[part 2 of 3: package /ECUCompositionTypes]
AUTOSAR XML (schema 00046)
package /ECUCompositionTypes
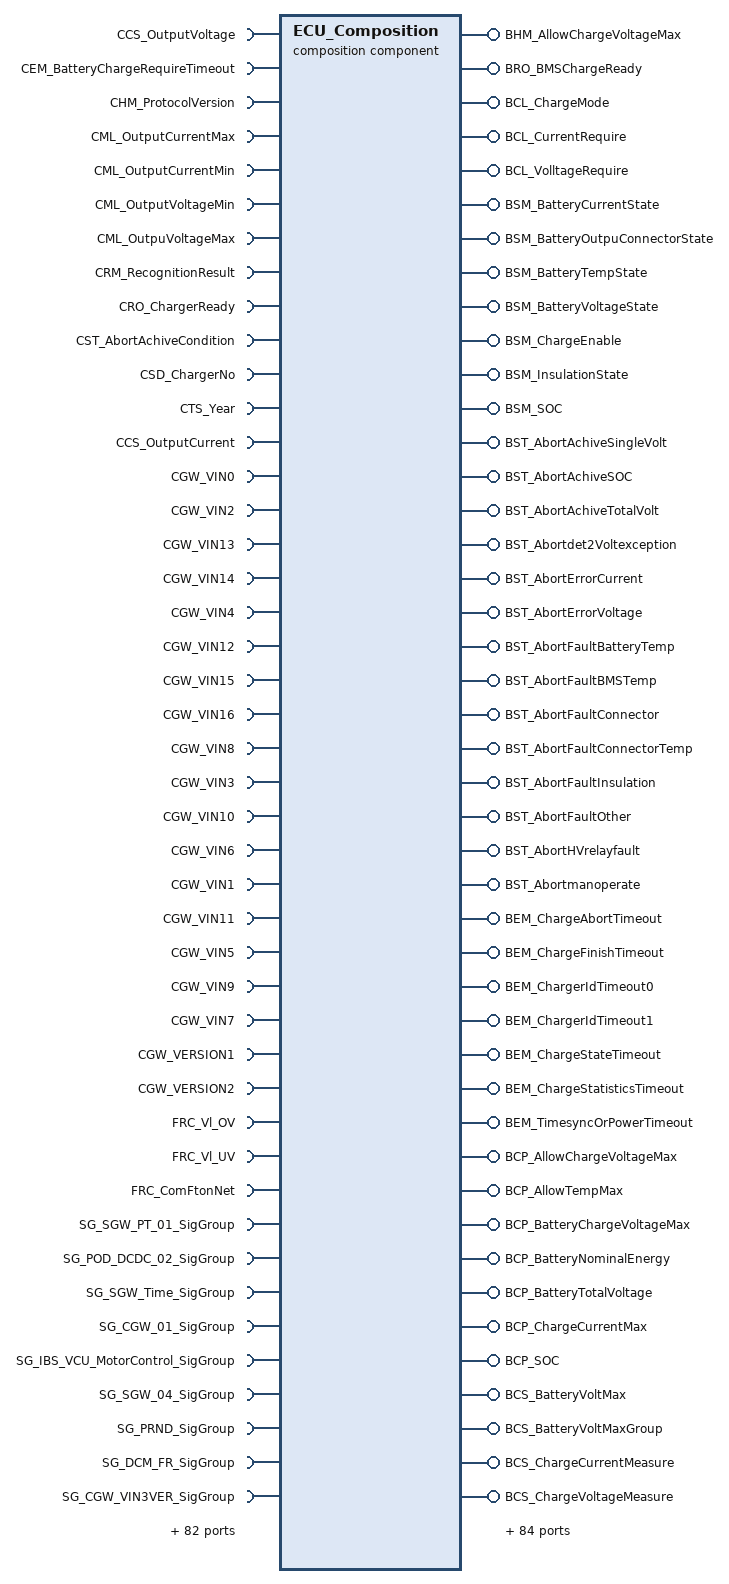
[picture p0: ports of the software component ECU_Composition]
  composition sw component type ECU_Composition
    4 x require port:
      CCS_OutputVoltage: nonqueued-receiver-com-spec{data-element=CCS_OutputVoltage, init-value=0}, required-interface=CCS_OutputVoltage
      CEM_BatteryChargeRequireTimeout: nonqueued-receiver-com-spec{data-element=CEM_BatteryChargeRequireTimeout, init-value=0}, required-interface=CEM_BatteryChargeRequireTimeout
      CHM_ProtocolVersion: nonqueued-receiver-com-spec{data-element=CHM_ProtocolVersion, init-value=0}, required-interface=CHM_ProtocolVersion
      CML_OutputCurrentMax: nonqueued-receiver-com-spec{data-element=CML_OutputCurrentMax, init-value=0}, required-interface=CML_OutputCurrentMax
    33 x provide port:
      BHM_AllowChargeVoltageMax: nonqueued-sender-com-spec{data-element=BHM_AllowChargeVoltageMax, init-value=0}, provided-interface=BHM_AllowChargeVoltageMax
      BRO_BMSChargeReady: nonqueued-sender-com-spec{data-element=BRO_BMSChargeReady, init-value=0}, provided-interface=BRO_BMSChargeReady
      BCL_ChargeMode: nonqueued-sender-com-spec{data-element=BCL_ChargeMode, init-value=0}, provided-interface=BCL_ChargeMode
      BCL_CurrentRequire: nonqueued-sender-com-spec{data-element=BCL_CurrentRequire, init-value=-400}, provided-interface=BCL_CurrentRequire
      BCL_VolltageRequire: nonqueued-sender-com-spec{data-element=BCL_VolltageRequire, init-value=0}, provided-interface=BCL_VolltageRequire
      BSM_BatteryCurrentState: nonqueued-sender-com-spec{data-element=BSM_BatteryCurrentState, init-value=0}, provided-interface=BSM_BatteryCurrentState
      BSM_BatteryOutpuConnectorState: nonqueued-sender-com-spec{data-element=BSM_BatteryOutpuConnectorState, init-value=0}, provided-interface=BSM_BatteryOutpuConnectorState
      BSM_BatteryTempState: nonqueued-sender-com-spec{data-element=BSM_BatteryTempState, init-value=0}, provided-interface=BSM_BatteryTempState
      BSM_BatteryVoltageState: nonqueued-sender-com-spec{data-element=BSM_BatteryVoltageState, init-value=0}, provided-interface=BSM_BatteryVoltageState
      BSM_ChargeEnable: nonqueued-sender-com-spec{data-element=BSM_ChargeEnable, init-value=0}, provided-interface=BSM_ChargeEnable
      BSM_InsulationState: nonqueued-sender-com-spec{data-element=BSM_InsulationState, init-value=0}, provided-interface=BSM_InsulationState
      BSM_SOC: nonqueued-sender-com-spec{data-element=BSM_SOC, init-value=0}, provided-interface=BSM_SOC
      BST_AbortAchiveSingleVolt: nonqueued-sender-com-spec{data-element=BST_AbortAchiveSingleVolt, init-value=0}, provided-interface=BST_AbortAchiveSingleVolt
      BST_AbortAchiveSOC: nonqueued-sender-com-spec{data-element=BST_AbortAchiveSOC, init-value=0}, provided-interface=BST_AbortAchiveSOC
      BST_AbortAchiveTotalVolt: nonqueued-sender-com-spec{data-element=BST_AbortAchiveTotalVolt, init-value=0}, provided-interface=BST_AbortAchiveTotalVolt
      BST_Abortdet2Voltexception: nonqueued-sender-com-spec{data-element=BST_Abortdet2Voltexception, init-value=0}, provided-interface=BST_Abortdet2Voltexception
      BST_AbortErrorCurrent: nonqueued-sender-com-spec{data-element=BST_AbortErrorCurrent, init-value=0}, provided-interface=BST_AbortErrorCurrent
      BST_AbortErrorVoltage: nonqueued-sender-com-spec{data-element=BST_AbortErrorVoltage, init-value=0}, provided-interface=BST_AbortErrorVoltage
      BST_AbortFaultBatteryTemp: nonqueued-sender-com-spec{data-element=BST_AbortFaultBatteryTemp, init-value=0}, provided-interface=BST_AbortFaultBatteryTemp
      BST_AbortFaultBMSTemp: nonqueued-sender-com-spec{data-element=BST_AbortFaultBMSTemp, init-value=0}, provided-interface=BST_AbortFaultBMSTemp
      BST_AbortFaultConnector: nonqueued-sender-com-spec{data-element=BST_AbortFaultConnector, init-value=0}, provided-interface=BST_AbortFaultConnector
      BST_AbortFaultConnectorTemp: nonqueued-sender-com-spec{data-element=BST_AbortFaultConnectorTemp, init-value=0}, provided-interface=BST_AbortFaultConnectorTemp
      BST_AbortFaultInsulation: nonqueued-sender-com-spec{data-element=BST_AbortFaultInsulation, init-value=0}, provided-interface=BST_AbortFaultInsulation
      BST_AbortFaultOther: nonqueued-sender-com-spec{data-element=BST_AbortFaultOther, init-value=0}, provided-interface=BST_AbortFaultOther
      BST_AbortHVrelayfault: nonqueued-sender-com-spec{data-element=BST_AbortHVrelayfault, init-value=0}, provided-interface=BST_AbortHVrelayfault
      BST_Abortmanoperate: nonqueued-sender-com-spec{data-element=BST_Abortmanoperate, init-value=0}, provided-interface=BST_Abortmanoperate
      BEM_ChargeAbortTimeout: nonqueued-sender-com-spec{data-element=BEM_ChargeAbortTimeout, init-value=0}, provided-interface=BEM_ChargeAbortTimeout
      BEM_ChargeFinishTimeout: nonqueued-sender-com-spec{data-element=BEM_ChargeFinishTimeout, init-value=0}, provided-interface=BEM_ChargeFinishTimeout
      BEM_ChargerIdTimeout0: nonqueued-sender-com-spec{data-element=BEM_ChargerIdTimeout0, init-value=0}, provided-interface=BEM_ChargerIdTimeout0
      BEM_ChargerIdTimeout1: nonqueued-sender-com-spec{data-element=BEM_ChargerIdTimeout1, init-value=0}, provided-interface=BEM_ChargerIdTimeout1
      BEM_ChargeStateTimeout: nonqueued-sender-com-spec{data-element=BEM_ChargeStateTimeout, init-value=0}, provided-interface=BEM_ChargeStateTimeout
      BEM_ChargeStatisticsTimeout: nonqueued-sender-com-spec{data-element=BEM_ChargeStatisticsTimeout, init-value=0}, provided-interface=BEM_ChargeStatisticsTimeout
      BEM_TimesyncOrPowerTimeout: nonqueued-sender-com-spec{data-element=BEM_TimesyncOrPowerTimeout, init-value=0}, provided-interface=BEM_TimesyncOrPowerTimeout
    7 x require port:
      CML_OutputCurrentMin: nonqueued-receiver-com-spec{data-element=CML_OutputCurrentMin, init-value=0}, required-interface=CML_OutputCurrentMin
      CML_OutputVoltageMin: nonqueued-receiver-com-spec{data-element=CML_OutputVoltageMin, init-value=0}, required-interface=CML_OutputVoltageMin
      CML_OutpuVoltageMax: nonqueued-receiver-com-spec{data-element=CML_OutpuVoltageMax, init-value=0}, required-interface=CML_OutpuVoltageMax
      CRM_RecognitionResult: nonqueued-receiver-com-spec{data-element=CRM_RecognitionResult, init-value=1}, required-interface=CRM_RecognitionResult
      CRO_ChargerReady: nonqueued-receiver-com-spec{data-element=CRO_ChargerReady, init-value=0}, required-interface=CRO_ChargerReady
      CST_AbortAchiveCondition: nonqueued-receiver-com-spec{data-element=CST_AbortAchiveCondition, init-value=0}, required-interface=CST_AbortAchiveCondition
      CSD_ChargerNo: nonqueued-receiver-com-spec{data-element=CSD_ChargerNo, init-value=1}, required-interface=CSD_ChargerNo
    37 x provide port:
      BCP_AllowChargeVoltageMax: queued-sender-com-spec=BCP_AllowChargeVoltageMax, provided-interface=BCP_AllowChargeVoltageMax
      BCP_AllowTempMax: queued-sender-com-spec=BCP_AllowTempMax, provided-interface=BCP_AllowTempMax
      BCP_BatteryChargeVoltageMax: queued-sender-com-spec=BCP_BatteryChargeVoltageMax, provided-interface=BCP_BatteryChargeVoltageMax
      BCP_BatteryNominalEnergy: queued-sender-com-spec=BCP_BatteryNominalEnergy, provided-interface=BCP_BatteryNominalEnergy
      BCP_BatteryTotalVoltage: queued-sender-com-spec=BCP_BatteryTotalVoltage, provided-interface=BCP_BatteryTotalVoltage
      BCP_ChargeCurrentMax: queued-sender-com-spec=BCP_ChargeCurrentMax, provided-interface=BCP_ChargeCurrentMax
      BCP_SOC: queued-sender-com-spec=BCP_SOC, provided-interface=BCP_SOC
      BCS_BatteryVoltMax: queued-sender-com-spec=BCS_BatteryVoltMax, provided-interface=BCS_BatteryVoltMax
      BCS_BatteryVoltMaxGroup: queued-sender-com-spec=BCS_BatteryVoltMaxGroup, provided-interface=BCS_BatteryVoltMaxGroup
      BCS_ChargeCurrentMeasure: queued-sender-com-spec=BCS_ChargeCurrentMeasure, provided-interface=BCS_ChargeCurrentMeasure
      BCS_ChargeVoltageMeasure: queued-sender-com-spec=BCS_ChargeVoltageMeasure, provided-interface=BCS_ChargeVoltageMeasure
      BCS_EstimatedTimeRemaining: queued-sender-com-spec=BCS_EstimatedTimeRemaining, provided-interface=BCS_EstimatedTimeRemaining
      BCS_SOC: queued-sender-com-spec=BCS_SOC, provided-interface=BCS_SOC
      BRM_BatteryChargeTimes: queued-sender-com-spec=BRM_BatteryChargeTimes, provided-interface=BRM_BatteryChargeTimes
      BRM_BatteryProductDay: queued-sender-com-spec=BRM_BatteryProductDay, provided-interface=BRM_BatteryProductDay
      BRM_BatteryProductMonth: queued-sender-com-spec=BRM_BatteryProductMonth, provided-interface=BRM_BatteryProductMonth
      BRM_BatteryProductYear: queued-sender-com-spec=BRM_BatteryProductYear, provided-interface=BRM_BatteryProductYear
      BRM_BatteryProperty: queued-sender-com-spec=BRM_BatteryProperty, provided-interface=BRM_BatteryProperty
      BRM_BatterySN: queued-sender-com-spec=BRM_BatterySN, provided-interface=BRM_BatterySN
      BRM_BatterySystemRatedCapacity: queued-sender-com-spec=BRM_BatterySystemRatedCapacity, provided-interface=BRM_BatterySystemRatedCapacity
      BRM_BatterySystemRatedVoltage: queued-sender-com-spec=BRM_BatterySystemRatedVoltage, provided-interface=BRM_BatterySystemRatedVoltage
      BRM_BatteryType: queued-sender-com-spec=BRM_BatteryType, provided-interface=BRM_BatteryType
      BRM_Manufacturer: queued-sender-com-spec=BRM_Manufacturer, provided-interface=BRM_Manufacturer
      BRM_ProtocolVersion: queued-sender-com-spec=BRM_ProtocolVersion, provided-interface=BRM_ProtocolVersion
      BRM_VehicleIdByte1_8: queued-sender-com-spec=BRM_VehicleIdByte1_8, provided-interface=BRM_VehicleIdByte1_8
      BRM_VehicleIdByte17: queued-sender-com-spec=BRM_VehicleIdByte17, provided-interface=BRM_VehicleIdByte17
      BRM_VehicleIdByte9_16: queued-sender-com-spec=BRM_VehicleIdByte9_16, provided-interface=BRM_VehicleIdByte9_16
      BSD_AbortSOC: nonqueued-sender-com-spec{data-element=BSD_AbortSOC, init-value=0}, provided-interface=BSD_AbortSOC
      BSD_BatteryTempMax: nonqueued-sender-com-spec{data-element=BSD_BatteryTempMax, init-value=0}, provided-interface=BSD_BatteryTempMax
      BSD_BatteryTempMin: nonqueued-sender-com-spec{data-element=BSD_BatteryTempMin, init-value=0}, provided-interface=BSD_BatteryTempMin
      BSD_BatteryVoltageMax: nonqueued-sender-com-spec{data-element=BSD_BatteryVoltageMax, init-value=0}, provided-interface=BSD_BatteryVoltageMax
      BSD_BatteryVoltageMin: nonqueued-sender-com-spec{data-element=BSD_BatteryVoltageMin, init-value=0}, provided-interface=BSD_BatteryVoltageMin
      BSM_BatteryTempMax: nonqueued-sender-com-spec{data-element=BSM_BatteryTempMax, init-value=0}, provided-interface=BSM_BatteryTempMax
      BSM_BatteryTempMaxNo: nonqueued-sender-com-spec{data-element=BSM_BatteryTempMaxNo, init-value=0}, provided-interface=BSM_BatteryTempMaxNo
      BSM_BatteryTempMin: nonqueued-sender-com-spec{data-element=BSM_BatteryTempMin, init-value=0}, provided-interface=BSM_BatteryTempMin
      BSM_BatteryTempMinNo: nonqueued-sender-com-spec{data-element=BSM_BatteryTempMinNo, init-value=0}, provided-interface=BSM_BatteryTempMinNo
      BSM_BatteryVoltageMaxNo: nonqueued-sender-com-spec{data-element=BSM_BatteryVoltageMaxNo, init-value=0}, provided-interface=BSM_BatteryVoltageMaxNo
    79 x require port:
      CTS_Year: nonqueued-receiver-com-spec{data-element=CTS_Year, init-value=0}, required-interface=CTS_Year
      CCS_OutputCurrent: nonqueued-receiver-com-spec{data-element=CCS_OutputCurrent, init-value=0}, required-interface=CCS_OutputCurrent
      CGW_VIN0: nonqueued-receiver-com-spec{data-element=CGW_VIN0, init-value=0}, required-interface=CGW_VIN0
      CGW_VIN2: nonqueued-receiver-com-spec{data-element=CGW_VIN2, init-value=0}, required-interface=CGW_VIN2
      CGW_VIN13: nonqueued-receiver-com-spec{data-element=CGW_VIN13, init-value=0}, required-interface=CGW_VIN13
      CGW_VIN14: nonqueued-receiver-com-spec{data-element=CGW_VIN14, init-value=0}, required-interface=CGW_VIN14
      CGW_VIN4: nonqueued-receiver-com-spec{data-element=CGW_VIN4, init-value=0}, required-interface=CGW_VIN4
      CGW_VIN12: nonqueued-receiver-com-spec{data-element=CGW_VIN12, init-value=0}, required-interface=CGW_VIN12
      CGW_VIN15: nonqueued-receiver-com-spec{data-element=CGW_VIN15, init-value=0}, required-interface=CGW_VIN15
      CGW_VIN16: nonqueued-receiver-com-spec{data-element=CGW_VIN16, init-value=0}, required-interface=CGW_VIN16
      CGW_VIN8: nonqueued-receiver-com-spec{data-element=CGW_VIN8, init-value=0}, required-interface=CGW_VIN8
      CGW_VIN3: nonqueued-receiver-com-spec{data-element=CGW_VIN3, init-value=0}, required-interface=CGW_VIN3
      CGW_VIN10: nonqueued-receiver-com-spec{data-element=CGW_VIN10, init-value=0}, required-interface=CGW_VIN10
      CGW_VIN6: nonqueued-receiver-com-spec{data-element=CGW_VIN6, init-value=0}, required-interface=CGW_VIN6
      CGW_VIN1: nonqueued-receiver-com-spec{data-element=CGW_VIN1, init-value=0}, required-interface=CGW_VIN1
      CGW_VIN11: nonqueued-receiver-com-spec{data-element=CGW_VIN11, init-value=0}, required-interface=CGW_VIN11
      CGW_VIN5: nonqueued-receiver-com-spec{data-element=CGW_VIN5, init-value=0}, required-interface=CGW_VIN5
      CGW_VIN9: nonqueued-receiver-com-spec{data-element=CGW_VIN9, init-value=0}, required-interface=CGW_VIN9
      CGW_VIN7: nonqueued-receiver-com-spec{data-element=CGW_VIN7, init-value=0}, required-interface=CGW_VIN7
      CGW_VERSION1: nonqueued-receiver-com-spec{data-element=CGW_VERSION1, init-value=0}, required-interface=CGW_VERSION1
      CGW_VERSION2: nonqueued-receiver-com-spec{data-element=CGW_VERSION2, init-value=0}, required-interface=CGW_VERSION2
      FRC_Vl_OV: nonqueued-receiver-com-spec{data-element=FRC_Vl_OV, init-value=1}, required-interface=FRC_Vl_OV
      FRC_Vl_UV: nonqueued-receiver-com-spec{data-element=FRC_Vl_UV, init-value=1}, required-interface=FRC_Vl_UV
      FRC_ComFtonNet: nonqueued-receiver-com-spec{data-element=FRC_ComFtonNet, init-value=1}, required-interface=FRC_ComFtonNet
      SG_SGW_PT_01_SigGroup: nonqueued-receiver-com-spec{data-element=SG_SGW_PT_01_SigGroup, init-value=fields=[IVI_AppointChargeCmd:0, IVI_ForwardVmaxlimitSw:0, IVI_LockACPlug:0, IVI_LV_LimitPop:0]}, required-interface=SG_SGW_PT_01_SigGroup
      SG_POD_DCDC_02_SigGroup: nonqueued-receiver-com-spec{data-element=SG_POD_DCDC_02_SigGroup, init-value=fields=[POD_DCDC_FaultLevel:0, POD_DCDC_Side2Overtempfault:0]}, required-interface=SG_POD_DCDC_02_SigGroup
      SG_SGW_Time_SigGroup: nonqueued-receiver-com-spec{data-element=SG_SGW_Time_SigGroup, init-value=fields=[SGW_TimeInfoDay:1, SGW_TimeInfoHour:0, SGW_TimeInfoMinute:0, SGW_TimeInfoMonth:1, SGW_TimeInfoSecond:0, SGW_TimeInfoYear:0, SGW_TimeValid:1]}, required-interface=SG_SGW_Time_SigGroup
      SG_CGW_01_SigGroup: nonqueued-receiver-com-spec{data-element=SG_CGW_01_SigGroup, uses-end-to-end-protection=true, enable-update=true, init-value=fields=[CGW_VehicleState:0, Checksum_278:0, MessageCounter_278:0]}, required-interface=SG_CGW_01_SigGroup
      SG_IBS_VCU_MotorControl_SigGroup: nonqueued-receiver-com-spec{data-element=SG_IBS_VCU_MotorControl_SigGroup, uses-end-to-end-protection=true, enable-update=true, init-value=fields=[IBS_WLTorqueIncrReq:0, IBS_WLTorqueIncrReqSts:0, IBS_WLTorqueRedReq:0, IBS_WLTorqueRedReqSts:0, Checksum_090:0, MessageCounter_090:0]}, required-interface=SG_IBS_VCU_MotorControl_SigGroup
      SG_SGW_04_SigGroup: nonqueued-receiver-com-spec{data-element=SG_SGW_04_SigGroup, init-value=fields=SGW_RemoteHVCtrlReq:0}, required-interface=SG_SGW_04_SigGroup
      SG_PRND_SigGroup: nonqueued-receiver-com-spec{data-element=SG_PRND_SigGroup, uses-end-to-end-protection=true, enable-update=true, init-value=fields=[Checksum_248:0, MessageCounter_248:0, PRND_Pbutton:0, PRND_Pbutton_FaultSts:0, PRND_RNDbutton:0, PRND_RNDbutton_FaultSts:0]}, required-interface=SG_PRND_SigGroup
      SG_DCM_FR_SigGroup: nonqueued-receiver-com-spec{data-element=SG_DCM_FR_SigGroup, init-value=fields=DCM_FR_DoorFRSts:0}, required-interface=SG_DCM_FR_SigGroup
      SG_CGW_VIN3VER_SigGroup: nonqueued-receiver-com-spec{data-element=SG_CGW_VIN3VER_SigGroup, init-value=fields=[CGW_VERSION1:0, CGW_VERSION2:0, CGW_VIN16:0]}, required-interface=SG_CGW_VIN3VER_SigGroup
      SG_BMS_ErrorInfo_SigGroup: nonqueued-receiver-com-spec{data-element=SG_BMS_ErrorInfo_SigGroup, init-value=fields=[BMS_ErrorCellHighTemp:0, BMS_ErrorCellLowTemp:0, BMS_ErrorCellOverVolt:0, BMS_ErrorCellUnderVolt:0, BMS_ErrorChaCurrentOver:0, BMS_ErrorHighSoc:0, BMS_ErrorLowSoc:0, BMS_ErrorPreChaFailed:0, BMS_ErrorRelay:0, BMS_ThermalRunawayFault:0]}, required-interface=SG_BMS_ErrorInfo_SigGroup
      SG_CGW_VIN2_SigGroup: nonqueued-receiver-com-spec{data-element=SG_CGW_VIN2_SigGroup, init-value=fields=[CGW_VIN8:0, CGW_VIN9:0, CGW_VIN10:0, CGW_VIN11:0, CGW_VIN12:0, CGW_VIN13:0, CGW_VIN14:0, CGW_VIN15:0]}, required-interface=SG_CGW_VIN2_SigGroup
      SG_BMS_status_02_SigGroup: nonqueued-receiver-com-spec{data-element=SG_BMS_status_02_SigGroup, init-value=fields=[BMS_BattCurr:0, BMS_BattVolt:0, BMS_Heatcurrent:0]}, required-interface=SG_BMS_status_02_SigGroup
      SG_SGW_17_SigGroup: nonqueued-receiver-com-spec{data-element=SG_SGW_17_SigGroup, init-value=fields=SGW_BLESystemReadyReq:0}, required-interface=SG_SGW_17_SigGroup
      SG_BMS_PRO_SigGroup: nonqueued-receiver-com-spec{data-element=SG_BMS_PRO_SigGroup, init-value=fields=[BMS_BatProDatDay:0, BMS_BatProDatMonth:0, BMS_BatProDatYear:0]}, required-interface=SG_BMS_PRO_SigGroup
      SG_ACU_01_SigGroup: nonqueued-receiver-com-spec{data-element=SG_ACU_01_SigGroup, uses-end-to-end-protection=true, enable-update=true, init-value=fields=[ACU_YawRate:30000, ACU_YawRateStatus:0, Checksum_0F5:0, MessageCounter_0F5:0]}, required-interface=SG_ACU_01_SigGroup
      SG_ADCU_DA_SigGroup: nonqueued-receiver-com-spec{data-element=SG_ADCU_DA_SigGroup, uses-end-to-end-protection=true, enable-update=true, init-value=fields=[ADCU_DA_Mode:0, Checksum_0E6:0, MessageCounter_0E6:0]}, required-interface=SG_ADCU_DA_SigGroup
      SG_POD_Status_02_SigGroup: nonqueued-receiver-com-spec{data-element=SG_POD_Status_02_SigGroup, init-value=fields=[POD_DCPortInletTempAValid:0, POD_DCPortInletTempBValid:0, POD_DCPosRelayState:1]}, required-interface=SG_POD_Status_02_SigGroup
      SG_CGW_VIN1_SigGroup: nonqueued-receiver-com-spec{data-element=SG_CGW_VIN1_SigGroup, init-value=fields=[CGW_VIN0:0, CGW_VIN1:0, CGW_VIN2:0, CGW_VIN3:0, CGW_VIN4:0, CGW_VIN5:0, CGW_VIN6:0, CGW_VIN7:0]}, required-interface=SG_CGW_VIN1_SigGroup
      SG_IVI_01_SigGroup: nonqueued-receiver-com-spec{data-element=SG_IVI_01_SigGroup, uses-end-to-end-protection=true, enable-update=true, init-value=fields=IVI_GearRequest:0}, required-interface=SG_IVI_01_SigGroup
      SG_MCU_02_SigGroup: nonqueued-receiver-com-spec{data-element=SG_MCU_02_SigGroup, init-value=fields=[MCU_BDmpCActv:0, MCU_VCUWorkMode:0]}, required-interface=SG_MCU_02_SigGroup
      SG_MCU_Temperature_02_SigGroup: nonqueued-receiver-com-spec{data-element=SG_MCU_Temperature_02_SigGroup, init-value=fields=MCU_TempStatus:0}, required-interface=SG_MCU_Temperature_02_SigGroup
      SG_BMS_Charge_01_SigGroup: nonqueued-receiver-com-spec{data-element=SG_BMS_Charge_01_SigGroup, init-value=fields=[BMS_AllowChagCurrent:0, BMS_MaxChagVoltage:0, BMS_RemChagTime:0]}, required-interface=SG_BMS_Charge_01_SigGroup
      SG_CGW_02_SigGroup: nonqueued-receiver-com-spec{data-element=SG_CGW_02_SigGroup, init-value=fields=[CGW_ADCUSts:0, CGW_BCMSts:0, CGW_BMSSts:0, CGW_CBMSts:0, CGW_CGWSts:0, CGW_DCM_FLSts:0, CGW_DCM_FRSts:0, CGW_DCM_RLSts:0, CGW_DCM_RRSts:0, CGW_HLLSts:0, CGW_HLRSts:0, CGW_HOD_HeatingSts:0, CGW_IVISts:0, CGW_MFP_FCSts:0, CGW_MFP_RCSts:0, CGW_PRNDSts:0, CGW_SCU_LSts:0, CGW_SCU_RSts:0, CGW_SGWSts:0, CGW_SwichesSts:0, CGW_SWPSts:0, CGW_VCUSts:0]}, required-interface=SG_CGW_02_SigGroup
      SG_POD_OBC_STATUS_02_SigGroup: nonqueued-receiver-com-spec{data-element=SG_POD_OBC_STATUS_02_SigGroup, init-value=fields=[POD_OBC_ChrgOutpPwrAvl:0, POD_OBC_OutputDCChargeCurrent:0, POD_OBC_OutputDCChargeVoltage:0]}, required-interface=SG_POD_OBC_STATUS_02_SigGroup
      SG_BMS_TCU_SigGroup: nonqueued-receiver-com-spec{data-element=SG_BMS_TCU_SigGroup, init-value=fields=[BMS_AllowCellTemperature:255, BMS_KeepWarmRequest:0, BMS_KeepWarmStatus:0, BMS_RTC_Request:0]}, required-interface=SG_BMS_TCU_SigGroup
      SG_ADCU_APS_02_SigGroup: nonqueued-receiver-com-spec{data-element=SG_ADCU_APS_02_SigGroup, init-value=fields=ADCU_RemoteParkingMode:0}, required-interface=SG_ADCU_APS_02_SigGroup
      SG_MCU_FailureCode_SigGroup: nonqueued-receiver-com-spec{data-element=SG_MCU_FailureCode_SigGroup, uses-end-to-end-protection=true, enable-update=true, init-value=fields=[Checksum_253:0, MCU_FaultLevel:0, MessageCounter_253:0]}, required-interface=SG_MCU_FailureCode_SigGroup
      SG_IVI_OdometerInfor_SigGroup: nonqueued-receiver-com-spec{data-element=SG_IVI_OdometerInfor_SigGroup, init-value=fields=IVI_OdometerInfor:0}, required-interface=SG_IVI_OdometerInfor_SigGroup
      SG_DCM_RL_SigGroup: nonqueued-receiver-com-spec{data-element=SG_DCM_RL_SigGroup, uses-end-to-end-protection=true, enable-update=true, init-value=fields=DCM_RL_DoorRLSts:0}, required-interface=SG_DCM_RL_SigGroup
      SG_MCU_Temperature_01_SigGroup: nonqueued-receiver-com-spec{data-element=SG_MCU_Temperature_01_SigGroup, init-value=fields=MCU_IGBTTempMax:0}, required-interface=SG_MCU_Temperature_01_SigGroup
      SG_POD_DCDC_01_SigGroup: nonqueued-receiver-com-spec{data-element=SG_POD_DCDC_01_SigGroup, init-value=fields=[POD_DCDC_HVInputCurrent:0, POD_DCDC_HVInputVoltage:0, POD_DCDC_WorkMode:0]}, required-interface=SG_POD_DCDC_01_SigGroup
      SG_BMS_BatInfor_02_SigGroup: nonqueued-receiver-com-spec{data-element=SG_BMS_BatInfor_02_SigGroup, init-value=fields=BMS_BatSupName:8 x 0}, required-interface=SG_BMS_BatInfor_02_SigGroup
      SG_BMS_status_03_SigGroup: nonqueued-receiver-com-spec{data-element=SG_BMS_status_03_SigGroup, init-value=fields=[BMS_DisplaySOC:0, BMS_LinkVoltage:0, BMS_PackVoltage:0]}, required-interface=SG_BMS_status_03_SigGroup
      SG_DCM_FR_02_SigGroup: nonqueued-receiver-com-spec{data-element=SG_DCM_FR_02_SigGroup, init-value=fields=[DCM_FR_AmbientTemperature:70, DCM_FR_AmbientTemperatureValid:0]}, required-interface=SG_DCM_FR_02_SigGroup
      SG_IBS_Torque_SigGroup: nonqueued-receiver-com-spec{data-element=SG_IBS_Torque_SigGroup, uses-end-to-end-protection=true, enable-update=true, init-value=fields=[Checksum_0B9:0, IBS_RBSStatus:0, IBS_TargetGearReq:0, IBS_WLTorqueAPSReq:0, IBS_WLTorqueAPSReqValid:0, IBS_WLTorqueRBSReq:0, IBS_WLTorqueRBSReqValid:0, MessageCounter_0B9:0, IBS_VCU_DecelerationReqActive:0]}, required-interface=SG_IBS_Torque_SigGroup
      SG_POD_OBC_CHRGSTATION_SigGroup: nonqueued-receiver-com-spec{data-element=SG_POD_OBC_CHRGSTATION_SigGroup, init-value=fields=[POD_OBC_CCCurrentLimit:0, POD_OBC_CCStatus:0, POD_OBC_ChargCapacibility:0, POD_OBC_CPCurrentLimit:0, POD_OBC_CPDuty:0, POD_OBC_CPStatus:0, POD_OBC_EMLockState:0, POD_OBC_OBCMaxPermOutpCrrt:0, POD_OBC_S2State:1, POD_OBC_WorkMode:0]}, required-interface=SG_POD_OBC_CHRGSTATION_SigGroup
      SG_POD_OBC_STATUS_03_SigGroup: nonqueued-receiver-com-spec{data-element=SG_POD_OBC_STATUS_03_SigGroup, init-value=fields=[POD_OBC_FaultLevel:0, POD_OBC_Side1Overtempfault:0, POD_OBC_Side2Overtempfault:0, POD_OBC_PrimarySideTemp:0, POD_OBC_SecondarySideTemp:0]}, required-interface=SG_POD_OBC_STATUS_03_SigGroup
      SG_POD_OBC_STATUS_04_SigGroup: nonqueued-receiver-com-spec{data-element=SG_POD_OBC_STATUS_04_SigGroup, init-value=fields=[POD_OBC_InputACCurrent_R:0, POD_OBC_InputACCurrent_S:0, POD_OBC_InputACCurrent_T:0, POD_OBC_InputACVoltage_R:0, POD_OBC_InputACVoltage_S:0, POD_OBC_InputACVoltage_T:0]}, required-interface=SG_POD_OBC_STATUS_04_SigGroup
      SG_ACU_02_SigGroup: nonqueued-receiver-com-spec{data-element=SG_ACU_02_SigGroup, uses-end-to-end-protection=true, enable-update=true, init-value=fields=[ACU_LatA:4905, ACU_LatAStatus:0, ACU_LgtA:4905, ACU_LgtAStatus:0, Checksum_0F6:0, MessageCounter_0F6:0]}, required-interface=SG_ACU_02_SigGroup
      SG_POD_Status_01_SigGroup: nonqueued-receiver-com-spec{data-element=SG_POD_Status_01_SigGroup, init-value=fields=[POD_DCFCVoltage:0, POD_DCInletTempA:0, POD_DCInletTempB:0]}, required-interface=SG_POD_Status_01_SigGroup
      SG_BMS_VersionInfor_SigGroup: nonqueued-receiver-com-spec{data-element=SG_BMS_VersionInfor_SigGroup, init-value=fields=[BMS_BatProRights:0, BMS_ComVersion:0]}, required-interface=SG_BMS_VersionInfor_SigGroup
      SG_BMS_BatInfor_01_SigGroup: nonqueued-receiver-com-spec{data-element=SG_BMS_BatInfor_01_SigGroup, init-value=fields=[BMS_BatType:0, BMS_CellNumbers:0, BMS_RatBatVoltage:0, BMS_RatCapacity:0, BMS_RatEnergy:0]}, required-interface=SG_BMS_BatInfor_01_SigGroup
      SG_MCU_DeratingStatus_SigGroup: nonqueued-receiver-com-spec{data-element=SG_MCU_DeratingStatus_SigGroup, init-value=fields=[MCU_TrqAbsMax:1023, MCU_TrqAbsMin:1023]}, required-interface=SG_MCU_DeratingStatus_SigGroup
      SG_SGW_VCU_01_SigGroup: nonqueued-receiver-com-spec{data-element=SG_SGW_VCU_01_SigGroup, init-value=fields=[IVI_DriveModeSet:0, IVI_DschrgOnOffSet:0, IVI_ForwardVmaxAllowed:0, IVI_MaxChrgSocSet:254, IVI_V2LidisSet:254]}, required-interface=SG_SGW_VCU_01_SigGroup
      SG_SGW_IBS_01_SigGroup: nonqueued-receiver-com-spec{data-element=SG_SGW_IBS_01_SigGroup, uses-end-to-end-protection=true, enable-update=true, init-value=fields=[IVI_BrakeCompensateCmd:0, IVI_CRLevelSet:0]}, required-interface=SG_SGW_IBS_01_SigGroup
      SG_DCM_RR_SigGroup: nonqueued-receiver-com-spec{data-element=SG_DCM_RR_SigGroup, uses-end-to-end-protection=true, enable-update=true, init-value=fields=DCM_RR_DoorRRSts:0}, required-interface=SG_DCM_RR_SigGroup
      SG_BMS_DIRelayState_SigGroup: nonqueued-receiver-com-spec{data-element=SG_BMS_DIRelayState_SigGroup, init-value=fields=[BMS_NegRelayStatus:0, BMS_PosRelayStatus:0, BMS_PreRelayStatus:0, BMS_PTC_VoltageValue:0, BMS_PTCRelayStatus:0]}, required-interface=SG_BMS_DIRelayState_SigGroup
      SG_TCU_02_SigGroup: nonqueued-receiver-com-spec{data-element=SG_TCU_02_SigGroup, init-value=fields=[TCU_HVCHHighVoltage:0, TCU_HVCHHVDCCurrent:0]}, required-interface=SG_TCU_02_SigGroup
      SG_SGW_16_SigGroup: nonqueued-receiver-com-spec{data-element=SG_SGW_16_SigGroup, init-value=fields=IVI_VrState:0}, required-interface=SG_SGW_16_SigGroup
      SG_APTC_TCU_SigGroup: nonqueued-receiver-com-spec{data-element=SG_APTC_TCU_SigGroup, init-value=fields=APTC_PowerConsumption:0}, required-interface=SG_APTC_TCU_SigGroup
      SG_TCU_01_SigGroup: nonqueued-receiver-com-spec{data-element=SG_TCU_01_SigGroup, init-value=fields=[TCU_HVPwrState:0, TCU_TMSFaultLevel:0, TCU_TMSTotalPwrCnsmp:0, TCU_TMSTotoalPwrReq:0]}, required-interface=SG_TCU_01_SigGroup
      SG_BMS_BatInfor_03_SigGroup: nonqueued-receiver-com-spec{data-element=SG_BMS_BatInfor_03_SigGroup, init-value=fields=BMS_RemainCapacity:0}, required-interface=SG_BMS_BatInfor_03_SigGroup
      SG_BMS_Charge_03_SigGroup: nonqueued-receiver-com-spec{data-element=SG_BMS_Charge_03_SigGroup, init-value=fields=[BMS_BatChagSum:0, BMS_SingChgkwh:0, BMS_SumChgkwh:0]}, required-interface=SG_BMS_Charge_03_SigGroup
      SG_BMS_Charge_02_SigGroup: nonqueued-receiver-com-spec{data-element=SG_BMS_Charge_02_SigGroup, init-value=fields=[BMS_AbortAchivesetValue:0, BMS_AbortAchiveSingleVolt:0, BMS_AbortAchiveTotalVolt:0, BMS_AbortErrorCurrent:0, BMS_AbortErrorVoltage:0, BMS_AbortFaultBatteryTemp:0, BMS_AbortFaultBMSTemp:0, BMS_ChagComplete:0, BMS_ChargeRequest:0, BMS_DCChgMode:0]}, required-interface=SG_BMS_Charge_02_SigGroup
      SG_EVCOM_State_01_SigGroup: nonqueued-receiver-com-spec{data-element=SG_EVCOM_State_01_SigGroup, init-value=fields=[EVCOM_CompActlCnsmpCur:0, EVCOM_CompActlPwrCnsmp:0]}, required-interface=SG_EVCOM_State_01_SigGroup
    19 x provide port:
      SG_VCU_HMIsignals_02_SigGroup: nonqueued-sender-com-spec{data-element=SG_VCU_HMIsignals_02_SigGroup, uses-end-to-end-protection=true, init-value=fields=[Checksum_318:0, MessageCounter_318:0, VCU_DischargeEndSoc:50, VCU_Display_Cur:0, VCU_Display_Power:0, VCU_ForwardVmaxAllowed:0, VCU_maxChargeSOC:255, VCU_MCU_FaultLampReq:0, VCU_SystemReady:0]}, provided-interface=SG_VCU_HMIsignals_02_SigGroup
      SG_VCU_TCU_SigGroup: nonqueued-sender-com-spec{data-element=SG_VCU_TCU_SigGroup, init-value=fields=[VCU_RequestedModeTCU:0, VCU_TCUPowerAllowed:0]}, provided-interface=SG_VCU_TCU_SigGroup
      SG_VCU_IBS_01_SigGroup: nonqueued-sender-com-spec{data-element=SG_VCU_IBS_01_SigGroup, uses-end-to-end-protection=true, init-value=fields=[Checksum_094:0, MessageCounter_094:0, VCU_MotorActualTorque:0, VCU_MotorActualTorqueValid:0, VCU_OPStandstillReq:0, VCU_WheelTrqACT:0, VCU_WheelTrqACTValid:0]}, provided-interface=SG_VCU_IBS_01_SigGroup
      SG_VCU_03_SigGroup: nonqueued-sender-com-spec{data-element=SG_VCU_03_SigGroup, init-value=fields=[VCU_BrakeCompensateStatus:0, VCU_ChargeProcessComment:0, VCU_DCFCCurrent:0, VCU_EnergyV2L:0, VCU_MemoryChargeFault:0]}, provided-interface=SG_VCU_03_SigGroup
      SG_VCU_BMS_SigGroup: nonqueued-sender-com-spec{data-element=SG_VCU_BMS_SigGroup, uses-end-to-end-protection=true, init-value=fields=[Checksum_0D1:0, MessageCounter_0D1:0, VCU_ActDriveMode:0, VCU_BMSTargetThermLevel:0, VCU_DrvModSwitchWarn:0, VCU_HVStatus:0, VCU_LimitLevel:0, VCU_RegenBrakeLightRequest:0, VCU_RegenBrakeLightReqVld:0, VCU_RequestedModeBMS:0, VCU_BMS_Control_of_PosRelay:0, VCU_ChargeStatus:0, VCU_IsoMeasurementSwitch:1]}, provided-interface=SG_VCU_BMS_SigGroup
      SG_VCU_DiagInfor_SigGroup: nonqueued-sender-com-spec{data-element=SG_VCU_DiagInfor_SigGroup, init-value=fields=VCU_DTC_Number:0}, provided-interface=SG_VCU_DiagInfor_SigGroup_2
      SG_VCU_05_SigGroup: nonqueued-sender-com-spec{data-element=SG_VCU_05_SigGroup, init-value=fields=[VCU_MaximumOutputCurrent:0, VCU_MaximumOutputVoltage:0, VCU_MinimumOutputCurrent:0, VCU_MinimumOutputVoltage:0]}, provided-interface=SG_VCU_05_SigGroup
      SG_VCU_Chassis_01_SigGroup: nonqueued-sender-com-spec{data-element=SG_VCU_Chassis_01_SigGroup, uses-end-to-end-protection=true, init-value=fields=[Checksum_0D3:0, MessageCounter_0D3:0, VCU_ADASOverride:0, VCU_APSTorqueRequestActive:0, VCU_APSTorqueRequestAvailable:0, VCU_BrakeCompensateWarn:0, VCU_DecelerationReq:0, VCU_DecelerationReqactive:0, VCU_DriverTorqueRequest:0, VCU_EnergyManagementWarn:0, VCU_RegenTorqueCap:0, VCU_RegenTorqueCapValid:0, VCU_RegStatus:0, VCU_TorqueRequestActive:0, VCU_TorqueRequestAvailable:0]}, provided-interface=SG_VCU_Chassis_01_SigGroup
      SG_VCU_MCU_02_SigGroup: nonqueued-sender-com-spec{data-element=SG_VCU_MCU_02_SigGroup, init-value=fields=[VCU_MaxSpdLimit:32767, VCU_MCUActHeatPwr:0, VCU_MotorSpdReq:32767]}, provided-interface=SG_VCU_MCU_02_SigGroup
      SG_VCU_SynReq_01_SigGroup: nonqueued-sender-com-spec{data-element=SG_VCU_SynReq_01_SigGroup, init-value=fields=VCU_SynRequest:16777215}, provided-interface=SG_VCU_SynReq_01_SigGroup
      SG_VCU_MCU_05_SigGroup: nonqueued-sender-com-spec{data-element=SG_VCU_MCU_05_SigGroup, init-value=fields=[VCU_MaxTorqueGradient:0, VCU_MaxTorqueLimit:0, VCU_MinTorqueLimit:0, VCU_CreepTorque:0, VCU_SpdLimitActTorque:0]}, provided-interface=SG_VCU_MCU_05_SigGroup
      SG_VCU_POD_SigGroup: nonqueued-sender-com-spec{data-element=SG_VCU_POD_SigGroup, init-value=fields=[VCU_Enable_DC_Relay:1, VCU_EnableOBC:0, VCU_OBC_ChargeCurrentCommand:0, VCU_OBC_Control_of_em_lock:1, VCU_OBC_Control_of_S2_SW:1]}, provided-interface=SG_VCU_POD_SigGroup
      SG_VCU_06_SigGroup: nonqueued-sender-com-spec{data-element=SG_VCU_06_SigGroup, init-value=fields=[VCU_ChargeEnergy:0, VCU_ChargeTime:0, VCU_DisChgPowerLimit:0, VCU_DisplayMileage:0, VCU_MCUPower:0, VCU_PermitPackPTC:0]}, provided-interface=SG_VCU_06_SigGroup
      SG_VCU_02_SigGroup: nonqueued-sender-com-spec{data-element=SG_VCU_02_SigGroup, init-value=fields=[VCU_BS_IBSBatSOC:80, VCU_BS_LV_Batt:0, VCU_BS_Current:0, VCU_BS_IndicatorSts:0, VCU_WakeUpStatus:0]}, provided-interface=SG_VCU_02_SigGroup
      SG_VCU_04_SigGroup: nonqueued-sender-com-spec{data-element=SG_VCU_04_SigGroup, init-value=fields=[VCU_ForwardVmaxlimitStatus:0, VCU_ManuallyUnlockComment:0]}, provided-interface=SG_VCU_04_SigGroup
      SG_VCU_PlugInChrgInfo_SigGroup: nonqueued-sender-com-spec{data-element=SG_VCU_PlugInChrgInfo_SigGroup, init-value=fields=[VCU_ChargeEndReason:0, VCU_DischargeEndReason:0, VCU_HVConnectFault:0, VCU_RemainChrgTime:0]}, provided-interface=SG_VCU_PlugInChrgInfo_SigGroup
      SG_VCU_DCDC_SigGroup: nonqueued-sender-com-spec{data-element=SG_VCU_DCDC_SigGroup, init-value=fields=[VCU_DCDCPowerLimit:0, VCU_RequestedModeDCDC:0, VCU_VoltageDemandLV:0]}, provided-interface=SG_VCU_DCDC_SigGroup
      SG_VCU_AccPedal_SigGroup: nonqueued-sender-com-spec{data-element=SG_VCU_AccPedal_SigGroup, uses-end-to-end-protection=true, init-value=fields=[Checksum_0D2:0, MessageCounter_0D2:0, VCU_AccelerationPedal:0, VCU_AccelerationPedalValid:0, VCU_EPBReq:0, VCU_Kickdown:0, VCU_TargetGear:0, VCU_VehicleSpeed:0, VCU_VehicleSpeedValid:0, VCU_VLCTorqueRequestActive:0, VCU_VLCTorqueRequestAvailable:0, VCU_VirtualACPedal:0, VCU_VirtualACPedalValid:0]}, provided-interface=SG_VCU_AccPedal_SigGroup
      SG_VCU_HMIsignals_01_SigGroup: nonqueued-sender-com-spec{data-element=SG_VCU_HMIsignals_01_SigGroup, uses-end-to-end-protection=true, init-value=fields=[Checksum_317:0, MessageCounter_317:0, VCU_CriSysFailure:0, VCU_DCDCFail:0, VCU_DriveMotOvrTemp:0, VCU_HVBatCriFail:0, VCU_HVBatOvrTemp:0, VCU_HVILError:0, VCU_HVInsulResFault:0, VCU_InvldGearSel:0, VCU_LimpHome:0, VCU_PlugStatus:0, VCU_ReachLimitStd:0, VCU_MileagelowRemind:0]}, provided-interface=SG_VCU_HMIsignals_01_SigGroup
    require port SG_MCU_01_SigGroup: nonqueued-receiver-com-spec{data-element=SG_MCU_01_SigGroup, uses-end-to-end-protection=true, enable-update=true, init-value=fields=[MCU_ActTrqValid:0, MCU_ActualSpeed:32767, MCU_ActualSpeedValid:0, MCU_ActualTorque:1023, MCU_IsCurr:1023, MCU_UdcCurr:0, Checksum_098:0, MessageCounter_098:0]}, required-interface=SG_MCU_01_SigGroup_2
    provide port SG_VCU_MCU_03_SigGroup: nonqueued-sender-com-spec{data-element=SG_VCU_MCU_03_SigGroup, uses-end-to-end-protection=true, init-value=fields=[Checksum_095:0, MessageCounter_095:0, VCU_ActualGear:0, VCU_BrakepedalStatus:0, VCU_KL15eOn:0, VCU_MCUDesiredTorque:0, VCU_MCUSurgeDamperState:0, VCU_PWTErrorLevel:0, VCU_RequestedModeMCU:0, VCU_TCSActive:0, VCU_TrqThresholdDampgCtl:0]}, provided-interface=SG_VCU_MCU_03_SigGroup_1
    23 x require port:
      SG_SGW_FVSynchronization_01_SigGrou_1: nonqueued-receiver-com-spec{data-element=SG_SGW_FVSynchronization_01_SigGrou, init-value=fields=SGW_TripCounter:0}, required-interface=SG_SGW_FVSynchronization_01_SigGrou_1
      SG_ACU_info_SigGroup_1: nonqueued-receiver-com-spec{data-element=SG_ACU_info_SigGroup, uses-end-to-end-protection=true, enable-update=true, init-value=fields=[ACU_CrashOutputSts:1, ACU_CrashOutputStsValid:1, ACU_DriverWarningLampSts:0, ACU_PassengerAirbagSts:0, ACU_PassengerWarningLampSts:0, MessageCounter_097:0, Checksum_097:0, ACU_DriverSeatBeltSts:0, ACU_DriverSeatBeltStsValid:0, ACU_PassengerSeatBeltSts:0, ACU_PassengerSeatBeltStsValid:0, ACU_PassengerSts:0, ACU_RLSeatBeltStatusValid:0, ACU_RRSeatBeltStatusValid:0, ACU_SecondLeftSeatBeltSts:0, ACU_SecondLeftSts:0, ACU_SecondRightSeatBeltSts:0, ACU_SecondRightSts:0, ACU_WarningLampSts:0]}, required-interface=SG_ACU_info_SigGroup_1
      SG_ADCU_ACC_02_SigGroup_1: nonqueued-receiver-com-spec{data-element=SG_ADCU_ACC_02_SigGroup, uses-end-to-end-protection=true, enable-update=true, init-value=fields=[ADCU_ACC_Mode:0, Checksum_0E0:0, MessageCounter_0E0:0, ADCU_ACCDA_HandsOFF_Warning:0, ADCU_ACCDA_SYS_Failure:0]}, required-interface=SG_ADCU_ACC_02_SigGroup_1
      SG_ADCU_APS_01_SigGroup_1: nonqueued-receiver-com-spec{data-element=SG_ADCU_APS_01_SigGroup, uses-end-to-end-protection=true, enable-update=true, init-value=fields=[Checksum_0E4:0, MessageCounter_0E4:0, ADCU_Parking_Mode:0, ADCU_APS_Stop_Req:0, ADCU_APSComfBrkReq:0, ADCU_APSCrlModeReq:0, ADCU_APSCrlReq:0, ADCU_APSCrlTypReq:0, ADCU_APSDistanceStop:0, ADCU_APSMaxSpeedReq:0, ADCU_Parking_CtrlSts:0, ADCU_TargetGear:0]}, required-interface=SG_ADCU_APS_01_SigGroup_1
      SG_BCM_05_SigGroup_1: nonqueued-receiver-com-spec{data-element=SG_BCM_05_SigGroup, uses-end-to-end-protection=true, enable-update=true, init-value=fields=[BCM_FLSeatBeltRemindReq:0, BCM_FRSeatBeltRemindReq:0, BCM_RLSeatBeltRemindReq:0, BCM_RRSeatBeltRemindReq:0, Checksum_33A:0, MessageCounter_33A:0, BCM_AutoCloseWinFunSts:0, BCM_ChrgFlapLockSts:0, BCM_DomeLampAutoSts:1, BCM_DomeLampBrightSts:1, BCM_FrontWiperModeSts:0, BCM_GearTimesSts:5, BCM_KeyNotInCarRemind:0, BCM_PuddleLiReq:1, BCM_WelLightshowOnOffSts:2, BCM_WiperServiceSts:0, BCM_WiperWorkingSts:0]}, required-interface=SG_BCM_05_SigGroup_1
      SG_BCM_06_SigGroup_1: nonqueued-receiver-com-spec{data-element=SG_BCM_06_SigGroup, uses-end-to-end-protection=true, enable-update=true, init-value=fields=[BCM_PepsPowerMode:0, checksum_271:0, MessageCounter_271:0, BCM_PowerOffDisplayReq:0]}, required-interface=SG_BCM_06_SigGroup_1
      SG_ADCU_AEB_01_SigGroup: nonqueued-receiver-com-spec{data-element=SG_ADCU_AEB_01_SigGroup, uses-end-to-end-protection=true, enable-update=true, init-value=fields=[ADCU_AEB_State:0, Checksum_0E2:0, MessageCounter_0E2:0, ADCU_AEB_AWB_Level:0, ADCU_AEB_AWB_Req:0, ADCU_AEB_Decel_Cmd:-16, ADCU_AEB_Prefill_CMD:0, ADCU_AEB_Stop_Req:0, ADCU_AEBReq:0, ADCU_AEBWarningSts:0, ADCU_FCW_State:0]}, required-interface=SG_ADCU_AEB_01_SigGroup_2
      SG_BMS_CellTemp_SigGroup_1: nonqueued-receiver-com-spec{data-element=SG_BMS_CellTemp_SigGroup, enable-update=true, init-value=fields=[BMS_AverageCellTemp:255, BMS_MaxCellTemp:255, BMS_MaxCellTempNO:0, BMS_MinCellTemp:255, BMS_MinCellTempNO:0, BMS_MinCellTempModuleNO:0]}, required-interface=SG_BMS_CellTemp_SigGroup_1
      SG_BMS_CellVoltage_SigGroup_1: nonqueued-receiver-com-spec{data-element=SG_BMS_CellVoltage_SigGroup, init-value=fields=[BMS_MaxCellVoltage:0, BMS_MaxCellVoltageModuleNO:0, BMS_MaxCellVoltageNO:0, BMS_MinCellVoltage:0]}, required-interface=SG_BMS_CellVoltage_SigGroup_1
      SG_BMS_status_01_SigGroup_1: nonqueued-receiver-com-spec{data-element=SG_BMS_status_01_SigGroup, uses-end-to-end-protection=true, enable-update=true, init-value=fields=[BMS_ChargeStatus:0, BMS_ErrorIsolationSingleLow:0, BMS_ErrorLevel:0, BMS_HVinterlockState:0, BMS_InsulationDetectionStatus:0, BMS_PreCharge:0, BMS_SOH:0, BMS_SysRegInsulationValue:0, BMS_ThrmlRunawayFault:0, BMS_WorkMode:0, Checksum_0C1:0, MessageCounter_0C1:0, BMS_BalancingStatus:0, BMS_RunHeatStatus:0]}, required-interface=SG_BMS_status_01_SigGroup_1
      SG_DCM_FL_02_SigGroup_1: nonqueued-receiver-com-spec{data-element=SG_DCM_FL_02_SigGroup, uses-end-to-end-protection=true, enable-update=true, init-value=fields=[Checksum_28A:0, DCM_FL_DoorFLSts:0, MessageCounter_28A:0, DCM_FL_FRWndSwA:0, DCM_FL_LeftMirrorHorizontalPos:254, DCM_FL_LeftMirrorVerticalPos:254, DCM_FL_MirrorAutoFoldUnfoldSts:0, DCM_FL_MirrorAutoTurnDownSts:0, DCM_FL_MirrorFold_UnfoldSts:0, DCM_FL_RearmirrorHeatingSts:0, DCM_FL_RLWndSwA:0, DCM_FL_RRWndSwA:0]}, required-interface=SG_DCM_FL_02_SigGroup_1
      SG_IBS_APS_SigGroup_1: nonqueued-receiver-com-spec{data-element=SG_IBS_APS_SigGroup, uses-end-to-end-protection=true, enable-update=true, init-value=fields=[IBS_APSTrqReqActive:0, Checksum_0B7:0, MessageCounter_0B7:0, IBS_APS_Avl:0, IBS_APSComfortAvl:0, IBS_APSCrlReqEcho:0, IBS_APSEmergenyAvl:0, IBS_APSModeEcho:0, IBS_BrakeTypEcho:0]}, required-interface=SG_IBS_APS_SigGroup_1
      SG_IBS_Status_02_SigGroup_1: nonqueued-receiver-com-spec{data-element=SG_IBS_Status_02_SigGroup, uses-end-to-end-protection=true, enable-update=true, init-value=fields=[Checksum_0B3:0, IBS_AEBActive:0, IBS_EPBFailureLamp:0, IBS_EPBFunctionLamp:0, IBS_EPBworkingSts:0, IBS_TCSActive:0, IBS_VDCActive:0, MessageCounter_0B3:0, IBS_EPBControllerSts:0, IBS_AEBAvailable:0, IBS_AVHAvailable:0, IBS_AWBActive:0, IBS_AWBAvailable:0, IBS_BrakeLightRequest:0, IBS_HazWarnReq:0, IBS_HDCAvailable:0, IBS_HHCActive:0, IBS_HHCAvailable:0]}, required-interface=SG_IBS_Status_02_SigGroup_1
      SG_IBS_Status_03_SigGroup_1: nonqueued-receiver-com-spec{data-element=SG_IBS_Status_03_SigGroup, uses-end-to-end-protection=true, enable-update=true, init-value=fields=[Checksum_0B4:0, IBS_ABPActive:0, IBS_ABSActive:0, IBS_EBDActive:0, IBS_EBDFault:0, IBS_SystemStatus:0, IBS_TCSFault:0, IBS_VCU_DecelerationRequest_Available:0, IBS_VehicleSpeed:0, MessageCounter_0B4:0, IBS_DTCFault:0, IBS_VehicleSpeedValid:0, IBS_ABPAvailable:0, IBS_ABSFault:0, IBS_EPBTextdisplay:0, IBS_VDCFault:0]}, required-interface=SG_IBS_Status_03_SigGroup_1
      SG_IBS_Status_04_SigGroup_1: nonqueued-receiver-com-spec{data-element=SG_IBS_Status_04_SigGroup, uses-end-to-end-protection=true, enable-update=true, init-value=fields=[Checksum_0BA:0, IBS_CDPActive:0, IBS_DTCActive:0, MessageCounter_0BA:0, IBS_CDPAvailable:0]}, required-interface=SG_IBS_Status_04_SigGroup_1
      SG_IBS_Status_05_SigGroup_1: nonqueued-receiver-com-spec{data-element=SG_IBS_Status_05_SigGroup, uses-end-to-end-protection=true, enable-update=true, init-value=fields=[Checksum_0BB:0, IBS_SUBEPBworkingSts:0, MessageCounter_0BB:0, IBS_SUBEPBControllerSts:0, IBS_SUBEPBFailureStatus:0]}, required-interface=SG_IBS_Status_05_SigGroup_1
      SG_IBS_Status_06_SigGroup_1: nonqueued-receiver-com-spec{data-element=SG_IBS_Status_06_SigGroup, uses-end-to-end-protection=true, enable-update=true, init-value=fields=[Checksum_0BC:0, IBS_AVHSts:0, IBS_BrakeFluidWarning:0, IBS_ESCOffSts:1, IBS_HDCSts:0, IBS_RollerbenchMode:0, IBS_RWUActive:0, MessageCounter_0BC:0, IBS_EPBFailureStatus:0, IBS_ESClampdisplay:0, IBS_FactoryMode:0, IBS_HBAActive:0, IBS_MaintenaceMode:0, IBS_RWUAvailable:0, IBS_TireMonSysSts:1, IBS_TireWarnFrntLe:0, IBS_TireWarnFrntRi:0, IBS_TireWarnReLe:0, IBS_TireWarnReRi:0, IBS_TPMS_ResetSts:0]}, required-interface=SG_IBS_Status_06_SigGroup_1
      SG_IBS_WheelSpeed_01_SigGroup_1: nonqueued-receiver-com-spec{data-element=SG_IBS_WheelSpeed_01_SigGroup, uses-end-to-end-protection=true, enable-update=true, init-value=fields=[Checksum_0B0:0, IBS_FLMovingDirection:0, IBS_FRMovingDirection:0, MessageCounter_0B0:0, IBS_FLWheelPulseCounter:0, IBS_FLWheelSpeed:0, IBS_FLWheelSpeed_Fault:0, IBS_FRWheelPulseCounter:0, IBS_FRWheelSpeed:0, IBS_FRWheelSpeed_Fault:0]}, required-interface=SG_IBS_WheelSpeed_01_SigGroup_1
      SG_IBS_WheelSpeed_02_SigGroup_1: nonqueued-receiver-com-spec{data-element=SG_IBS_WheelSpeed_02_SigGroup, uses-end-to-end-protection=true, enable-update=true, init-value=fields=[Checksum_0B1:0, IBS_RLMovingDirection:0, IBS_RLWheelSpeed:0, IBS_RLWheelSpeed_Fault:0, IBS_RRMovingDirection:0, IBS_RRWheelSpeed:0, IBS_RRWheelSpeed_Fault:0, MessageCounter_0B1:0, IBS_RLWheelPulseCounter:0, IBS_RRWheelPulseCounter:0]}, required-interface=SG_IBS_WheelSpeed_02_SigGroup_1
      SG_SGW_01_SigGroup_1: nonqueued-receiver-com-spec{data-element=SG_SGW_01_SigGroup, enable-update=true, init-value=fields=[SGW_AppointChargeCmd:0, SGW_ChargeFormSet:0, SGW_LockACPlug:0, SGW_TimingChargeSwitchStatus:0, SGW_DschrgOnOffSet:0]}, required-interface=SG_SGW_01_SigGroup_1
      SG_BMS_status_04_SigGroup: nonqueued-receiver-com-spec{data-element=SG_BMS_status_04_SigGroup, enable-update=true, init-value=fields=[BMS_DisChgCurr:-1000, BMS_FeedbackCurr:-1000]}, required-interface=SG_BMS_status_04_SigGroup_2
      SG_IBS_Status_01_SigGroup: nonqueued-receiver-com-spec{data-element=SG_IBS_Status_01_SigGroup, uses-end-to-end-protection=true, enable-update=true, init-value=fields=[Checksum_0B2:0, IBS_PlungerPressure:-5, MessageCounter_0B2:0, IBS_BrakePedalStatus:0, IBS_BrakePedalStatusValid:1, IBS_BrakePushrodStroke:-5, IBS_MasterCylinderPressure:0]}, required-interface=SG_IBS_Status_01_SigGroup_2
      SG_IBS_ACC_SigGroup_1: nonqueued-receiver-com-spec{data-element=SG_IBS_ACC_SigGroup, uses-end-to-end-protection=true, enable-update=true, init-value=fields=[Checksum_0B8:0, IBS_CddActive:0, IBS_VehicleStandstill:0, IBS_VehicleStandstill_Valid:0, IBS_VlcActive:0, IBS_WLTorqueVLCReq:-20000, IBS_WLTorqueVLCReqValid:0, MessageCounter_0B8:0, IBS_CddAvailable:0, IBS_CddError:0, IBS_VlcAvalible:0, IBS_VlcError:0]}, required-interface=SG_IBS_ACC_SigGroup_3
    30 x provide port:
      VCU_BS_IndicatorLightSts_LIN00: nonqueued-sender-com-spec{data-element=VCU_BS_IndicatorLightSts_LIN, init-value=0}, provided-interface=VCU_BS_IndicatorLightSts_LIN00
      VCU_IBS_EBDFault_LIN00: nonqueued-sender-com-spec{data-element=VCU_IBS_EBDFault_LIN, init-value=0}, provided-interface=VCU_IBS_EBDFault_LIN00
      VCU_IBS_RollerbenchMode_LIN00: nonqueued-sender-com-spec{data-element=VCU_IBS_RollerbenchMode_LIN, init-value=0}, provided-interface=VCU_IBS_RollerbenchMode_LIN00
      VCU_BCM_FLSeatBeltRemindReq_LIN00: nonqueued-sender-com-spec{data-element=VCU_BCM_FLSeatBeltRemindReq_LIN, init-value=0}, provided-interface=VCU_BCM_FLSeatBeltRemindReq_LIN00
      VCU_DCM_RR_DoorRRSts_LIN00: nonqueued-sender-com-spec{data-element=VCU_DCM_RR_DoorRRSts_LIN, init-value=0}, provided-interface=VCU_DCM_RR_DoorRRSts_LIN00
      VCU_DCM_FL_DoorFLSts_LIN00: nonqueued-sender-com-spec{data-element=VCU_DCM_FL_DoorFLSts_LIN, init-value=0}, provided-interface=VCU_DCM_FL_DoorFLSts_LIN00
      VCU_BCM_RLSeatBeltRemindReq_LIN00: nonqueued-sender-com-spec{data-element=VCU_BCM_RLSeatBeltRemindReq_LIN, init-value=0}, provided-interface=VCU_BCM_RLSeatBeltRemindReq_LIN00
      VCU_Batt_U0_Max_LIN00: nonqueued-sender-com-spec{data-element=VCU_Batt_U0_Max_LIN, init-value=2}, provided-interface=VCU_Batt_U0_Max_LIN00
      VCU_BattNomC20_LIN00: nonqueued-sender-com-spec{data-element=VCU_BattNomC20_LIN, init-value=70}, provided-interface=VCU_BattNomC20_LIN00
      VCU_ACU_DriverWarningLampSts_LIN00: nonqueued-sender-com-spec{data-element=VCU_ACU_DriverWarningLampSts_LIN, init-value=0}, provided-interface=VCU_ACU_DriverWarningLampSts_LIN00
      VCU_ACU_PassengerWarningLampSts_LIN00: nonqueued-sender-com-spec{data-element=VCU_ACU_PassengerWarningLampSts_LIN, init-value=0}, provided-interface=VCU_ACU_PassengerWarningLampSts_LIN00
      VCU_ACU_PassengerAirbagSts_LIN00: nonqueued-sender-com-spec{data-element=VCU_ACU_PassengerAirbagSts_LIN, init-value=0}, provided-interface=VCU_ACU_PassengerAirbagSts_LIN00
      VCU_DCDCFail_LIN_LIN00: nonqueued-sender-com-spec{data-element=VCU_DCDCFail_LIN_LIN, init-value=0}, provided-interface=VCU_DCDCFail_LIN_LIN00
      VCU_Batt_U0_Min_LIN00: nonqueued-sender-com-spec{data-element=VCU_Batt_U0_Min_LIN, init-value=2}, provided-interface=VCU_Batt_U0_Min_LIN00
      VCU_HVBatCriFail_LIN_LIN00: nonqueued-sender-com-spec{data-element=VCU_HVBatCriFail_LIN_LIN, init-value=0}, provided-interface=VCU_HVBatCriFail_LIN_LIN00
      VCU_IBSClrDiagInf_LIN00: nonqueued-sender-com-spec{data-element=VCU_IBSClrDiagInf_LIN, init-value=0}, provided-interface=VCU_IBSClrDiagInf_LIN00
      VCU_DCM_FR_DoorFRSts_LIN00: nonqueued-sender-com-spec{data-element=VCU_DCM_FR_DoorFRSts_LIN, init-value=0}, provided-interface=VCU_DCM_FR_DoorFRSts_LIN00
      VCU_BCM_FRSeatBeltRemindReq_LIN00: nonqueued-sender-com-spec{data-element=VCU_BCM_FRSeatBeltRemindReq_LIN, init-value=0}, provided-interface=VCU_BCM_FRSeatBeltRemindReq_LIN00
      VCU_BattType_LIN00: nonqueued-sender-com-spec{data-element=VCU_BattType_LIN, init-value=0}, provided-interface=VCU_BattType_LIN00
      VCU_HVBatOvrTemp_LIN_LIN00: nonqueued-sender-com-spec{data-element=VCU_HVBatOvrTemp_LIN_LIN, init-value=0}, provided-interface=VCU_HVBatOvrTemp_LIN_LIN00
      VCU_DCM_RL_DoorRLSts_LIN00: nonqueued-sender-com-spec{data-element=VCU_DCM_RL_DoorRLSts_LIN, init-value=0}, provided-interface=VCU_DCM_RL_DoorRLSts_LIN00
      VCU_IBS_BrakeFluidWarning_LIN00: nonqueued-sender-com-spec{data-element=VCU_IBS_BrakeFluidWarning_LIN, init-value=0}, provided-interface=VCU_IBS_BrakeFluidWarning_LIN00
      VCU_CGW_VehicleState_LIN00: nonqueued-sender-com-spec{data-element=VCU_CGW_VehicleState_LIN, init-value=0}, provided-interface=VCU_CGW_VehicleState_LIN00
      VCU_IBS_SystemStatus_LIN00: nonqueued-sender-com-spec{data-element=VCU_IBS_SystemStatus_LIN, init-value=0}, provided-interface=VCU_IBS_SystemStatus_LIN00
      VCU_HstTempDataRqTrg_LIN00: nonqueued-sender-com-spec{data-element=VCU_HstTempDataRqTrg_LIN, init-value=0}, provided-interface=VCU_HstTempDataRqTrg_LIN00
      VCU_BCM_RRSeatBeltRemindReq_LIN00: nonqueued-sender-com-spec{data-element=VCU_BCM_RRSeatBeltRemindReq_LIN, init-value=0}, provided-interface=VCU_BCM_RRSeatBeltRemindReq_LIN00
      VCU_IVI_VrState_LIN00: nonqueued-sender-com-spec{data-element=VCU_IVI_VrState_LIN, init-value=0}, provided-interface=VCU_IVI_VrState_LIN00
      VCU_ACU_WarningLampSts_LIN00: nonqueued-sender-com-spec{data-element=VCU_ACU_WarningLampSts_LIN, init-value=0}, provided-interface=VCU_ACU_WarningLampSts_LIN00
      VCU_DriveMotOvrTemp_LIN_LIN00: nonqueued-sender-com-spec{data-element=VCU_DriveMotOvrTemp_LIN_LIN, init-value=0}, provided-interface=VCU_DriveMotOvrTemp_LIN_LIN00
      VCU_IVI_BulbCheckStsLIN01: nonqueued-sender-com-spec{data-element=VCU_IVI_BulbCheckStsLIN01, init-value=0}, provided-interface=VCU_IVI_BulbCheckStsLIN01
    8 x require port:
      Resp_Error_LIN01: nonqueued-receiver-com-spec{data-element=Resp_Error_LIN01, init-value=0}, required-interface=Resp_Error_LIN01
      SOH_LIN01: nonqueued-receiver-com-spec{data-element=SOH_LIN01, init-value=255}, required-interface=SOH_LIN01
      I_BATT_LIN01: nonqueued-receiver-com-spec{data-element=I_BATT_LIN01, init-value=65535}, required-interface=I_BATT_LIN01
      U_BATT_LIN01: nonqueued-receiver-com-spec{data-element=U_BATT_LIN01, init-value=16383}, required-interface=U_BATT_LIN01
      IBATT_QUIESCENT_LIN01: nonqueued-receiver-com-spec{data-element=IBATT_QUIESCENT_LIN01, init-value=255}, required-interface=IBATT_QUIESCENT_LIN01
      I_RANGE_LIN01: nonqueued-receiver-com-spec{data-element=I_RANGE_LIN01, init-value=3}, required-interface=I_RANGE_LIN01
      SOC_LIN01: nonqueued-receiver-com-spec{data-element=SOC_LIN01, init-value=1}, required-interface=SOC_LIN01
      T_BATT_LIN01: nonqueued-receiver-com-spec{data-element=T_BATT_LIN01, init-value=255}, required-interface=T_BATT_LIN01
    6 x provide port:
      ChargeCurrWU_Ena_LIN01: nonqueued-sender-com-spec{data-element=ChargeCurrWU_Ena_LIN01, init-value=1}, provided-interface=ChargeCurrWU_Ena_LIN01
      SOCWU_Ena_LIN01: nonqueued-sender-com-spec{data-element=SOCWU_Ena_LIN01, init-value=1}, provided-interface=SOCWU_Ena_LIN01
      DisChargeCurrWU_Treshold_LIN01: nonqueued-sender-com-spec{data-element=DisChargeCurrWU_Treshold_LIN01, init-value=145}, provided-interface=DisChargeCurrWU_Treshold_LIN01
      SOCWU_Treshold_LIN01: nonqueued-sender-com-spec{data-element=SOCWU_Treshold_LIN01, init-value=70}, provided-interface=SOCWU_Treshold_LIN01
      DisChargeCurrWU_Ena_LIN01: nonqueued-sender-com-spec{data-element=DisChargeCurrWU_Ena_LIN01, init-value=1}, provided-interface=DisChargeCurrWU_Ena_LIN01
      ChargeCurrWU_Treshold_LIN01: nonqueued-sender-com-spec{data-element=ChargeCurrWU_Treshold_LIN01, init-value=30}, provided-interface=ChargeCurrWU_Treshold_LIN01
    require port SOF_V2_LIN01: nonqueued-receiver-com-spec{data-element=SOF_V2_LIN01, init-value=255}, required-interface=SOF_V2_LIN01
    require port SOF_V1_LIN01: nonqueued-receiver-com-spec{data-element=SOF_V1_LIN01, init-value=255}, required-interface=SOF_V1_LIN01
    require port SG_IVI_03_SigGroup: nonqueued-receiver-com-spec{data-element=SG_IVI_03_SigGroup, init-value=fields=[Checksum_0F9:0, IVI_BulbCheckSts:0, IVI_SFIabnormalSts:0, IVI_SFIDippedBeamSet:0, MessageCounter_0F9:0]}, required-interface=SG_IVI_03_SigGroup
    provide port SG_VCU_HMIsignals_03_SigGroup: nonqueued-sender-com-spec{data-element=SG_VCU_HMIsignals_03_SigGroup, init-value=fields=[VCU_Display_voltage:0, VCU_BS_HCurrent:2047.9375, VCU_BS_QuiescentCurrent:0.99609375]}, provided-interface=SG_VCU_HMIsignals_03_SigGroup_1
    provide port BST_AbortChargparameter: nonqueued-sender-com-spec{data-element=BST_AbortChargparameter, init-value=0}, provided-interface=BST_AbortChargparameter
    require port SG_EPS_CONV_SigGroup: nonqueued-receiver-com-spec{data-element=SG_EPS_CONV_SigGroup, uses-end-to-end-protection=true, enable-update=true, init-value=fields=[Checksum_0F0:0, EPS_ModeChangeEnable:0, EPS_ModeFb:0, EPS_SteeringGearAngle:0, EPS_SteeringGearAngleSpd:0, EPS_SteeringGearAngleSpdValid:0, EPS_SteeringGearAngleValid:0, EPS_TorsionBarTorque:0, EPS_TorsionBarTorqueValid:0, EPS_WarningLamp:0, MessageCounter_0F0:0]}, required-interface=SG_EPS_CONV_SigGroup
    43 x component:
      YDF_LCS: type=YDF_LCS
      YDF_BIST: type=YDF_BIST
      YDF_CanHandler: type=YDF_CanHandler
      YDF_ErrorHandler: type=YDF_ErrorHandler
      YDF_EthHandler: type=YDF_EthHandler
      YDF_NMHandler: type=YDF_NMHandler
      IoHwAb: type=IoHwAb
      HookCallout: type=HookCallout
      YDF_XcpHandler: type=YDF_XcpHandler
      YDF_CddHandler: type=YDF_ComplexDriver
      YDF_BootManagement: type=YDF_BootloaderHandler
      YDF_FunInterface_Handler: type=YDF_GetIf_Driver
      YDF_SetPoweroff_Handler: type=YDF_SetPowerOffDriver
      YDF_WakeUp_Swc: type=YDF_WakeUp_Swc
      YDF_DiagHandler: type=YDF_DiagHandler
      YDF_PerManager: type=YDF_PerManager
      CtAp_CANHandler: type=CtAp_CANHandler
      CtAp_RngEstimn: type=CtAp_RngEstimn
      CtAp_LvMgmt: type=CtAp_LvMgmt
      CtAp_HvMgmt: type=CtAp_HvMgmt
      CtAp_EgyMgmt: type=CtAp_EgyMgmt
      CtAp_ComMErr: type=CtAp_ComMErr
      CtAp_ModMgmt: type=CtAp_ModMgmt
      CtAp_VehMot: type=CtAp_VehMot
      CtAp_OBCMgmt: type=CtAp_OBCMgmt
      CtAp_ChrMgmt: type=CtAp_ChrMgmt
      CtAp_FctSftyMon: type=CtAp_FctSftyMon
      CtAp_ChassisMgmt: type=CtAp_ChassisMgmt
      CtAp_TorqPahMgmt: type=CtAp_TorqPahMgmt
      CtAp_ErrMgmt: type=CtAp_ErrMgmt
      CtAp_DCChrMgmt: type=CtAp_DCChrMgmt
      CtAp_GearMgmt: type=CtAp_GearMgmt
      CtAp_HWHandler: type=CtAp_HWHandler
      YDF_NVMgmt: type=CtAp_NvMBlock
      YDF_RollingCounter: type=KAMA_RollingCounterManagement
      YDF_RVCUHandler: type=YDF_RVCU_Swc
      CtAp_LINHandler: type=CtAp_LINHandler
      CtAp_DCComM: type=CtAp_DCComM
      YDF_OutputInterface: type=YDF_OutPutDriver
      CtAp_DiagnosisApp: type=CtAp_DiagnosisApp
      YDF_CtAp_CANHandler_TaskCtrl: type=YDF_CtAp_CANHandler_TaskCtrl
      YDF_MileageCalculation: type=YDF_MileageCalculation
      YDF_SecOC: type=YDF_SecOC
    connect YDF_LCS.PiLCSMCommand_R -> YDF_LCS.PiLCSMCommand_S
    connect YDF_PerManager.PerNvR -> YDF_DiagHandler.PerNvR
    connect YDF_SetPoweroff_Handler.Set_Tsk_CpuSleepOrOff -> YDF_WakeUp_Swc.Set_Tsk_CpuSleepOrOff
    connect YDF_DiagHandler.DiagHandle -> YDF_ErrorHandler.DiagHandle
    connect YDF_PerManager.Per_NvBlock_Notification_DSC -> YDF_DiagHandler.Per_NvBlock_Notification_DSC
    connect YDF_LCS.ComCtrl -> YDF_NMHandler.ComCtrl
    connect IoHwAb.IoHwAb_ServiceType -> YDF_BIST.IoHwAb_ServiceType
    connect YDF_NMHandler.GetComState -> YDF_LCS.GetComState
    connect YDF_FunInterface_Handler.Get_If -> YDF_WakeUp_Swc.Get_If_GetWakeUPStatus
    connect YDF_ErrorHandler.QCF_SafetyReaction -> YDF_LCS.QCF_SafetyReaction
    connect YDF_ErrorHandler.QCF_RecoveryReaction -> YDF_LCS.QCF_RecoveryReaction
    connect YDF_ErrorHandler.ErrorHandler -> YDF_PerManager.ErrorHandler
    connect YDF_ErrorHandler.ErrorHandler -> HookCallout.ErrorHandler
    connect YDF_ErrorHandler.ErrorHandler -> YDF_LCS.ErrorHandler
    connect CtAp_CANHandler.RTE_P_ComM_BMSBattDispSOC_pct -> CtAp_RngEstimn.RTE_R_ComM_BMSBattDispSOC_pct
    connect CtAp_CANHandler.RTE_P_ComM_BMSBattIDc_A -> CtAp_RngEstimn.RTE_R_ComM_BMSBattIDc_A
    connect CtAp_RngEstimn.RTE_P_RngEstimn_DynDrvMilg_km -> CtAp_CANHandler.RTE_R_RngEstimn_DynDrvMilg_km
    connect CtAp_RngEstimn.RTE_P_RngEstimn_StdDrvMilg_km -> CtAp_CANHandler.RTE_R_RngEstimn_StdDrvMilg_km
    delegate CtAp_CANHandler.CCS_OutputVoltage <-> outer port CCS_OutputVoltage
    delegate CtAp_CANHandler.CEM_BatteryChargeRequireTimeout <-> outer port CEM_BatteryChargeRequireTimeout
    delegate CtAp_CANHandler.CHM_ProtocolVersion <-> outer port CHM_ProtocolVersion
    delegate CtAp_CANHandler.BHM_AllowChargeVoltageMax <-> outer port BHM_AllowChargeVoltageMax
    connect CtAp_CANHandler.RTE_P_ComM_OBCCCSts_Enum -> CtAp_LvMgmt.RTE_R_ComM_OBCCCSts_Enum
    connect CtAp_ComMErr.RTE_P_ComM_CANBusOffInfo_Bus -> CtAp_CANHandler.RTE_R_ComM_CANBusOffInfo_Bus
    connect CtAp_CANHandler.RTE_P_ComM_IBSACCMsgErrInfo_Bus -> CtAp_ComMErr.RTE_R_ComM_IBSACCMsgErrInfo_Bus
    connect CtAp_CANHandler.RTE_P_ComM_PRNDMsgErrInfo_Bus -> CtAp_ComMErr.RTE_R_ComM_PRNDMsgErrInfo_Bus
    connect CtAp_CANHandler.RTE_P_ComM_BMSErrInfoTimeoutInfo_Bus -> CtAp_ComMErr.RTE_R_ComM_BMSErrInfoTimeoutInfo_Bus
    connect CtAp_CANHandler.RTE_P_ComM_IBSSts{01..06}MsgErrInfo_Bus -> CtAp_ComMErr.RTE_R_ComM_IBSSts{01..06}MsgErrInfo_Bus
    connect CtAp_CANHandler.RTE_P_ComM_BMSSts02MsgErrInfo_Bus -> CtAp_ComMErr.RTE_R_ComM_BMSSts02MsgErrInfo_Bus
    connect CtAp_CANHandler.RTE_P_ComM_MCUFailrCodMsgErrInfo_Bus -> CtAp_ComMErr.RTE_R_ComM_MCUFailrCodMsgErrInfo_Bus
    connect CtAp_CANHandler.RTE_P_ComM_ADCUBodyReqMsgErrInfo_Bus -> CtAp_ComMErr.RTE_R_ComM_ADCUBodyReqMsgErrInfo_Bus
    connect CtAp_CANHandler.RTE_P_ComM_DCMFL02MsgErrInfo_Bus -> CtAp_ComMErr.RTE_R_ComM_DCMFL02MsgErrInfo_Bus
    connect CtAp_CANHandler.RTE_P_ComM_SGWPT01MsgErrInfo_Bus -> CtAp_ComMErr.RTE_R_ComM_SGWPT01MsgErrInfo_Bus
    connect CtAp_CANHandler.RTE_P_ComM_ACU01MsgErrInfo_Bus -> CtAp_ComMErr.RTE_R_ComM_ACU01MsgErrInfo_Bus
    connect CtAp_CANHandler.RTE_P_ComM_ACU02MsgErrInfo_Bus -> CtAp_ComMErr.RTE_R_ComM_ACU02MsgErrInfo_Bus
    connect CtAp_CANHandler.RTE_P_ComM_BCM06MsgErrInfo_Bus -> CtAp_ComMErr.RTE_R_ComM_BCM06MsgErrInfo_Bus
    connect CtAp_CANHandler.RTE_P_ComM_CGW01MsgErrInfo_Bus -> CtAp_ComMErr.RTE_R_ComM_CGW01MsgErrInfo_Bus
    connect CtAp_CANHandler.RTE_P_ComM_EVCOMSts01MsgErrInfo_Bus -> CtAp_ComMErr.RTE_R_ComM_EVCOMSts01MsgErrInfo_Bus
    connect CtAp_CANHandler.RTE_P_ComM_IBSTqMsgErrInfo_Bus -> CtAp_ComMErr.RTE_R_ComM_IBSTqMsgErrInfo_Bus
    connect CtAp_CANHandler.RTE_P_ComM_IBSVCUMotCtrlMsgErrInfo_Bus -> CtAp_ComMErr.RTE_R_ComM_IBSVCUMotCtrlMsgErrInfo_Bus
    connect CtAp_CANHandler.RTE_P_ComM_MCU01MsgErrInfo_Bus -> CtAp_ComMErr.RTE_R_ComM_MCU01MsgErrInfo_Bus
    connect CtAp_CANHandler.RTE_P_ComM_TCU01MsgErrInfo_Bus -> CtAp_ComMErr.RTE_R_ComM_TCU01MsgErrInfo_Bus
    connect CtAp_CANHandler.RTE_P_ComM_PODSts01TimeoutInfo_Bus -> CtAp_ComMErr.RTE_R_ComM_PODSts01TimeoutInfo_Bus
    connect CtAp_CANHandler.RTE_P_ComM_SGWTimMsgErrInfo_Bus -> CtAp_ComMErr.RTE_R_ComM_SGWTimMsgErrInfo_Bus
    connect CtAp_CANHandler.RTE_P_ComM_BMSSts01ErrInfo_Bus -> CtAp_ComMErr.RTE_R_ComM_BMSSts01ErrInfo_Bus
    connect CtAp_CANHandler.RTE_P_ComM_IBSWhlSpd01MsgErrInfo_Bus -> CtAp_ComMErr.RTE_R_ComM_IBSWhlSpd01MsgErrInfo_Bus
    connect CtAp_CANHandler.RTE_P_ComM_IBSWhlSpd02MsgErrInfo_Bus -> CtAp_ComMErr.RTE_R_ComM_IBSWhlSpd02MsgErrInfo_Bus
    connect CtAp_CANHandler.RTE_P_ComM_PODOBCChrgStatMsgErrInfo_Bus -> CtAp_ComMErr.RTE_R_ComM_PODOBCChrgStatMsgErrInfo_Bus
    connect CtAp_CANHandler.RTE_P_ComM_ADCUACC02MsgErrInfo_Bus -> CtAp_ComMErr.RTE_R_ComM_ADCUACC02MsgErrInfo_Bus
    connect CtAp_CANHandler.RTE_P_ComM_PODDCDC01MsgErrInfo_Bus -> CtAp_ComMErr.RTE_R_ComM_PODDCDC01MsgErrInfo_Bus
    connect CtAp_CANHandler.RTE_P_ComM_APTCTCUMsgErrInfo_Bus -> CtAp_ComMErr.RTE_R_ComM_APTCTCUMsgErrInfo_Bus
    connect CtAp_ModMgmt.RTE_P_ModMgmt_ActDrvMod_Enum -> CtAp_CANHandler.RTE_R_ModMgmt_ActDrvMod_Enum
    connect CtAp_ModMgmt.RTE_P_ModMgmt_HvSts_Enum -> CtAp_CANHandler.RTE_R_ModMgmt_HvSts_Enum
    connect CtAp_ModMgmt.RTE_P_ModMgmt_HvSts_Enum -> CtAp_RngEstimn.RTE_R_ModMgmt_HvSts_Enum
    connect CtAp_CANHandler.RTE_P_ComM_DCDCHvInpIDc_A -> CtAp_EgyMgmt.RTE_R_ComM_DCDCHvInpIDc_A
    connect CtAp_CANHandler.RTE_P_ComM_MCUIDc_A -> CtAp_EgyMgmt.RTE_R_ComM_MCUIDc_A
    connect CtAp_CANHandler.RTE_P_ComM_OBCOutpIDc_A -> CtAp_EgyMgmt.RTE_R_ComM_OBCOutpIDc_A
    connect CtAp_CANHandler.RTE_P_ComM_HVCHUDc_V -> CtAp_EgyMgmt.RTE_R_ComM_HVCHUDc_V
    connect CtAp_CANHandler.RTE_P_ComM_DCDCHvInpUDc_V -> CtAp_EgyMgmt.RTE_R_ComM_DCDCHvInpUDc_V
    connect CtAp_CANHandler.RTE_P_ComM_HVCHIDc_A -> CtAp_EgyMgmt.RTE_R_ComM_HVCHIDc_A
    connect CtAp_CANHandler.RTE_P_ComM_BMSPTCUDc_V -> CtAp_EgyMgmt.RTE_R_ComM_BMSPTCUDc_V
    connect CtAp_CANHandler.RTE_P_ComM_BMSBattHeatIDc_A -> CtAp_EgyMgmt.RTE_R_ComM_BMSBattHeatIDc_A
    connect CtAp_CANHandler.RTE_P_ComM_OBCOutpUDc_V -> CtAp_EgyMgmt.RTE_R_ComM_OBCOutpUDc_V
    connect CtAp_CANHandler.RTE_P_ComM_MCUUDc_V -> CtAp_EgyMgmt.RTE_R_ComM_MCUUDc_V
    connect CtAp_CANHandler.RTE_P_ComM_APTCPwrCns_Kw -> CtAp_EgyMgmt.RTE_R_ComM_APTCPwrCns_Kw
    connect CtAp_CANHandler.RTE_P_ComM_EVCOMActPwrCns_Kw -> CtAp_EgyMgmt.RTE_R_ComM_EVCOMActPwrCns_Kw
    connect CtAp_CANHandler.RTE_P_ComM_BMSBattDchaIDc_A -> CtAp_EgyMgmt.RTE_R_ComM_BMSBattDchaIDc_A
    connect CtAp_CANHandler.RTE_P_ComM_BMSBattFbIDc_A -> CtAp_EgyMgmt.RTE_R_ComM_BMSBattFbIDc_A
    connect CtAp_CANHandler.RTE_P_ComM_BMSBattDispSOC_pct -> CtAp_EgyMgmt.RTE_R_ComM_BMSBattDispSOC_pct
    connect CtAp_CANHandler.RTE_P_ComM_BMSBattIDc_A -> CtAp_EgyMgmt.RTE_R_ComM_BMSBattIDc_A
    connect CtAp_ModMgmt.RTE_P_ModMgmt_ActDrvMod_Enum -> CtAp_EgyMgmt.RTE_R_ModMgmt_ActDrvMod_Enum
    connect CtAp_CANHandler.RTE_P_ComM_BMSBattAllowChrgIDc_A -> CtAp_EgyMgmt.RTE_R_ComM_BMSBattAllowChrgIDc_A
    connect CtAp_CANHandler.RTE_P_ComM_BMSBattPckUDc_V -> CtAp_EgyMgmt.RTE_R_ComM_BMSBattPckUDc_V
    connect CtAp_CANHandler.RTE_P_ComM_TMSTotPwrReq_W -> CtAp_EgyMgmt.RTE_R_ComM_TMSTotPwrReq_W
    connect CtAp_EgyMgmt.RTE_P_EgyMgmt_AvgMCUPwrCnsCalcn_Kw -> CtAp_CANHandler.RTE_R_EgyMgmt_AvgMCUPwrCnsCalcn_Kw
    connect CtAp_EgyMgmt.RTE_P_EgyMgmt_EgyMgmtWarn_Enum -> CtAp_CANHandler.RTE_R_EgyMgmt_EgyMgmtWarn_Enum
    connect CtAp_EgyMgmt.RTE_P_EgyMgmt_PermtPckPTC_Flg -> CtAp_CANHandler.RTE_R_EgyMgmt_PermtPckPTC_Flg
    connect CtAp_EgyMgmt.RTE_P_EgyMgmt_BMSTarThermLvl_Enum -> CtAp_CANHandler.RTE_R_EgyMgmt_BMSTarThermLvl_Enum
    connect CtAp_EgyMgmt.RTE_P_EgyMgmt_DCDCPwrLmt_Kw -> CtAp_CANHandler.RTE_R_EgyMgmt_DCDCPwrLmt_Kw
    connect CtAp_EgyMgmt.RTE_P_EgyMgmt_TCUPwrAllwd_W -> CtAp_CANHandler.RTE_R_EgyMgmt_TCUPwrAllwd_W
    connect CtAp_CANHandler.RTE_P_ComM_IBSFLMovgDir_Enum -> CtAp_VehMot.RTE_R_ComM_IBSFLMovgDir_Enum
    connect CtAp_CANHandler.RTE_P_ComM_IBSFRMovgDir_Enum -> CtAp_VehMot.RTE_R_ComM_IBSFRMovgDir_Enum
    connect CtAp_CANHandler.RTE_P_ComM_IBSRLMovgDir_Enum -> CtAp_VehMot.RTE_R_ComM_IBSRLMovgDir_Enum
    connect CtAp_CANHandler.RTE_P_ComM_IBSRRMovgDir_Enum -> CtAp_VehMot.RTE_R_ComM_IBSRRMovgDir_Enum
    connect CtAp_CANHandler.RTE_P_ComM_MotActSpd_rpm -> CtAp_VehMot.RTE_R_ComM_MotActSpd_rpm
    connect CtAp_CANHandler.RTE_P_ComM_YRSAxSts -> CtAp_VehMot.RTE_R_ComM_YRSAxSts
    connect CtAp_CANHandler.RTE_P_ComM_IBSSts03MsgErrInfo_Bus -> CtAp_VehMot.RTE_R_ComM_IBSSts03MsgErrInfo_Bus
    connect CtAp_CANHandler.RTE_P_ComM_MCU01MsgErrInfo_Bus -> CtAp_VehMot.RTE_R_ComM_MCU01MsgErrInfo_Bus
    connect CtAp_CANHandler.RTE_P_ComM_MotActSpdVld_Flg -> CtAp_VehMot.RTE_R_ComM_MotActSpdVld_Flg
    connect CtAp_CANHandler.RTE_P_ComM_YRSAx_mps2q -> CtAp_VehMot.RTE_R_ComM_YRSAx_mps2q
    connect CtAp_CANHandler.RTE_P_ComM_IBSVehSpdVld_Flg -> CtAp_VehMot.RTE_R_ComM_IBSVehSpdVld_Flg
    connect CtAp_CANHandler.RTE_P_ComM_IBSVehSpd_kph -> CtAp_VehMot.RTE_R_ComM_IBSVehSpd_kph
    connect CtAp_CANHandler.RTE_P_ComM_MotActTq_Nm -> CtAp_VehMot.RTE_R_ComM_MotActTq_Nm
    connect CtAp_VehMot.RTE_P_VehMot_VehSpdVld_Flg -> CtAp_CANHandler.RTE_R_VehMot_VehSpdVld_Flg
    connect CtAp_VehMot.RTE_P_VehMot_VehSpdVld_Flg -> CtAp_RngEstimn.RTE_R_VehMot_VehSpdVld_Flg
    connect CtAp_VehMot.RTE_P_VehMot_RegenBrkLiVld_Flg -> CtAp_CANHandler.RTE_R_VehMot_RegenBrkLiVld_Flg
    connect CtAp_VehMot.RTE_P_VehMot_VehSpd_kph -> CtAp_RngEstimn.RTE_R_VehMot_VehSpd_kph
    connect CtAp_VehMot.RTE_P_VehMot_RegenBrkLi_Flg -> CtAp_CANHandler.RTE_R_VehMot_RegenBrkLi_Flg
    connect CtAp_VehMot.RTE_P_VehMot_VehSpdABS_kph -> CtAp_CANHandler.RTE_R_VehMot_VehSpdABS_kph
    connect CtAp_CANHandler.RTE_P_ComM_AcChrgPha_Enum -> CtAp_OBCMgmt.RTE_R_ComM_AcChrgPha_Enum
    connect CtAp_CANHandler.RTE_P_ComM_IVIReqElectcLock_Enum -> CtAp_OBCMgmt.RTE_R_ComM_IVIReqElectcLock_Enum
    connect CtAp_CANHandler.RTE_P_ComM_OBCCCSts_Enum -> CtAp_OBCMgmt.RTE_R_ComM_OBCCCSts_Enum
    connect CtAp_CANHandler.RTE_P_ComM_OBCCPSts_Enum -> CtAp_OBCMgmt.RTE_R_ComM_OBCCPSts_Enum
    connect CtAp_CANHandler.RTE_P_ComM_OBCChrgSts_Enum -> CtAp_OBCMgmt.RTE_R_ComM_OBCChrgSts_Enum
    connect CtAp_CANHandler.RTE_P_ComM_OBCInpUAc_V -> CtAp_OBCMgmt.RTE_R_ComM_OBCInpUAc_V
    connect CtAp_CANHandler.RTE_P_ComM_S2SwtSts_Enum -> CtAp_OBCMgmt.RTE_R_ComM_S2SwtSts_Enum
    connect CtAp_CANHandler.RTE_P_ComM_BMSBattAllowChrgIDc_A -> CtAp_OBCMgmt.RTE_R_ComM_BMSBattAllowChrgIDc_A
    connect CtAp_EgyMgmt.RTE_P_EgyMgmt_PackPTCPwrCnsCalcn_Kw -> CtAp_OBCMgmt.RTE_R_EgyMgmt_PackPTCPwrCnsCalcn_Kw
    connect CtAp_ComMErr.RTE_P_ComM_CANBusOffInfo_Bus -> CtAp_OBCMgmt.RTE_R_ComM_CANBusOffInfo_Bus
    connect CtAp_CANHandler.RTE_P_ComM_OBCCCIDcLmt_A -> CtAp_OBCMgmt.RTE_R_ComM_OBCCCIDcLmt_A
    connect CtAp_CANHandler.RTE_P_ComM_OBCCPIDcLmt_A -> CtAp_OBCMgmt.RTE_R_ComM_OBCCPIDcLmt_A
    connect CtAp_CANHandler.RTE_P_ComM_BCMAntithftSts_Enum -> CtAp_OBCMgmt.RTE_R_ComM_BCMAntithftSts_Enum
    connect CtAp_CANHandler.RTE_P_ComM_ElectcLockSts_Enum -> CtAp_OBCMgmt.RTE_R_ComM_ElectcLockSts_Enum
    connect CtAp_CANHandler.RTE_P_ComM_OBCCPPwmDuty_pct -> CtAp_OBCMgmt.RTE_R_ComM_OBCCPPwmDuty_pct
    connect CtAp_CANHandler.RTE_P_ComM_BMSBattLnkUDc_V -> CtAp_OBCMgmt.RTE_R_ComM_BMSBattLnkUDc_V
    connect CtAp_EgyMgmt.RTE_P_EgyMgmt_ACSysPwrCnsCalcn_Kw -> CtAp_OBCMgmt.RTE_R_EgyMgmt_ACSysPwrCnsCalcn_Kw
    connect CtAp_EgyMgmt.RTE_P_EgyMgmt_DCDCPwrCnsCalcn_Kw -> CtAp_OBCMgmt.RTE_R_EgyMgmt_DCDCPwrCnsCalcn_Kw
    connect CtAp_CANHandler.RTE_P_ComM_OBCMaxAllwdIDc_A -> CtAp_OBCMgmt.RTE_R_ComM_OBCMaxAllwdIDc_A
    connect CtAp_ModMgmt.RTE_P_ModMgmt_HvSts_Enum -> CtAp_OBCMgmt.RTE_R_ModMgmt_HvSts_Enum
    connect CtAp_OBCMgmt.RTE_P_OBCMgmt_S2SwtCtrlCmd_Enum -> CtAp_CANHandler.RTE_R_OBCMgmt_S2SwtCtrlCmd_Enum
    connect CtAp_OBCMgmt.RTE_P_OBCMgmt_OBCEnaCmd_Enum -> CtAp_CANHandler.RTE_R_OBCMgmt_OBCEnaCmd_Enum
    connect CtAp_OBCMgmt.RTE_P_OBCMgmt_ElectcLockCtrlCmd_Enum -> CtAp_CANHandler.RTE_R_OBCMgmt_ElectcLockCtrlCmd_Enum
    connect CtAp_OBCMgmt.RTE_P_OBCMgmt_MnyUnlckCmt_Enum -> CtAp_CANHandler.RTE_R_OBCMgmt_MnyUnlckCmt_Enum
    connect CtAp_OBCMgmt.RTE_P_OBCMgmt_ReqOBCIDc_A -> CtAp_CANHandler.RTE_R_OBCMgmt_ReqOBCIDc_A
    connect CtAp_CANHandler.RTE_P_ComM_IBSDecelReqAvl_Enum -> CtAp_ModMgmt.RTE_R_ComM_IBSDecelReqAvl_Enum
    connect CtAp_CANHandler.RTE_P_ComM_IVIDrvModSet_Enum -> CtAp_ModMgmt.RTE_R_ComM_IVIDrvModSet_Enum
    connect CtAp_CANHandler.RTE_P_ComM_IVIRgnLvlSet_Enum -> CtAp_ModMgmt.RTE_R_ComM_IVIRgnLvlSet_Enum
    connect CtAp_VehMot.RTE_P_VehMot_VehSpdVld_Flg -> CtAp_ModMgmt.RTE_R_VehMot_VehSpdVld_Flg
    connect CtAp_CANHandler.RTE_P_ComM_BMSBattDispSOC_pct -> CtAp_ModMgmt.RTE_R_ComM_BMSBattDispSOC_pct
    connect CtAp_ComMErr.RTE_P_ComM_NodComFailr -> CtAp_ModMgmt.RTE_R_ComM_NodComFailr
    connect CtAp_VehMot.RTE_P_VehMot_VehStdl_Flg -> CtAp_ModMgmt.RTE_R_VehMot_VehStdl_Flg
    connect CtAp_ModMgmt.RTE_P_ModMgmt_ActRgnSts_Enum -> CtAp_CANHandler.RTE_R_ModMgmt_ActRgnSts_Enum
    connect CtAp_ModMgmt.RTE_P_ModMgmt_DrvModSwtWarn_Enum -> CtAp_CANHandler.RTE_R_ModMgmt_DrvModSwtWarn_Enum
    connect CtAp_TorqPahMgmt.RTE_P_TorqPahMgmt_EmacQstyMaxTq_Nm -> CtAp_VehMot.RTE_R_TorqPahMgmt_EmacQstyMaxTq_Nm
    connect CtAp_TorqPahMgmt.RTE_P_TorqPahMgmt_EmacQstyMinTq_Nm -> CtAp_VehMot.RTE_R_TorqPahMgmt_EmacQstyMinTq_Nm
    connect CtAp_CANHandler.RTE_P_ComM_IBSEscOffSts_Enum -> CtAp_TorqPahMgmt.RTE_R_ComM_IBSEscOffSts_Enum
    connect CtAp_CANHandler.RTE_P_ComM_IVIFwdMaxVehSpdLmtSwt_Enum -> CtAp_TorqPahMgmt.RTE_R_ComM_IVIFwdMaxVehSpdLmtSwt_Enum
    connect CtAp_VehMot.RTE_P_VehMot_Acclr2Tq_Nm -> CtAp_TorqPahMgmt.RTE_R_VehMot_Acclr2Tq_Nm
    connect CtAp_ComMErr.RTE_P_ComM_NodComFailr -> CtAp_TorqPahMgmt.RTE_R_ComM_NodComFailr
    connect CtAp_EgyMgmt.RTE_P_EgyMgmt_MCUDrvPwrLmt_Kw -> CtAp_TorqPahMgmt.RTE_R_EgyMgmt_MCUDrvPwrLmt_Kw
    connect CtAp_EgyMgmt.RTE_P_EgyMgmt_MCUFbPwrLmt_Kw -> CtAp_TorqPahMgmt.RTE_R_EgyMgmt_MCUFbPwrLmt_Kw
    connect CtAp_CANHandler.RTE_P_ComM_IBSRLSpdVld_Flg -> CtAp_TorqPahMgmt.RTE_R_ComM_IBSRLSpdVld_Flg
    connect CtAp_CANHandler.RTE_P_ComM_IBSRRSpdVld_Flg -> CtAp_TorqPahMgmt.RTE_R_ComM_IBSRRSpdVld_Flg
    connect CtAp_CANHandler.RTE_P_ComM_MotActTqVld_Flg -> CtAp_TorqPahMgmt.RTE_R_ComM_MotActTqVld_Flg
    connect CtAp_CANHandler.RTE_P_ComM_MotActTq_Nm -> CtAp_TorqPahMgmt.RTE_R_ComM_MotActTq_Nm
    connect CtAp_CANHandler.RTE_P_ComM_MotMaxTq_Nm -> CtAp_TorqPahMgmt.RTE_R_ComM_MotMaxTq_Nm
    connect CtAp_CANHandler.RTE_P_ComM_MotMinTq_Nm -> CtAp_TorqPahMgmt.RTE_R_ComM_MotMinTq_Nm
    connect CtAp_VehMot.RTE_P_VehMot_VehDragTq_Nm -> CtAp_TorqPahMgmt.RTE_R_VehMot_VehDragTq_Nm
    connect CtAp_VehMot.RTE_P_VehMot_VehSpdVld_Flg -> CtAp_TorqPahMgmt.RTE_R_VehMot_VehSpdVld_Flg
    connect CtAp_CANHandler.RTE_P_ComM_IBSRLSpd_kph -> CtAp_TorqPahMgmt.RTE_R_ComM_IBSRLSpd_kph
    connect CtAp_CANHandler.RTE_P_ComM_IBSRRSpd_kph -> CtAp_TorqPahMgmt.RTE_R_ComM_IBSRRSpd_kph
    connect CtAp_CANHandler.RTE_P_ComM_IVIFwdVehSpdAllwd_Enum -> CtAp_TorqPahMgmt.RTE_R_ComM_IVIFwdVehSpdAllwd_Enum
    connect CtAp_ModMgmt.RTE_P_ModMgmt_ActDrvMod_Enum -> CtAp_TorqPahMgmt.RTE_R_ModMgmt_ActDrvMod_Enum
    connect CtAp_ModMgmt.RTE_P_ModMgmt_ActRgnSts_Enum -> CtAp_TorqPahMgmt.RTE_R_ModMgmt_ActRgnSts_Enum
    connect CtAp_ModMgmt.RTE_P_ModMgmt_HvSts_Enum -> CtAp_TorqPahMgmt.RTE_R_ModMgmt_HvSts_Enum
    connect CtAp_VehMot.RTE_P_VehMot_VehSpd_kph -> CtAp_TorqPahMgmt.RTE_R_VehMot_VehSpd_kph
    connect CtAp_VehMot.RTE_P_VehMot_VehSpdAcclr_mps2q -> CtAp_TorqPahMgmt.RTE_R_VehMot_VehSpdAcclr_mps2q
    connect CtAp_CANHandler.RTE_P_ComM_IBSRLMovgDir_Enum -> CtAp_TorqPahMgmt.RTE_R_ComM_IBSRLMovgDir_Enum
    connect CtAp_CANHandler.RTE_P_ComM_IBSRRMovgDir_Enum -> CtAp_TorqPahMgmt.RTE_R_ComM_IBSRRMovgDir_Enum
    connect CtAp_CANHandler.RTE_P_ComM_MCUUDc_V -> CtAp_TorqPahMgmt.RTE_R_ComM_MCUUDc_V
    connect CtAp_CANHandler.RTE_P_ComM_MotActSpd_rpm -> CtAp_TorqPahMgmt.RTE_R_ComM_MotActSpd_rpm
    connect CtAp_CANHandler.RTE_P_ComM_BMSWrkMod_Enum -> CtAp_LvMgmt.RTE_R_ComM_BMSWrkMod_Enum
    connect CtAp_CANHandler.RTE_P_ComM_DCDCWrkMod_Enum -> CtAp_LvMgmt.RTE_R_ComM_DCDCWrkMod_Enum
    connect CtAp_CANHandler.RTE_P_ComM_MCUWrkMod_Enum -> CtAp_LvMgmt.RTE_R_ComM_MCUWrkMod_Enum
    connect CtAp_CANHandler.RTE_P_ComM_OBCChrgSts_Enum -> CtAp_LvMgmt.RTE_R_ComM_OBCChrgSts_Enum
    connect CtAp_ModMgmt.RTE_P_ModMgmt_ReqSleep_Flg -> CtAp_LvMgmt.RTE_R_ModMgmt_ReqSleep_Flg
    connect CtAp_ModMgmt.RTE_P_ModMgmt_HvSts_Enum -> CtAp_LvMgmt.RTE_R_ModMgmt_HvSts_Enum
    connect CtAp_ModMgmt.RTE_P_ModMgmt_HvSts_Enum -> CtAp_FctSftyMon.RTE_R_ModMgmt_HvSts_Enum
    connect CtAp_VehMot.RTE_P_VehMot_VehSpd_kph -> CtAp_FctSftyMon.RTE_R_VehMot_VehSpd_kph
    connect CtAp_VehMot.RTE_P_VehMot_VehStdl_Flg -> CtAp_FctSftyMon.RTE_R_VehMot_VehStdl_Flg
    connect CtAp_LvMgmt.RTE_P_LvMgmt_BSBattUDcNorm_Flg -> CtAp_FctSftyMon.RTE_R_LvMgmt_BSBattUDcNorm_Flg
    connect CtAp_LvMgmt.RTE_P_LvMgmt_BSBattUDcNorm_Flg -> CtAp_OBCMgmt.RTE_R_LvMgmt_BSBattUDcNorm_Flg
    connect CtAp_CANHandler.RTE_P_ComM_MCUUDc_V -> CtAp_HvMgmt.RTE_R_ComM_MCUUDc_V
    connect CtAp_CANHandler.RTE_P_ComM_MCUWrkMod_Enum -> CtAp_HvMgmt.RTE_R_ComM_MCUWrkMod_Enum
    connect CtAp_CANHandler.RTE_P_ComM_MotActTq_Nm -> CtAp_HvMgmt.RTE_R_ComM_MotActTq_Nm
    connect CtAp_CANHandler.RTE_P_ComM_TCUHvPwrSts_Enum -> CtAp_HvMgmt.RTE_R_ComM_TCUHvPwrSts_Enum
    connect CtAp_CANHandler.RTE_P_ComM_BCMImmoSts_Flg -> CtAp_HvMgmt.RTE_R_ComM_BCMImmoSts_Flg
    connect CtAp_CANHandler.RTE_P_ComM_BMSBattLnkUDc_V -> CtAp_HvMgmt.RTE_R_ComM_BMSBattLnkUDc_V
    connect CtAp_CANHandler.RTE_P_ComM_DCDCHvInpUDc_V -> CtAp_HvMgmt.RTE_R_ComM_DCDCHvInpUDc_V
    connect CtAp_LvMgmt.RTE_P_LvMgmt_BSBattUDcNorm_Flg -> CtAp_HvMgmt.RTE_R_LvMgmt_BSBattUDcNorm_Flg
    connect CtAp_ComMErr.RTE_P_ComM_NodComFailr -> CtAp_HvMgmt.RTE_R_ComM_NodComFailr
    connect CtAp_ComMErr.RTE_P_ComM_CANBusOffInfo_Bus -> CtAp_HvMgmt.RTE_R_ComM_CANBusOffInfo_Bus
    connect CtAp_CANHandler.RTE_P_ComM_BMSNegRlySts_Enum -> CtAp_HvMgmt.RTE_R_ComM_BMSNegRlySts_Enum
    connect CtAp_CANHandler.RTE_P_ComM_BMSPosRlySts_Enum -> CtAp_HvMgmt.RTE_R_ComM_BMSPosRlySts_Enum
    connect CtAp_CANHandler.RTE_P_ComM_BMSWrkMod_Enum -> CtAp_HvMgmt.RTE_R_ComM_BMSWrkMod_Enum
    connect CtAp_CANHandler.RTE_P_ComM_DCDCWrkMod_Enum -> CtAp_HvMgmt.RTE_R_ComM_DCDCWrkMod_Enum
    connect CtAp_CANHandler.RTE_P_ComM_PEPSPwrMod_Enum -> CtAp_HvMgmt.RTE_R_ComM_PEPSPwrMod_Enum
    connect CtAp_CANHandler.RTE_P_ComM_BMSBattDispSOC_pct -> CtAp_HvMgmt.RTE_R_ComM_BMSBattDispSOC_pct
    connect CtAp_ModMgmt.RTE_P_ModMgmt_HvSts_Enum -> CtAp_HvMgmt.RTE_R_ModMgmt_HvSts_Enum
    connect CtAp_CANHandler.RTE_P_ComM_SGWRemHvCtrlReq_Enum -> CtAp_HvMgmt.RTE_R_ComM_SGWRemHvCtrlReq_Enum
    connect CtAp_VehMot.RTE_P_VehMot_VehStdl_Flg -> CtAp_HvMgmt.RTE_R_VehMot_VehStdl_Flg
    connect CtAp_CANHandler.RTE_P_ComM_BMSRTCReq_Flg -> CtAp_HvMgmt.RTE_R_ComM_BMSRTCReq_Flg
    connect CtAp_HvMgmt.RTE_P_HvMgmt_BMSNegRlyActSts_Enum -> CtAp_ModMgmt.RTE_R_HvMgmt_BMSNegRlyActSts_Enum
    connect CtAp_HvMgmt.RTE_P_HvMgmt_BMSWrkModActSts_Enum -> CtAp_ModMgmt.RTE_R_HvMgmt_BMSWrkModActSts_Enum
    connect CtAp_HvMgmt.RTE_P_HvMgmt_MCUWrkModActSts_Enum -> CtAp_ModMgmt.RTE_R_HvMgmt_MCUWrkModActSts_Enum
    connect CtAp_LvMgmt.RTE_P_LvMgmt_LvPwrDwn_Flg -> CtAp_ModMgmt.RTE_R_LvMgmt_LvPwrDwn_Flg
    connect CtAp_CANHandler.RTE_P_ComM_BMSCellHiTempErr_Enum -> CtAp_ErrMgmt.RTE_R_ComM_BMSCellHiTempErr_Enum
    connect CtAp_CANHandler.RTE_P_ComM_BMSHVILSts_Flg -> CtAp_ErrMgmt.RTE_R_ComM_BMSHVILSts_Flg
    connect CtAp_CANHandler.RTE_P_ComM_BMSErrLvl_Enum -> CtAp_ErrMgmt.RTE_R_ComM_BMSErrLvl_Enum
    connect CtAp_CANHandler.RTE_P_ComM_BMSInslaErrLvl_Enum -> CtAp_ErrMgmt.RTE_R_ComM_BMSInslaErrLvl_Enum
    connect CtAp_CANHandler.RTE_P_ComM_MCUTempOvrSts_Enum -> CtAp_ErrMgmt.RTE_R_ComM_MCUTempOvrSts_Enum
    connect CtAp_CANHandler.RTE_P_ComM_ACUCrashOutpSts_Enum -> CtAp_ErrMgmt.RTE_R_ComM_ACUCrashOutpSts_Enum
    connect CtAp_LvMgmt.RTE_P_LvMgmt_BSBattUDcNorm_Flg -> CtAp_ErrMgmt.RTE_R_LvMgmt_BSBattUDcNorm_Flg
    connect CtAp_ModMgmt.RTE_P_ModMgmt_HvSts_Enum -> CtAp_ErrMgmt.RTE_R_ModMgmt_HvSts_Enum
    connect CtAp_CANHandler.RTE_P_ComM_MCUErrLvl_Enum -> CtAp_ErrMgmt.RTE_R_ComM_MCUErrLvl_Enum
    connect CtAp_CANHandler.RTE_P_ComM_OBCErrLvl_Enum -> CtAp_ErrMgmt.RTE_R_ComM_OBCErrLvl_Enum
    connect CtAp_CANHandler.RTE_P_ComM_TCUErrLvl_Enum -> CtAp_ErrMgmt.RTE_R_ComM_TCUErrLvl_Enum
    connect CtAp_FctSftyMon.RTE_P_FctSftyMon_AccrPedlTqOverFltInfo_Bus -> CtAp_ErrMgmt.RTE_R_FctSftyMon_AccrPedlTqOverFltInfo_Bus
    connect CtAp_CANHandler.RTE_P_ComM_MCUFailrCodMsgErrInfo_Bus -> CtAp_ErrMgmt.RTE_R_ComM_MCUFailrCodMsgErrInfo_Bus
    connect CtAp_ComMErr.RTE_P_ComM_NodComFailr -> CtAp_ErrMgmt.RTE_R_ComM_NodComFailr
    connect CtAp_CANHandler.RTE_P_ComM_BMSSts01ErrInfo_Bus -> CtAp_ErrMgmt.RTE_R_ComM_BMSSts01ErrInfo_Bus
    connect CtAp_FctSftyMon.RTE_P_FctSftyMon_CrpCtrlTqOverFltInfo_Bus -> CtAp_ErrMgmt.RTE_R_FctSftyMon_CrpCtrlTqOverFltInfo_Bus
    connect CtAp_CANHandler.RTE_P_ComM_DCDCErrLvl_Enum -> CtAp_ErrMgmt.RTE_R_ComM_DCDCErrLvl_Enum
    connect CtAp_ErrMgmt.RTE_P_ErrMgmt_AcPause_Flg -> CtAp_OBCMgmt.RTE_R_ErrMgmt_AcPause_Flg
    connect CtAp_CANHandler.RTE_P_ComM_IBSACCMsgErrInfo_Bus -> CtAp_ChassisMgmt.RTE_R_ComM_IBSACCMsgErrInfo_Bus
    connect CtAp_CANHandler.RTE_P_ComM_IBSApsReqTqVld_Enum -> CtAp_ChassisMgmt.RTE_R_ComM_IBSApsReqTqVld_Flg
    connect CtAp_CANHandler.RTE_P_ComM_IBSApsReqTq_Nm -> CtAp_ChassisMgmt.RTE_R_ComM_IBSApsReqTq_Nm
    connect CtAp_CANHandler.RTE_P_ComM_IBSAvhSts_Enum -> CtAp_ChassisMgmt.RTE_R_ComM_IBSAvhSts_Enum
    connect CtAp_CANHandler.RTE_P_ComM_IBSBrkSts_Enum -> CtAp_ChassisMgmt.RTE_R_ComM_IBSBrkSts_Enum
    connect CtAp_CANHandler.RTE_P_ComM_IBSDecelReqAvl_Enum -> CtAp_ChassisMgmt.RTE_R_ComM_IBSDecelReqAvl_Enum
    connect CtAp_CANHandler.RTE_P_ComM_IBSHdcSts_Enum -> CtAp_ChassisMgmt.RTE_R_ComM_IBSHdcSts_Enum
    connect CtAp_CANHandler.RTE_P_ComM_IBSPlgrPrs_Bar -> CtAp_ChassisMgmt.RTE_R_ComM_IBSPlgrPrs_Bar
    connect CtAp_CANHandler.RTE_P_ComM_IBSRbsReqTq_Nm -> CtAp_ChassisMgmt.RTE_R_ComM_IBSRbsReqTq_Nm
    connect CtAp_CANHandler.RTE_P_ComM_IBSRbsSts_Enum -> CtAp_ChassisMgmt.RTE_R_ComM_IBSRbsSts_Enum
    connect CtAp_CANHandler.RTE_P_ComM_IBSVlcReqTq_Nm -> CtAp_ChassisMgmt.RTE_R_ComM_IBSVlcReqTq_Nm
    connect CtAp_CANHandler.RTE_P_ComM_IVIEnaBrkCmpMod_Enum -> CtAp_ChassisMgmt.RTE_R_ComM_IVIEnaBrkCmpMod_Enum
    connect CtAp_VehMot.RTE_P_VehMot_SlopGrd_pct -> CtAp_ChassisMgmt.RTE_R_VehMot_SlopGrd_pct
    connect CtAp_FctSftyMon.RTE_P_FctSftyMon_AccrPedlTqOverFltInfo_Bus -> CtAp_ChassisMgmt.RTE_R_FctSftyMon_AccrPedlTqOverFltInfo_Bus
    connect CtAp_ComMErr.RTE_P_ComM_NodComFailr -> CtAp_ChassisMgmt.RTE_R_ComM_NodComFailr
    connect CtAp_CANHandler.RTE_P_ComM_IBSReqRednTqSts_Flg -> CtAp_ChassisMgmt.RTE_R_ComM_IBSReqRednTqSts_Flg
    connect CtAp_FctSftyMon.RTE_P_FctSftyMon_CrpCtrlTqOverFltInfo_Bus -> CtAp_ChassisMgmt.RTE_R_FctSftyMon_CrpCtrlTqOverFltInfo_Bus
    connect CtAp_FctSftyMon.RTE_P_FctSftyMon_DesVehDecelSpdOverFltInfo_Bus -> CtAp_ChassisMgmt.RTE_R_FctSftyMon_DesVehDecelSpdOverFltInfo_Bus
    connect CtAp_TorqPahMgmt.RTE_P_TorqPahMgmt_MaxVehSpdLmtTq_Nm -> CtAp_ChassisMgmt.RTE_R_TorqPahMgmt_MaxVehSpdLmtTq_Nm
    connect CtAp_VehMot.RTE_P_VehMot_VehSpdVld_Flg -> CtAp_ChassisMgmt.RTE_R_VehMot_VehSpdVld_Flg
    connect CtAp_CANHandler.RTE_P_ComM_IBSApsTqActv_Flg -> CtAp_ChassisMgmt.RTE_R_ComM_IBSApsTqActv_Flg
    connect CtAp_CANHandler.RTE_P_ComM_IBSTqMsgErrInfo_Bus -> CtAp_ChassisMgmt.RTE_R_ComM_IBSTqMsgErrInfo_Bus
    connect CtAp_CANHandler.RTE_P_ComM_IBSVCUMotCtrlMsgErrInfo_Bus -> CtAp_ChassisMgmt.RTE_R_ComM_IBSVCUMotCtrlMsgErrInfo_Bus
    connect CtAp_ModMgmt.RTE_P_ModMgmt_ActRgnSts_Enum -> CtAp_ChassisMgmt.RTE_R_ModMgmt_ActRgnSts_Enum
    connect CtAp_VehMot.RTE_P_VehMot_VehSpd_kph -> CtAp_ChassisMgmt.RTE_R_VehMot_VehSpd_kph
    connect CtAp_ErrMgmt.RTE_P_ErrMgmt_VehSpdLimErrLv5_Flg -> CtAp_ChassisMgmt.RTE_R_ErrMgmt_VehSpdLimErrLv5_Flg
    connect CtAp_ErrMgmt.RTE_P_ErrMgmt_VehSpdLimErrLv6_Flg -> CtAp_ChassisMgmt.RTE_R_ErrMgmt_VehSpdLimErrLv6_Flg
    connect CtAp_CANHandler.RTE_P_ComM_IBSReqIncTq_Nm -> CtAp_ChassisMgmt.RTE_R_ComM_IBSReqIncTq_Nm
    connect CtAp_CANHandler.RTE_P_ComM_IBSReqRednTq_Nm -> CtAp_ChassisMgmt.RTE_R_ComM_IBSReqRednTq_Nm
    connect CtAp_ModMgmt.RTE_P_ModMgmt_HvSts_Enum -> CtAp_ChassisMgmt.RTE_R_ModMgmt_HvSts_Enum
    connect CtAp_ModMgmt.RTE_P_ModMgmt_ActDrvMod_Enum -> CtAp_ChassisMgmt.RTE_R_ModMgmt_ActDrvMod_Enum
    connect CtAp_VehMot.RTE_P_VehMot_VehDirDif_Flg -> CtAp_ChassisMgmt.RTE_R_VehMot_VehDirDif_Flg
    connect CtAp_CANHandler.RTE_P_ComM_IBSVlcReqTqVld_Flg -> CtAp_ChassisMgmt.RTE_R_ComM_IBSVlcReqTqVld_Flg
    connect CtAp_CANHandler.RTE_P_ComM_IBSVlcActv_Flg -> CtAp_ChassisMgmt.RTE_R_ComM_IBSVlcActv_Flg
    connect CtAp_CANHandler.RTE_P_ComM_IBSVdcActv_Flg -> CtAp_ChassisMgmt.RTE_R_ComM_IBSVdcActv_Flg
    connect CtAp_CANHandler.RTE_P_ComM_IBSTcsActv_Flg -> CtAp_ChassisMgmt.RTE_R_ComM_IBSTcsActv_Flg
    connect CtAp_CANHandler.RTE_P_ComM_IBSRwuActv_Flg -> CtAp_ChassisMgmt.RTE_R_ComM_IBSRwuActv_Flg
    connect CtAp_CANHandler.RTE_P_ComM_IBSDtcActv_Flg -> CtAp_ChassisMgmt.RTE_R_ComM_IBSDtcActv_Flg
    connect CtAp_CANHandler.RTE_P_ComM_IBSCdpActv_Flg -> CtAp_ChassisMgmt.RTE_R_ComM_IBSCdpActv_Flg
    connect CtAp_CANHandler.RTE_P_ComM_IBSAebActv_Flg -> CtAp_ChassisMgmt.RTE_R_ComM_IBSAebActv_Flg
    connect CtAp_CANHandler.RTE_P_ComM_IBSAbpActv_Flg -> CtAp_ChassisMgmt.RTE_R_ComM_IBSAbpActv_Flg
    connect CtAp_VehMot.RTE_P_VehMot_VehStdl_Flg -> CtAp_ChassisMgmt.RTE_R_VehMot_VehStdl_Flg
    connect CtAp_CANHandler.RTE_P_ComM_IBSSts02MsgErrInfo_Bus -> CtAp_ChassisMgmt.RTE_R_ComM_IBSSts02MsgErrInfo_Bus
    connect CtAp_CANHandler.RTE_P_ComM_IBSSts01MsgErrInfo_Bus -> CtAp_ChassisMgmt.RTE_R_ComM_IBSSts01MsgErrInfo_Bus
    connect CtAp_LvMgmt.RTE_P_LvMgmt_BSBattUDcNorm_Flg -> CtAp_ChassisMgmt.RTE_R_LvMgmt_BSBattUDcNorm_Flg
    connect CtAp_ErrMgmt.RTE_P_ErrMgmt_FobdEgyRcov_Flg -> CtAp_ChassisMgmt.RTE_R_ErrMgmt_FobdEgyRcov_Flg
    connect CtAp_CANHandler.RTE_P_ComM_IBSReqIncTqSts_Flg -> CtAp_ChassisMgmt.RTE_R_ComM_IBSReqIncTqSts_Flg
    connect CtAp_TorqPahMgmt.RTE_P_TorqPahMgmt_ReqMotDampSts_Enum -> CtAp_CANHandler.RTE_R_TorqPahMgmt_ReqMotDampSts_Enum
    connect CtAp_ChrMgmt.RTE_P_ChrMgmt_ChrgnRemnTim_min -> CtAp_CANHandler.RTE_R_ChrMgmt_ChrgnRemnTim_min
    connect CtAp_ChrMgmt.RTE_P_ChrMgmt_SngChrgEgy_kWh -> CtAp_CANHandler.RTE_R_ChrMgmt_SngChrgEgy_kWh
    connect CtAp_ChrMgmt.RTE_P_ChrMgmt_VCUDispChrgU_V -> CtAp_CANHandler.RTE_R_ChrMgmt_VCUDispChrgU_V
    connect CtAp_FctSftyMon.RTE_P_FctSftyMon_AccrPedlTqOverFltInfo_Bus -> CtAp_CANHandler.RTE_R_FctSftyMon_AccrPedlTqOverFltInfo_Bus
    connect CtAp_ChrMgmt.RTE_P_ChrMgmt_ChrgAbortRsn_Enum -> CtAp_CANHandler.RTE_R_ChrMgmt_ChrgAbortRsn_Enum
    connect CtAp_ChrMgmt.RTE_P_ChrMgmt_ChrgProcCmt_Enum -> CtAp_CANHandler.RTE_R_ChrMgmt_ChrgProcCmt_Enum
    connect CtAp_ChrMgmt.RTE_P_ChrMgmt_ChrgSts_Enum -> CtAp_CANHandler.RTE_R_ChrMgmt_ChrgSts_Enum
    connect CtAp_ChrMgmt.RTE_P_ChrMgmt_PlugSts_Enum -> CtAp_CANHandler.RTE_R_ChrMgmt_PlugSts_Enum
    connect CtAp_ChrMgmt.RTE_P_ChgMrmt_DchaAbortRsn_Enum -> CtAp_CANHandler.RTE_R_ChrMrmt_DchaAbortRsn_Enum
    connect CtAp_ErrMgmt.RTE_P_ErrMgmt_SysFailLamp_Enum -> CtAp_CANHandler.RTE_R_ErrMgmt_SysFailLamp_Enum
    connect CtAp_ChrMgmt.RTE_P_ChrMgmt_OBCSideSngDchaEgy_kWh -> CtAp_CANHandler.RTE_R_ChrMgmt_OBCSideSngDchaEgy_kWh
    connect CtAp_FctSftyMon.RTE_P_FctSftyMon_CrpCtrlTqOverFltInfo_Bus -> CtAp_CANHandler.RTE_R_FctSftyMon_CrpCtrlTqOverFltInfo_Bus
    connect CtAp_FctSftyMon.RTE_P_FctSftyMon_DesVehDecelSpdOverFltInfo_Bus -> CtAp_CANHandler.RTE_R_FctSftyMon_DesVehDecelSpdOverFltInfo_Bus
    connect CtAp_TorqPahMgmt.RTE_P_TorqPahMgmt_FwdMaxVehSpd_Enum -> CtAp_CANHandler.RTE_R_TorqPahMgmt_FwdMaxVehSpd_Enum
    connect CtAp_DCChrMgmt.RTE_P_DCChrMgmt_IRMeasSwtCtrl_Enum -> CtAp_CANHandler.RTE_R_DCChrMgmt_IRMeasSwtCtrl_Enum
    connect CtAp_ChassisMgmt.RTE_P_ChassisMgmt_BrkCmpWarn_Enum -> CtAp_CANHandler.RTE_R_ChassisMgmt_BrkCmpWarn_Enum
    connect CtAp_ChassisMgmt.RTE_P_ChassisMgmt_IBSApsReqTqActv_Flg -> CtAp_CANHandler.RTE_R_ChassisMgmt_IBSApsReqTqActv_Flg
    connect CtAp_ChassisMgmt.RTE_P_ChassisMgmt_IBSVlcReqTqActv_Flg -> CtAp_CANHandler.RTE_R_ChassisMgmt_IBSVlcReqTqActv_Flg
    connect CtAp_ChrMgmt.RTE_P_ChrMgmt_ChrgMemFlt_Flg -> CtAp_CANHandler.RTE_R_ChrMgmt_ChrgMemFlt_Flg
    connect CtAp_ErrMgmt.RTE_P_ErrMgmt_DCDCFailLamp_Flg -> CtAp_CANHandler.RTE_R_ErrMgmt_DCDCFailLamp_Flg
    connect CtAp_ErrMgmt.RTE_P_ErrMgmt_LimpHomeLamp_Flg -> CtAp_CANHandler.RTE_R_ErrMgmt_LimpHomeLamp_Flg
    connect CtAp_ErrMgmt.RTE_P_ErrMgmt_VehHVIL_Bus -> CtAp_CANHandler.RTE_R_ErrMgmt_VehHVIL_Bus
    connect CtAp_HvMgmt.RTE_P_HvMgmt_HVConnFlt_Flg -> CtAp_CANHandler.RTE_R_HvMgmt_HVConnFlt_Flg
    connect CtAp_TorqPahMgmt.RTE_P_TorqPahMgmt_MotActTq_Nm -> CtAp_CANHandler.RTE_R_TorqPahMgmt_MotActTq_Nm
    connect CtAp_TorqPahMgmt.RTE_P_TorqPahMgmt_WhlActTq_Nm -> CtAp_CANHandler.RTE_R_TorqPahMgmt_WhlActTq_Nm
    connect CtAp_ChrMgmt.RTE_P_ChrMgmt_ChrgTarSOC_pct -> CtAp_CANHandler.RTE_R_ChrMgmt_ChrgTarSOC_pct
    connect CtAp_ChassisMgmt.RTE_P_ChassisMgmt_AccrPedlVld_Flg -> CtAp_CANHandler.RTE_R_ChassisMgmt_AccrPedlVld_Flg
    connect CtAp_ChassisMgmt.RTE_P_ChassisMgmt_BrkCmpSts_Enum -> CtAp_CANHandler.RTE_R_ChassisMgmt_BrkCmpSts_Enum
    connect CtAp_ChassisMgmt.RTE_R_ChassisMgmt_BrkSts_Enum -> CtAp_CANHandler.RTE_R_ChassisMgmt_BrkSts_Enum
    connect CtAp_ChassisMgmt.RTE_P_ChassisMgmt_IBSApsReqTqAvl_Flg -> CtAp_CANHandler.RTE_R_ChassisMgmt_IBSApsReqTqAvl_Flg
    connect CtAp_ChassisMgmt.RTE_P_ChassisMgmt_IBSVlcReqTqAvl_Flg -> CtAp_CANHandler.RTE_R_ChassisMgmt_IBSVlcReqTqAvl_Flg
    connect CtAp_ChassisMgmt.RTE_P_ChassisMgmt_RgnTqCapVld_Flg -> CtAp_CANHandler.RTE_R_ChassisMgmt_RgnTqCapVld_Flg
    connect CtAp_DCChrMgmt.RTE_P_DCChrMgmt_MaxChrgIDc_A -> CtAp_CANHandler.RTE_R_DCChrMgmt_MaxChrgIDc_A
    connect CtAp_DCChrMgmt.RTE_P_DCChrMgmt_MinChrgIDc_A -> CtAp_CANHandler.RTE_R_DCChrMgmt_MinChrgIDc_A
    connect CtAp_HvMgmt.RTE_P_HvMgmt_ReqDCDCMod_Enum -> CtAp_CANHandler.RTE_R_HvMgmt_ReqDCDCMod_Enum
    connect CtAp_HvMgmt.RTE_P_HvMgmt_ReqTCUMod_Enum -> CtAp_CANHandler.RTE_R_HvMgmt_ReqTCUMod_Enum
    connect CtAp_ChassisMgmt.RTE_P_ChassisMgmt_DesVehDecelSpd_mps2q -> CtAp_CANHandler.RTE_R_ChassisMgmt_DesVehDecelSpd_mps2q
    connect CtAp_ChassisMgmt.RTE_P_ChassisMgmt_VehDecelSpdSts_Flg -> CtAp_CANHandler.RTE_R_ChassisMgmt_VehDecelSpdSts_Flg
    connect CtAp_ChrMgmt.RTE_P_ChrMgmt_ChrgTim_min -> CtAp_CANHandler.RTE_R_ChrMgmt_ChrgTim_min
    connect CtAp_ChrMgmt.RTE_P_ChrMgmt_VCUDispChrgI_A -> CtAp_CANHandler.RTE_R_ChrMgmt_VCUDispChrgI_A
    connect CtAp_TorqPahMgmt.RTE_P_TorqPahMgmt_DesMotTq_Nm -> CtAp_CANHandler.RTE_R_TorqPahMgmt_DesMotTq_Nm
    connect CtAp_ChrMgmt.RTE_P_ChrMgmt_ChrgPwr_kW -> CtAp_CANHandler.RTE_R_ChrMgmt_ChrgPwr_kW
    connect CtAp_ChassisMgmt.RTE_P_ChassisMgmt_RgnTqCap_Nm -> CtAp_CANHandler.RTE_R_ChassisMgmt_RgnTqCap_Nm
    connect CtAp_HvMgmt.RTE_P_HvMgmt_MCUReqSts_Enum -> CtAp_CANHandler.RTE_R_HvMgmt_MCUReqSts_Enum
    connect CtAp_ChrMgmt.RTE_P_ChrMgmt_DchaAbortSOC_pct -> CtAp_CANHandler.RTE_R_ChrMgmt_DchaAbortSOC_pct
    connect CtAp_HvMgmt.RTE_P_HvMgmt_DCDCDmdLvUDc_V -> CtAp_CANHandler.RTE_R_HvMgmt_DCDCDmdLvUDc_V
    connect CtAp_ChassisMgmt.RTE_P_ChassisMgmt_AccrPedlDesTq_Nm -> CtAp_CANHandler.RTE_R_ChassisMgmt_AccrPedlDesTq_Nm
    connect CtAp_DCChrMgmt.RTE_P_DCChrMgmt_MaxChrgUDc_V -> CtAp_CANHandler.RTE_R_DCChrMgmt_MaxChrgUDc_V
    connect CtAp_DCChrMgmt.RTE_P_DCChrMgmt_MinChrgUDc_V -> CtAp_CANHandler.RTE_R_DCChrMgmt_MinChrgUDc_V
    connect CtAp_ErrMgmt.RTE_P_ErrMgmt_InslaFlt_Bus -> CtAp_CANHandler.RTE_R_ErrMgmt_InslaFlt_Bus
    connect CtAp_ErrMgmt.RTE_P_ErrMgmt_VehErrLvl_Enum -> CtAp_CANHandler.RTE_R_ErrMgmt_VehErrLvl_Enum
    connect CtAp_LvMgmt.RTE_P_LvMgmt_KL15ActSts_Flg -> CtAp_CANHandler.RTE_R_LvMgmt_KL15ActSts_Flg
    connect CtAp_TorqPahMgmt.RTE_P_TorqPahMgmt_FwdMaxSpdSts_Flg -> CtAp_CANHandler.RTE_R_TorqPahMgmt_FwdMaxSpdSts_Flg
    connect CtAp_ChrMgmt.RTE_P_ChrMgmt_VCUCalcdPODIDc_A -> CtAp_CANHandler.RTE_R_ChrMgmt_VCUCalcdPODIDc_A
    connect CtAp_TorqPahMgmt.RTE_P_TorqPahMgmt_MotActTqVld_Flg -> CtAp_CANHandler.RTE_R_TorqPahMgmt_MotActTqVld_Flg
    connect CtAp_TorqPahMgmt.RTE_P_TorqPahMgmt_WhlActTqVld_Flg -> CtAp_CANHandler.RTE_R_TorqPahMgmt_WhlActTqVld_Flg
    connect CtAp_HvMgmt.RTE_P_HvMgmt_ReqModBMS_Enum -> CtAp_CANHandler.RTE_R_HvMgmt_ReqModBMS_Enum
    connect CtAp_ChassisMgmt.RTE_P_ChassisMgmt_AccrPedlPosn_pct -> CtAp_CANHandler.RTE_R_ChassisMgmt_AccrPedlPosn_pct
    connect CtAp_ChassisMgmt.RTE_P_ChassisMgmt_AccrPedlVld_Flg -> CtAp_VehMot.RTE_R_ChassisMgmt_AccrPedlVld_Flg
    connect CtAp_ChassisMgmt.RTE_R_ChassisMgmt_BrkSts_Enum -> CtAp_VehMot.RTE_R_ChassisMgmt_BrkSts_Enum
    connect CtAp_ChrMgmt.RTE_P_ChrMgmt_ChrgSts_Enum -> CtAp_EgyMgmt.RTE_R_ChrMgmt_ChrgSts_Enum
    connect CtAp_LvMgmt.RTE_P_LvMgmt_SelfChkSts_Flg -> CtAp_ModMgmt.RTE_R_LvMgmt_SelfChkSts_Flg
    connect CtAp_HvMgmt.RTE_P_HvMgmt_BMSPosRlyActSts_Enum -> CtAp_ModMgmt.RTE_R_HvMgmt_BMSPosRlyActSts_Enum
    connect CtAp_ChrMgmt.RTE_P_ChrMgmt_ReqHvRdy_Flg -> CtAp_HvMgmt.RTE_R_ChrMgmt_ReqHvRdy_Flg
    connect CtAp_ChrMgmt.RTE_P_ChrMgmt_PreheatPODDiReq_Flg -> CtAp_HvMgmt.RTE_R_ChrMgmt_PreheatPODDiReq_Flg
    connect CtAp_DCChrMgmt.RTE_P_DCChrMgmt_DCFCClsReq_Flg -> CtAp_HvMgmt.RTE_R_DCChrMgmt_DCFCClsReq_Flg
    connect CtAp_ComMErr.RTE_P_ComM_NodComFailr -> CtAp_RngEstimn.RTE_R_ComM_NodComFailr
    connect CtAp_ErrMgmt.RTE_P_ErrMgmt_EmgyHvDwn_Flg -> CtAp_HvMgmt.RTE_R_ErrMgmt_EmgyHvDwn_Flg
    connect CtAp_ErrMgmt.RTE_P_ErrMgmt_HvDwn_Flg -> CtAp_HvMgmt.RTE_R_ErrMgmt_HvDwn_Flg
    connect CtAp_ErrMgmt.RTE_P_ErrMgmt_Fobd2Hv_Flg -> CtAp_HvMgmt.RTE_R_ErrMgmt_Fobd2Hv_Flg
    connect CtAp_CANHandler.RTE_P_ComM_PODDcPosRlySts_Enum -> CtAp_HvMgmt.RTE_R_ComM_PODDcPosRlySts_Enum
    connect CtAp_ChrMgmt.RTE_P_ChrMgmt_ChrgSts_Enum -> CtAp_HvMgmt.RTE_R_ChrMgmt_ChrgSts_Enum
    connect CtAp_ChassisMgmt.RTE_P_ChassisMgmt_AccrPedlDesTq_Nm -> CtAp_FctSftyMon.RTE_R_ChassisMgmt_AccrPedlDesTq_Nm
    connect CtAp_ChassisMgmt.RTE_P_ChassisMgmt_CrpCtrlDesTq_Nm -> CtAp_FctSftyMon.RTE_R_ChassisMgmt_CrpCtrlDesTq_Nm
    connect CtAp_ChassisMgmt.RTE_P_ChassisMgmt_VehDecelSpdSts_Flg -> CtAp_FctSftyMon.RTE_R_ChassisMgmt_VehDecelSpdSts_Flg
    connect CtAp_ChassisMgmt.RTE_P_ChassisMgmt_DrvDmdHiPrio_Flg -> CtAp_TorqPahMgmt.RTE_R_ChassisMgmt_DrvDmdHiPrio_Flg
    connect CtAp_ChassisMgmt.RTE_P_ChassisMgmt_IBSIntvIncTqActv_Flg -> CtAp_TorqPahMgmt.RTE_R_ChassisMgmt_IBSIntvIncTqActv_Flg
    connect CtAp_ChrMgmt.RTE_P_ChrMgmt_ChrgSts_Enum -> CtAp_ErrMgmt.RTE_R_ChrMgmt_ChrgSts_Enum
    connect CtAp_VehMot.RTE_P_VehMot_VehSpdABS_kph -> CtAp_ErrMgmt.RTE_R_VehMot_VehSpdABS_kph
    connect CtAp_CANHandler.RTE_P_ComM_AcChrgPha_Enum -> CtAp_ChrMgmt.RTE_R_ComM_AcChrgPha_Enum
    connect CtAp_CANHandler.RTE_P_ComM_BMSChrgCmplSts_Enum -> CtAp_ChrMgmt.RTE_R_ComM_BMSChrgCmplSts_Enum
    connect CtAp_CANHandler.RTE_P_ComM_OBCInpIAc_A -> CtAp_ChrMgmt.RTE_R_ComM_OBCInpIAc_A
    connect CtAp_OBCMgmt.RTE_P_OBCMgmt_AcChrgnSts_Enum -> CtAp_ChrMgmt.RTE_R_OBCMgmt_AcChrgnSts_Enum
    connect CtAp_OBCMgmt.RTE_P_OBCMgmt_OBCOutpCpbyIDc_A -> CtAp_ChrMgmt.RTE_R_OBCMgmt_OBCOutpCpbyIDc_A
    connect CtAp_ChrMgmt.RTE_P_ChrMgmt_ChrgSts_Enum -> CtAp_ChrMgmt.RTE_R_ChrMgmt_ChrgSts_Enum
    connect CtAp_CANHandler.RTE_P_ComM_BMSBattIDc_A -> CtAp_ChrMgmt.RTE_R_ComM_BMSBattIDc_A
    connect CtAp_CANHandler.RTE_P_ComM_BMSBattRateCp_Ah -> CtAp_ChrMgmt.RTE_R_ComM_BMSBattRateCp_Ah
    connect CtAp_CANHandler.RTE_P_ComM_OBCOutpIDc_A -> CtAp_ChrMgmt.RTE_R_ComM_OBCOutpIDc_A
    connect CtAp_OBCMgmt.RTE_P_OBCMgmt_CPStsJmpErr_Bus -> CtAp_ChrMgmt.RTE_R_OBCMgmt_CPStsJmpErr_Bus
    connect CtAp_OBCMgmt.RTE_P_OBCMgmt_OBCChrgStsErr_Bus -> CtAp_ChrMgmt.RTE_R_OBCMgmt_OBCChrgStsErr_Bus
    connect CtAp_OBCMgmt.RTE_P_OBCMgmt_S2SwtClsErr_Bus -> CtAp_ChrMgmt.RTE_R_OBCMgmt_S2SwtClsErr_Bus
    connect CtAp_ComMErr.RTE_P_ComM_CANBusOffInfo_Bus -> CtAp_ChrMgmt.RTE_R_ComM_CANBusOffInfo_Bus
    connect CtAp_CANHandler.RTE_P_ComM_BCMAntithftSts_Enum -> CtAp_ChrMgmt.RTE_R_ComM_BCMAntithftSts_Enum
    connect CtAp_CANHandler.RTE_P_ComM_BMSChrgReqSts_Enum -> CtAp_ChrMgmt.RTE_R_ComM_BMSChrgReqSts_Enum
    connect CtAp_CANHandler.RTE_P_ComM_BMSChrgSts_Enum -> CtAp_ChrMgmt.RTE_R_ComM_BMSChrgSts_Enum
    connect CtAp_CANHandler.RTE_P_ComM_ElectcLockSts_Enum -> CtAp_ChrMgmt.RTE_R_ComM_ElectcLockSts_Enum
    connect CtAp_CANHandler.RTE_P_ComM_IVIChrgCmd_Enum -> CtAp_ChrMgmt.RTE_R_ComM_IVIChrgCmd_Enum
    connect CtAp_CANHandler.RTE_P_ComM_IVIMaxChrgSOCSet_pct -> CtAp_ChrMgmt.RTE_R_ComM_IVIMaxChrgSOCSet_pct
    connect CtAp_CANHandler.RTE_P_ComM_PEPSPwrMod_Enum -> CtAp_ChrMgmt.RTE_R_ComM_PEPSPwrMod_Enum
    connect CtAp_CANHandler.RTE_P_ComM_SGWChrgCmd_Enum -> CtAp_ChrMgmt.RTE_R_ComM_SGWChrgCmd_Enum
    connect CtAp_DCChrMgmt.RTE_P_DCChrMgmt_BEMTxReqSts_Enum -> CtAp_ChrMgmt.RTE_R_DCChrMgmt_BEMTxReqSts_Enum
    connect CtAp_DCChrMgmt.RTE_P_DCChrMgmt_DcChrgnMod_Enum -> CtAp_ChrMgmt.RTE_R_DCChrMgmt_DcChrgnMod_Enum
    connect CtAp_ErrMgmt.RTE_P_ErrMgmt_AcPause_Flg -> CtAp_ChrMgmt.RTE_R_ErrMgmt_AcPause_Flg
    connect CtAp_ErrMgmt.RTE_P_ErrMgmt_DcPause_Flg -> CtAp_ChrMgmt.RTE_R_ErrMgmt_DcPause_Flg
    connect CtAp_ErrMgmt.RTE_P_ErrMgmt_V2LStop_Flg -> CtAp_ChrMgmt.RTE_R_ErrMgmt_V2LStop_Flg
    connect CtAp_HvMgmt.RTE_P_HvMgmt_DCDCWrkModActSts_Enum -> CtAp_ChrMgmt.RTE_R_HvMgmt_DCDCWrkModActSts_Enum
    connect CtAp_HvMgmt.RTE_P_HvMgmt_DCFCWrkModActSts_Enum -> CtAp_ChrMgmt.RTE_R_HvMgmt_DCFCWrkModActSts_Enum
    connect CtAp_CANHandler.RTE_P_ComM_BMSRemnChrgTim_min -> CtAp_ChrMgmt.RTE_R_ComM_BMSRemnChrgTim_min
    connect CtAp_EgyMgmt.RTE_P_EgyMgmt_ACSysPwrCnsCalcn_Kw -> CtAp_ChrMgmt.RTE_R_EgyMgmt_ACSysPwrCnsCalcn_Kw
    connect CtAp_EgyMgmt.RTE_P_EgyMgmt_DCDCPwrCnsCalcn_Kw -> CtAp_ChrMgmt.RTE_R_EgyMgmt_DCDCPwrCnsCalcn_Kw
    connect CtAp_CANHandler.RTE_P_ComM_BMSBattDispSOC_pct -> CtAp_ChrMgmt.RTE_R_ComM_BMSBattDispSOC_pct
    connect CtAp_HvMgmt.RTE_P_HvMgmt_HvPwrOffReqChrgDwn_Flg -> CtAp_ChrMgmt.RTE_R_HvMgmt_HvPwrOffReqChrgDwn_Flg
    connect CtAp_OBCMgmt.RTE_P_OBCMgmt_OBCDchaStsErr_Bus -> CtAp_ChrMgmt.RTE_R_OBCMgmt_OBCDchaStsErr_Bus
    connect CtAp_OBCMgmt.RTE_P_OBCMgmt_OBCPreheatStsErr_Bus -> CtAp_ChrMgmt.RTE_R_OBCMgmt_OBCPreheatStsErr_Bus
    connect CtAp_ChrMgmt.RTE_P_ChrMgmt_ChrgTarSOC_pct -> CtAp_ChrMgmt.RTE_R_ChrMgmt_ChrgTarSOC_pct
    connect CtAp_CANHandler.RTE_P_ComM_BattMaxTemp_C -> CtAp_ChrMgmt.RTE_R_ComM_BattMaxTemp_C
    connect CtAp_CANHandler.RTE_P_ComM_BattMinTemp_C -> CtAp_ChrMgmt.RTE_R_ComM_BattMinTemp_C
    connect CtAp_CANHandler.RTE_P_ComM_ApptChrgMdlSts_Enum -> CtAp_ChrMgmt.RTE_R_ComM_ApptChrgMdlSts_Enum
    connect CtAp_CANHandler.RTE_P_ComM_OBCCCSts_Enum -> CtAp_ChrMgmt.RTE_R_ComM_OBCCCSts_Enum
    connect CtAp_CANHandler.RTE_P_ComM_OBCCPSts_Enum -> CtAp_ChrMgmt.RTE_R_ComM_OBCCPSts_Enum
    connect CtAp_CANHandler.RTE_P_ComM_OBCInpUAc_V -> CtAp_ChrMgmt.RTE_R_ComM_OBCInpUAc_V
    connect CtAp_CANHandler.RTE_P_ComM_OBCOutpUDc_V -> CtAp_ChrMgmt.RTE_R_ComM_OBCOutpUDc_V
    connect CtAp_CANHandler.RTE_P_ComM_PODDCFCUDc_V -> CtAp_ChrMgmt.RTE_R_ComM_PODDCFCUDc_V
    connect CtAp_DCChrMgmt.RTE_P_DCChrMgmt_IRMeasDiErr_Bus -> CtAp_ChrMgmt.RTE_R_DCChrMgmt_IRMeasDiErr_Bus
    connect CtAp_DCChrMgmt.RTE_P_DCChrMgmt_IRMeasEnaErr_Bus -> CtAp_ChrMgmt.RTE_R_DCChrMgmt_IRMeasEnaErr_Bus
    connect CtAp_EgyMgmt.RTE_P_EgyMgmt_PackPTCPwrCnsCalcn_Kw -> CtAp_ChrMgmt.RTE_R_EgyMgmt_PackPTCPwrCnsCalcn_Kw
    connect CtAp_HvMgmt.RTE_P_HvMgmt_BMSPosRlyActSts_Enum -> CtAp_ChrMgmt.RTE_R_HvMgmt_BMSPosRlyActSts_Enum
    connect CtAp_OBCMgmt.RTE_P_OBCMgmt_OBCDiErr_Bus -> CtAp_ChrMgmt.RTE_R_OBCMgmt_OBCDiErr_Bus
    connect CtAp_VehMot.RTE_P_VehMot_VehStdl_Flg -> CtAp_ChrMgmt.RTE_R_VehMot_VehStdl_Flg
    connect CtAp_DCChrMgmt.RTE_P_DCChrMgmt_DcPortTempErrLvl2_Bus -> CtAp_ChrMgmt.RTE_R_DCChrMgmt_DcPortTempErrLvl2_Bus
    connect CtAp_DCChrMgmt.RTE_P_DCChrMgmt_DcPortTempSnsrErr_Bus -> CtAp_ChrMgmt.RTE_R_DCChrMgmt_DcPortTempSnsrErr_Bus
    connect CtAp_LvMgmt.RTE_P_LvMgmt_BSBattUDcNorm_Flg -> CtAp_ChrMgmt.RTE_R_LvMgmt_BSBattUDcNorm_Flg
    connect CtAp_CANHandler.RTE_P_ComM_BMSKeepWrmReq_Enum -> CtAp_ChrMgmt.RTE_R_ComM_BMSKeepWrmReq_Enum
    connect CtAp_CANHandler.RTE_P_ComM_BMSKeepWrmSts_Enum -> CtAp_ChrMgmt.RTE_R_ComM_BMSKeepWrmSts_Enum
    connect CtAp_CANHandler.RTE_P_ComM_IVIDchaSwtSts_Enum -> CtAp_ChrMgmt.RTE_R_ComM_IVIDchaSwtSts_Enum
    connect CtAp_CANHandler.RTE_P_ComM_PODDcPosRlySts_Enum -> CtAp_ChrMgmt.RTE_R_ComM_PODDcPosRlySts_Enum
    connect CtAp_CANHandler.RTE_P_ComM_SysIRVal_kOhm -> CtAp_ChrMgmt.RTE_R_ComM_SysIRVal_kOhm
    connect CtAp_DCChrMgmt.RTE_P_DCChrMgmt_DcChrgnSts_Enum -> CtAp_ChrMgmt.RTE_R_DCChrMgmt_DcChrgnSts_Enum
    connect CtAp_CANHandler.RTE_P_ComM_BMSBattLnkUDc_V -> CtAp_ChrMgmt.RTE_R_ComM_BMSBattLnkUDc_V
    connect CtAp_CANHandler.RTE_P_ComM_BMSBattPckUDc_V -> CtAp_ChrMgmt.RTE_R_ComM_BMSBattPckUDc_V
    connect CtAp_HvMgmt.RTE_P_HvMgmt_TCUWrkModActSts_Enum -> CtAp_ChrMgmt.RTE_R_HvMgmt_TCUWrkModActSts_Enum
    connect CtAp_ErrMgmt.RTE_P_ErrMgmt_VehErrLvl_Enum -> CtAp_ChrMgmt.RTE_R_ErrMgmt_VehErrLvl_Enum
    connect CtAp_ModMgmt.RTE_P_ModMgmt_HvSts_Enum -> CtAp_ChrMgmt.RTE_R_ModMgmt_HvSts_Enum
    connect CtAp_CANHandler.RTE_P_ComM_BMSBattUDc_V -> CtAp_ChrMgmt.RTE_R_ComM_BMSBattUDc_V
    connect CtAp_CANHandler.RTE_P_ComM_IVIMinDchaSOCSet_Enum -> CtAp_ChrMgmt.RTE_R_ComM_IVIMinDchaSOCSet_Enum
    connect CtAp_CANHandler.RTE_P_ComM_OBCChrgSts_Enum -> CtAp_ChrMgmt.RTE_R_ComM_OBCChrgSts_Enum
    connect CtAp_ComMErr.RTE_P_ComM_NodComFailr -> CtAp_ChrMgmt.RTE_R_ComM_NodComFailr
    connect CtAp_ErrMgmt.RTE_P_ErrMgmt_AcStop_Flg -> CtAp_ChrMgmt.RTE_R_ErrMgmt_AcStop_Flg
    connect CtAp_OBCMgmt.RTE_P_OBCMgmt_OBCInpUDcLoErr_Bus -> CtAp_ChrMgmt.RTE_R_OBCMgmt_OBCInpUDcLoErr_Bus
    connect CtAp_ErrMgmt.RTE_P_ErrMgmt_DcStop_Flg -> CtAp_ChrMgmt.RTE_R_ErrMgmt_DcStop_Flg
    connect CtAp_ChrMgmt.RTE_P_ChrMgmt_OBCEnaAllwd_Flg -> CtAp_OBCMgmt.RTE_R_ChrMgmt_OBCEnaAllwd_Flg
    connect CtAp_ChrMgmt.RTE_P_ChrMgmt_PreheatSts_Enum -> CtAp_OBCMgmt.RTE_R_ChrMgmt_PreheatSts_Enum
    connect CtAp_ChrMgmt.RTE_P_ChrMgmt_KeepWrm_Flg -> CtAp_OBCMgmt.RTE_R_ChrMgmt_KeepWrm_Flg
    connect CtAp_ChrMgmt.RTE_P_ChrMgmt_OBCCtrlMdlSts_Enum -> CtAp_OBCMgmt.RTE_R_ChrMgmt_OBCCtrlMdlSts_Enum
    connect CtAp_ChrMgmt.RTE_P_ChrMgmt_ChrgSts_Enum -> CtAp_OBCMgmt.RTE_R_ChrMgmt_ChrgSts_Enum
    connect CtAp_ErrMgmt.RTE_P_ErrMgmt_TorqCtrlErr_Bus -> CtAp_TorqPahMgmt.RTE_R_ErrMgmt_TorqCtrlErr_Bus
    connect CtAp_ChassisMgmt.RTE_P_ChassisMgmt_IBSIntvRednTqActv_Flg -> CtAp_TorqPahMgmt.RTE_R_ChassisMgmt_IBSIntvRednTqActv_Flg
    connect CtAp_ComMErr.RTE_P_ComM_NodComFailr -> CtAp_EgyMgmt.RTE_R_ComM_NodComFailr
    connect CtAp_CANHandler.RTE_P_ComM_AbortErrIDc_Enum -> CtAp_DCChrMgmt.RTE_R_ComM_AbortErrIDc_Enum
    connect CtAp_CANHandler.RTE_P_ComM_AbortErrUDc_Enum -> CtAp_DCChrMgmt.RTE_R_ComM_AbortErrUDc_Enum
    connect CtAp_CANHandler.RTE_P_ComM_AbortFltBattTemp_Enum -> CtAp_DCChrMgmt.RTE_R_ComM_AbortFltBattTemp_Enum
    connect CtAp_CANHandler.RTE_P_ComM_AbortFltBMSTemp_Enum -> CtAp_DCChrMgmt.RTE_R_ComM_AbortFltBMSTemp_Enum
    connect CtAp_CANHandler.RTE_P_ComM_ChrgnRchTarTotUDc_Enum -> CtAp_DCChrMgmt.RTE_R_ComM_ChrgnRchTarTotUDc_Enum
    connect CtAp_ChrMgmt.RTE_P_ChrMgmt_ChrgSts_Enum -> CtAp_DCChrMgmt.RTE_R_ChrMgmt_ChrgSts_Enum
    connect CtAp_ChrMgmt.RTE_P_ChrMgmt_DcChrgCmplSts_Enum -> CtAp_DCChrMgmt.RTE_R_ChrMgmt_DcChrgCmplSts_Enum
    connect CtAp_CANHandler.RTE_P_ComM_BMSErrInfoTimeoutInfo_Bus -> CtAp_DCChrMgmt.RTE_R_ComM_BMSErrInfoTimeoutInfo_Bus
    connect CtAp_ComMErr.RTE_P_ComM_CANBusOffInfo_Bus -> CtAp_DCChrMgmt.RTE_R_ComM_CANBusOffInfo_Bus
    connect CtAp_CANHandler.RTE_P_ComM_BMSErrRlySts_Enum -> CtAp_DCChrMgmt.RTE_R_ComM_BMSErrRlySts_Enum
    connect CtAp_CANHandler.RTE_P_ComM_BMSIRDetnSts_Enum -> CtAp_DCChrMgmt.RTE_R_ComM_BMSIRDetnSts_Enum
    connect CtAp_CANHandler.RTE_P_ComM_BMSInslaErrLvl_Enum -> CtAp_DCChrMgmt.RTE_R_ComM_BMSInslaErrLvl_Enum
    connect CtAp_CANHandler.RTE_P_ComM_BMSSOCErrHiSts_Enum -> CtAp_DCChrMgmt.RTE_R_ComM_BMSSOCErrHiSts_Enum
    connect CtAp_CANHandler.RTE_P_ComM_BMSSOCErrLoSts_Enum -> CtAp_DCChrMgmt.RTE_R_ComM_BMSSOCErrLoSts_Enum
    connect CtAp_CANHandler.RTE_P_ComM_ChrgnIDcErrSts_Enum -> CtAp_DCChrMgmt.RTE_R_ComM_ChrgnIDcErrSts_Enum
    connect CtAp_CANHandler.RTE_P_ComM_ChrgnRchSetVal_Enum -> CtAp_DCChrMgmt.RTE_R_ComM_ChrgnRchSetVal_Enum
    connect CtAp_CANHandler.RTE_P_ComM_MaxCellUDcErrSts_Enum -> CtAp_DCChrMgmt.RTE_R_ComM_MaxCellUDcErrSts_Enum
    connect CtAp_CANHandler.RTE_P_ComM_MinCellUDcErrSts_Enum -> CtAp_DCChrMgmt.RTE_R_ComM_MinCellUDcErrSts_Enum
    connect CtAp_ErrMgmt.RTE_P_ErrMgmt_DcPause_Flg -> CtAp_DCChrMgmt.RTE_R_ErrMgmt_DcPause_Flg
    connect CtAp_ErrMgmt.RTE_P_ErrMgmt_VCUHVILErr_Flg -> CtAp_DCChrMgmt.RTE_R_ErrMgmt_VCUHVILErr_Flg
    connect CtAp_HvMgmt.RTE_P_HvMgmt_DCFCWrkModActSts_Enum -> CtAp_DCChrMgmt.RTE_R_HvMgmt_DCFCWrkModActSts_Enum
    connect CtAp_ChrMgmt.RTE_P_ChrMgmt_VCUCalcdPODInitIDc_A -> CtAp_DCChrMgmt.RTE_R_ChrMgmt_VCUCalcdPODInitIDc_A
    connect CtAp_EgyMgmt.RTE_P_EgyMgmt_ACSysPwrCnsCalcn_Kw -> CtAp_DCChrMgmt.RTE_R_EgyMgmt_ACSysPwrCnsCalcn_Kw
    connect CtAp_EgyMgmt.RTE_P_EgyMgmt_DCDCPwrCnsCalcn_Kw -> CtAp_DCChrMgmt.RTE_R_EgyMgmt_DCDCPwrCnsCalcn_Kw
    connect CtAp_CANHandler.RTE_P_ComM_BMSBattDispSOC_pct -> CtAp_DCChrMgmt.RTE_R_ComM_BMSBattDispSOC_pct
    connect CtAp_ChrMgmt.RTE_P_ChrMgmt_VCUCalcdPODIDc_A -> CtAp_DCChrMgmt.RTE_R_ChrMgmt_VCUCalcdPODIDc_A
    connect CtAp_CANHandler.RTE_P_ComM_BMSCellHiTempErr_Enum -> CtAp_DCChrMgmt.RTE_R_ComM_BMSCellHiTempErr_Enum
    connect CtAp_CANHandler.RTE_P_ComM_ChrgnRchTarCellUDc_Enum -> CtAp_DCChrMgmt.RTE_R_ComM_ChrgnRchTarCellUDc_Enum
    connect CtAp_CANHandler.RTE_P_ComM_DcInletASnsrSts_Enum -> CtAp_DCChrMgmt.RTE_R_ComM_DcInletASnsrSts_Enum
    connect CtAp_CANHandler.RTE_P_ComM_DcInletATemp_C -> CtAp_DCChrMgmt.RTE_R_ComM_DcInletATemp_C
    connect CtAp_CANHandler.RTE_P_ComM_DcInletBSnsrSts_Enum -> CtAp_DCChrMgmt.RTE_R_ComM_DcInletBSnsrSts_Enum
    connect CtAp_CANHandler.RTE_P_ComM_DcInletBTemp_C -> CtAp_DCChrMgmt.RTE_R_ComM_DcInletBTemp_C
    connect CtAp_CANHandler.RTE_P_ComM_PODDCFCUDc_V -> CtAp_DCChrMgmt.RTE_R_ComM_PODDCFCUDc_V
    connect CtAp_CANHandler.RTE_P_ComM_BMSBattAllowChrgIDc_A -> CtAp_DCChrMgmt.RTE_R_ComM_BMSBattAllowChrgIDc_A
    connect CtAp_EgyMgmt.RTE_P_EgyMgmt_PackPTCPwrCnsCalcn_Kw -> CtAp_DCChrMgmt.RTE_R_EgyMgmt_PackPTCPwrCnsCalcn_Kw
    connect CtAp_ChrMgmt.RTE_P_ChrMgmt_PreheatSts_Enum -> CtAp_DCChrMgmt.RTE_R_ChrMgmt_PreheatSts_Enum
    connect CtAp_CANHandler.RTE_P_ComM_PODSts01TimeoutInfo_Bus -> CtAp_DCChrMgmt.RTE_R_ComM_PODSts01TimeoutInfo_Bus
    connect CtAp_CANHandler.RTE_P_ComM_BMSSts01ErrInfo_Bus -> CtAp_DCChrMgmt.RTE_R_ComM_BMSSts01ErrInfo_Bus
    connect CtAp_LvMgmt.RTE_P_LvMgmt_BSBattUDcNorm_Flg -> CtAp_DCChrMgmt.RTE_R_LvMgmt_BSBattUDcNorm_Flg
    connect CtAp_ChrMgmt.RTE_P_ChrMgmt_DcChrgAllwd_Flg -> CtAp_DCChrMgmt.RTE_R_ChrMgmt_DcChrgAllwd_Flg
    connect CtAp_CANHandler.RTE_P_ComM_BMSHVILSts_Flg -> CtAp_DCChrMgmt.RTE_R_ComM_BMSHVILSts_Flg
    connect CtAp_CANHandler.RTE_P_ComM_BattChrgnModReq_Enum -> CtAp_DCChrMgmt.RTE_R_ComM_BattChrgnModReq_Enum
    connect CtAp_CANHandler.RTE_P_ComM_PODDcPosRlySts_Enum -> CtAp_DCChrMgmt.RTE_R_ComM_PODDcPosRlySts_Enum
    connect CtAp_ChassisMgmt.RTE_P_ChassisMgmt_DesVehDecelSpd_mps2q -> CtAp_FctSftyMon.RTE_R_ChassisMgmt_DesVehDecelSpd_mps2q
    connect CtAp_CANHandler.RTE_P_ComM_BMSBattMaxChrgnUDc_V -> CtAp_DCChrMgmt.RTE_R_ComM_BMSBattMaxChrgnUDc_V
    connect CtAp_CANHandler.RTE_P_ComM_BMSBattLnkUDc_V -> CtAp_DCChrMgmt.RTE_R_ComM_BMSBattLnkUDc_V
    connect CtAp_CANHandler.RTE_P_ComM_BMSBattPckUDc_V -> CtAp_DCChrMgmt.RTE_R_ComM_BMSBattPckUDc_V
    connect CtAp_ModMgmt.RTE_P_ModMgmt_HvSts_Enum -> CtAp_DCChrMgmt.RTE_R_ModMgmt_HvSts_Enum
    connect CtAp_ChrMgmt.RTE_P_ChrMgmt_ReqLvActv_Flg -> CtAp_LvMgmt.RTE_R_ChrMgmt_ReqLvActv_Flg
    connect CtAp_ChassisMgmt.RTE_P_ChassisMgmt_LimpHome_Flg -> CtAp_ErrMgmt.RTE_R_ChassisMgmt_LimpHomeSts_Flg
    connect CtAp_ChassisMgmt.RTE_P_ChassisMgmt_ErrResBrkPedlFlt_Flg -> CtAp_ErrMgmt.RTE_R_ChassisMgmt_ErrResBrkPedlFlt_Flg
    connect CtAp_TorqPahMgmt.RTE_P_TorqPahMgmt_EmacQstyMaxTq_Nm -> CtAp_ChassisMgmt.RTE_R_TorqPahMgmt_EmacQstyMaxTq_Nm
    connect CtAp_TorqPahMgmt.RTE_P_TorqPahMgmt_EmacQstyMinTq_Nm -> CtAp_ChassisMgmt.RTE_R_TorqPahMgmt_EmacQstyMinTq_Nm
    connect CtAp_ErrMgmt.RTE_P_ErrMgmt_DlyGrdtZeroTq_Flg -> CtAp_ChassisMgmt.RTE_R_ErrMgmt_DlyGrdtZeroTq_Flg
    connect CtAp_ErrMgmt.RTE_P_ErrMgmt_GrdtZeroTq_Flg -> CtAp_ChassisMgmt.RTE_R_ErrMgmt_GrdtZeroTq_Flg
    connect CtAp_ErrMgmt.RTE_P_ErrMgmt_ImdtZeroTq_Flg -> CtAp_ChassisMgmt.RTE_R_ErrMgmt_ImdtZeroTq_Flg
    connect CtAp_CANHandler.RTE_P_ComM_OBCSide1OvrTempFlt_Flg -> CtAp_ErrMgmt.RTE_R_ComM_OBCSide1OvrTempFlt_Flg
    connect CtAp_ErrMgmt.RTE_P_ErrMgmt_DrvMotTempOvrLamp_Bus -> CtAp_CANHandler.RTE_R_ErrMgmt_DrvMotTempOvrLamp_Bus
    connect CtAp_ErrMgmt.RTE_P_ErrMgmt_HvBattTempOvrLamp_Bus -> CtAp_CANHandler.RTE_R_ErrMgmt_HvBattTempOvrLamp_Bus
    connect CtAp_CANHandler.RTE_P_ComM_OBCSide2OvrTempFlt_Flg -> CtAp_ErrMgmt.RTE_R_ComM_OBCSide2OvrTempFlt_Flg
    connect CtAp_CANHandler.RTE_P_ComM_DCDCSide2OvrTempFlt_Flg -> CtAp_ErrMgmt.RTE_R_ComM_DCDCSide2OvrTempFlt_Flg
    connect CtAp_TorqPahMgmt.RTE_P_TorqPahMgmt_EmacQstyMinTq_Nm -> CtAp_CANHandler.RTE_R_TorqPahMgmt_EmacQstyMinTq_Nm
    connect CtAp_DCChrMgmt.RTE_P_DCChrMgmt_DcChrgStrt_Flg -> CtAp_CANHandler.RTE_R_DCChrMgmt_DcChrgStrt_Flg
    connect CtAp_LvMgmt.RTE_P_LvMgmt_BSBattUDcNorm_Flg -> CtAp_CANHandler.RTE_R_LvMgmt_BSBattUDcNorm_Flg
    connect CtAp_CANHandler.RTE_P_ComM_BMSBattRemnCp_Ah -> CtAp_RngEstimn.RTE_R_ComM_BMSBattRemnCp_Ah
    connect CtAp_ChassisMgmt.RTE_P_ChassisMgmt_IBSDesRednTq_Nm -> CtAp_TorqPahMgmt.RTE_R_ChassisMgmt_IBSDesRednTq_Nm
    connect CtAp_CANHandler.RTE_P_ComM_IBSRbsReqTqVld_Enum -> CtAp_ChassisMgmt.RTE_R_ComM_IBSRbsReqTqVld_Enum
    connect CtAp_ErrMgmt.RTE_P_ErrMgmt_HVILPwmFrq_Hz -> CtAp_HWHandler.RTE_R_ErrMgmt_HVILPwmFrq_Hz
    connect CtAp_LvMgmt.RTE_P_LvMgmt_KL15CtrlReq_Flg -> CtAp_HWHandler.RTE_R_LvMgmt_KL15CtrlReq_Flg
    connect CtAp_HWHandler.RTE_P_IOAbs_BSBattUDc_V -> CtAp_LvMgmt.RTE_R_IOAbs_BSBattUDc_V
    connect CtAp_HWHandler.RTE_P_IOAbs_KL15eFb_Flg -> CtAp_LvMgmt.RTE_R_IOAbs_KL15eFb_Flg
    connect CtAp_HWHandler.RTE_P_IOAbs_HVILPwmFrq_Hz -> CtAp_ErrMgmt.RTE_R_IOAbs_HVILPwmFrq_Hz
    connect CtAp_HWHandler.RTE_P_IOAbs_AccrPedlMaiRaw_mV -> CtAp_ChassisMgmt.RTE_R_IOAbs_AccrPedlMaiRaw_mV
    connect CtAp_HWHandler.RTE_P_IOAbs_AccrPedlRdnRaw_mV -> CtAp_ChassisMgmt.RTE_R_IOAbs_AccrPedlRdnRaw_mV
    connect CtAp_HWHandler.RTE_P_IOAbs_CC2SigUDc_mV -> CtAp_ChrMgmt.RTE_R_IOAbs_CC2SigUDc_mV
    connect CtAp_HWHandler.RTE_P_IOAbs_CC2SigUDc_mV -> CtAp_DCChrMgmt.RTE_R_IOAbs_CC2SigUDc_mV
    connect CtAp_TorqPahMgmt.RTE_P_TorqPahMgmt_EmacQstyMaxTq_Nm -> CtAp_CANHandler.RTE_R_TorqPahMgmt_EmacQstyMaxTq_Nm
    connect CtAp_CANHandler.RTE_P_ComM_IBSBrkStsVld_Flg -> CtAp_ChassisMgmt.RTE_R_ComM_IBSBrkStsVld_Flg
    connect YDF_WakeUp_Swc.Ecu_SBCWakeStatus -> YDF_NMHandler.Ecu_SBCWakeStatus
    connect YDF_WakeUp_Swc.Ecu_PTCANWakeStatus -> YDF_NMHandler.Ecu_PTCANWakeStatus
    connect YDF_WakeUp_Swc.Ecu_LinWakeStatus -> YDF_NMHandler.Ecu_LinWakeStatus
    connect YDF_WakeUp_Swc.Ecu_KeyWakeStatus -> YDF_NMHandler.Ecu_KeyWakeStatus
    connect YDF_WakeUp_Swc.Ecu_ETHWakeStatus -> YDF_NMHandler.Ecu_ETHWakeStatus
    connect YDF_WakeUp_Swc.Ecu_AccWakeStatus -> YDF_NMHandler.Ecu_AccWakeStatus
    connect YDF_WakeUp_Swc.Ecu_CHCANWakeStatus -> YDF_NMHandler.Ecu_CHCANWakeStatus
    connect YDF_WakeUp_Swc.Ecu_ChargeWakeStatus -> YDF_NMHandler.Ecu_ChargeWakeStatus
    connect YDF_WakeUp_Swc.Ecu_12VInWakeStatus -> YDF_NMHandler.Ecu_12VInWakeStatus
    delegate CtAp_DCComM.BCP_AllowChargeVoltageMax <-> outer port BCP_AllowChargeVoltageMax
    delegate CtAp_DCComM.BCP_AllowTempMax <-> outer port BCP_AllowTempMax
    delegate CtAp_DCComM.BCP_BatteryChargeVoltageMax <-> outer port BCP_BatteryChargeVoltageMax
    delegate CtAp_DCComM.BCP_BatteryNominalEnergy <-> outer port BCP_BatteryNominalEnergy
    delegate CtAp_DCComM.BCP_BatteryTotalVoltage <-> outer port BCP_BatteryTotalVoltage
    delegate CtAp_DCComM.BCP_ChargeCurrentMax <-> outer port BCP_ChargeCurrentMax
    delegate CtAp_DCComM.BCP_SOC <-> outer port BCP_SOC
    delegate CtAp_DCComM.BCS_BatteryVoltMax <-> outer port BCS_BatteryVoltMax
    delegate CtAp_DCComM.BCS_BatteryVoltMaxGroup <-> outer port BCS_BatteryVoltMaxGroup
    delegate CtAp_DCComM.BCS_ChargeCurrentMeasure <-> outer port BCS_ChargeCurrentMeasure
    delegate CtAp_DCComM.BCS_ChargeVoltageMeasure <-> outer port BCS_ChargeVoltageMeasure
    delegate CtAp_DCComM.BCS_EstimatedTimeRemaining <-> outer port BCS_EstimatedTimeRemaining
    delegate CtAp_DCComM.BCS_SOC <-> outer port BCS_SOC
    delegate CtAp_DCComM.BRM_BatteryChargeTimes <-> outer port BRM_BatteryChargeTimes
    delegate CtAp_DCComM.BRM_BatteryProductDay <-> outer port BRM_BatteryProductDay
    delegate CtAp_DCComM.BRM_BatteryProductMonth <-> outer port BRM_BatteryProductMonth
    delegate CtAp_DCComM.BRM_BatteryProductYear <-> outer port BRM_BatteryProductYear
    delegate CtAp_DCComM.BRM_BatteryProperty <-> outer port BRM_BatteryProperty
    delegate CtAp_DCComM.BRM_BatterySN <-> outer port BRM_BatterySN
    delegate CtAp_DCComM.BRM_BatterySystemRatedCapacity <-> outer port BRM_BatterySystemRatedCapacity
    delegate CtAp_DCComM.BRM_BatterySystemRatedVoltage <-> outer port BRM_BatterySystemRatedVoltage
    delegate CtAp_DCComM.BRM_BatteryType <-> outer port BRM_BatteryType
    delegate CtAp_DCComM.BRM_Manufacturer <-> outer port BRM_Manufacturer
    delegate CtAp_DCComM.BRM_ProtocolVersion <-> outer port BRM_ProtocolVersion
    delegate CtAp_DCComM.BRM_VehicleIdByte1_8 <-> outer port BRM_VehicleIdByte1_8
    delegate CtAp_DCComM.BRM_VehicleIdByte17 <-> outer port BRM_VehicleIdByte17
    delegate CtAp_DCComM.BRM_VehicleIdByte9_16 <-> outer port BRM_VehicleIdByte9_16
    delegate CtAp_DCComM.BSD_AbortSOC <-> outer port BSD_AbortSOC
    delegate CtAp_DCComM.BSD_BatteryTempMax <-> outer port BSD_BatteryTempMax
    delegate CtAp_DCComM.BSD_BatteryTempMin <-> outer port BSD_BatteryTempMin
    delegate CtAp_DCComM.BSD_BatteryVoltageMax <-> outer port BSD_BatteryVoltageMax
    delegate CtAp_DCComM.BSD_BatteryVoltageMin <-> outer port BSD_BatteryVoltageMin
    delegate CtAp_DCComM.BSM_BatteryTempMax <-> outer port BSM_BatteryTempMax
    delegate CtAp_DCComM.BSM_BatteryTempMaxNo <-> outer port BSM_BatteryTempMaxNo
    delegate CtAp_DCComM.BSM_BatteryTempMin <-> outer port BSM_BatteryTempMin
    delegate CtAp_DCComM.BSM_BatteryTempMinNo <-> outer port BSM_BatteryTempMinNo
    delegate CtAp_DCComM.BSM_BatteryVoltageMaxNo <-> outer port BSM_BatteryVoltageMaxNo
    delegate CtAp_DCComM.CTS_Year <-> outer port CTS_Year
    connect YDF_NVMgmt.RTE_RP_RngEstimnInfo -> CtAp_RngEstimn.RTE_RP_RngEstimnInfo
    connect YDF_NMHandler.IF_ComM_BMSPNC15 -> CtAp_CANHandler.RTE_R_ComM_BMSPNC15
    connect YDF_NMHandler.IF_ComM_CGWPNC0 -> CtAp_CANHandler.RTE_R_ComM_CGWPNC0
    connect YDF_NMHandler.IF_ComM_BMSPNC16 -> CtAp_CANHandler.RTE_R_ComM_BMSPNC16
    connect YDF_NMHandler.IF_ComM_CGWPNC2 -> CtAp_CANHandler.RTE_R_ComM_CGWPNC2
    connect CtAp_ErrMgmt.RTE_P_ErrMgmt_HvBattFailLamp -> CtAp_CANHandler.RTE_R_ErrMgmt_HvBattFailLamp
    connect YDF_NMHandler.IF_ComM_CGWPNC1 -> CtAp_CANHandler.RTE_R_ComM_CGWPNC1
    connect YDF_NMHandler.IF_ComM_CGWPNC13 -> CtAp_CANHandler.RTE_R_ComM_CGWPNC13
    connect YDF_NMHandler.IF_ComM_CGWPNC3 -> CtAp_CANHandler.RTE_R_ComM_CGWPNC3
    connect YDF_NMHandler.IF_ComM_CGWPNC15 -> CtAp_CANHandler.RTE_R_ComM_CGWPNC15
    connect YDF_NMHandler.IF_ComM_CGWPNC14 -> CtAp_CANHandler.RTE_R_ComM_CGWPNC14
    connect YDF_NMHandler.IF_ComM_CGWPNC17 -> CtAp_CANHandler.RTE_R_ComM_CGWPNC17
    connect YDF_NMHandler.IF_ComM_CGWPNC16 -> CtAp_CANHandler.RTE_R_ComM_CGWPNC16
    connect YDF_NMHandler.IF_ComM_CGWPNC21 -> CtAp_CANHandler.RTE_R_ComM_CGWPNC21
    connect YDF_NMHandler.IF_ComM_VCUPNC2 -> CtAp_CANHandler.RTE_R_ComM_VCUPNC2
    connect YDF_NMHandler.IF_ComM_VCUPNC1 -> CtAp_CANHandler.RTE_R_ComM_VCUPNC1
    connect YDF_NMHandler.IF_ComM_VCUPNC14 -> CtAp_CANHandler.RTE_R_ComM_VCUPNC14
    connect YDF_NMHandler.IF_ComM_VCUPNC13 -> CtAp_CANHandler.RTE_R_ComM_VCUPNC13
    connect YDF_NMHandler.IF_ComM_VCUPNC3 -> CtAp_CANHandler.RTE_R_ComM_VCUPNC3
    connect YDF_NMHandler.IF_ComM_VCUPNC17 -> CtAp_CANHandler.RTE_R_ComM_VCUPNC17
    connect YDF_NMHandler.IF_ComM_VCUPNC16 -> CtAp_CANHandler.RTE_R_ComM_VCUPNC16
    connect YDF_NMHandler.IF_ComM_VCUPNC21 -> CtAp_CANHandler.RTE_R_ComM_VCUPNC21
    connect CtAp_ErrMgmt.RTE_P_ErrMgmt_MCUFltLamp -> CtAp_CANHandler.RTE_R_ErrMgmt_MCUFltLamp
    connect CtAp_CANHandler.RTE_P_ComM_ACUInfoMsgErrInfo_Bus -> CtAp_ComMErr.RTE_R_ComM_ACUInfoMsgErrInfo_Bus
    delegate CtAp_DCComM.CRO_ChargerReady <-> outer port CRO_ChargerReady
    connect CtAp_DCChrMgmt.RTE_P_DCChrMgmt_BSTChrgCnctErrSts_Enum -> CtAp_DCComM.RTE_R_DCChrMgmt_BSTChrgCnctErrSts_Enum
    connect CtAp_DCChrMgmt.RTE_P_DCChrMgmt_BSTChrgPrmErr_Enum -> CtAp_DCComM.RTE_R_DCChrMgmt_BSTChrgPrmErr_Enum
    connect CtAp_DCChrMgmt.RTE_P_DCChrMgmt_BEMRxCRMPrepdTmt_Bus -> CtAp_DCComM.RTE_R_DCChrMgmt_BEMRxCRMPrepdTmt_Bus
    connect CtAp_DCChrMgmt.RTE_P_DCChrMgmt_BEMRxCROPrepdTmt_Bus -> CtAp_DCComM.RTE_R_DCChrMgmt_BEMRxCROPrepdTmt_Bus
    connect CtAp_DCChrMgmt.RTE_P_DCChrMgmt_BSTIDcErrSts_Enum -> CtAp_DCComM.RTE_R_DCChrMgmt_BSTIDcErrSts_Enum
    connect CtAp_DCChrMgmt.RTE_P_DCChrMgmt_BSTUDcErrSts_Enum -> CtAp_DCComM.RTE_R_DCChrMgmt_BSTUDcErrSts_Enum
    delegate CtAp_DCComM.CEM_BatteryChargeRequireTimeout <-> outer port CEM_BatteryChargeRequireTimeout
    delegate CtAp_DCComM.CST_AbortAchiveCondition <-> outer port CST_AbortAchiveCondition
    connect CtAp_DCChrMgmt.RTE_P_DCChrMgmt_BSMBattTempHiErrSts_Enum -> CtAp_DCComM.RTE_R_DCChrMgmt_BSMBattTempHiErrSts_Enum
    connect CtAp_DCChrMgmt.RTE_P_DCChrMgmt_BSTChkCC2UDcErr_Enum -> CtAp_DCComM.RTE_R_DCChrMgmt_BSTChkCC2UDcErr_Enum
    connect CtAp_DCChrMgmt.RTE_P_DCChrMgmt_BSTChrgrStopSts_Enum -> CtAp_DCComM.RTE_R_DCChrMgmt_BSTChrgrStopSts_Enum
    connect CtAp_DCChrMgmt.RTE_P_DCChrMgmt_BSTIRErrStopSts_Enum -> CtAp_DCComM.RTE_R_DCChrMgmt_BSTIRErrStopSts_Enum
    connect CtAp_DCChrMgmt.RTE_P_DCChrMgmt_DcChrgnIDcReq_A -> CtAp_DCComM.RTE_R_DCChrMgmt_DcChrgnIDcReq_A
    delegate CtAp_DCComM.CRM_RecognitionResult <-> outer port CRM_RecognitionResult
    connect CtAp_DCChrMgmt.RTE_P_DCChrMgmt_BSMIRErrSts_Enum -> CtAp_DCComM.RTE_R_DCChrMgmt_BSMIRErrSts_Enum
    connect CtAp_DCChrMgmt.RTE_P_DCChrMgmt_BSTBMSCnctOvrTemp_Enum -> CtAp_DCComM.RTE_R_DCChrMgmt_BSTBMSCnctOvrTemp_Enum
    connect CtAp_DCChrMgmt.RTE_P_DCChrMgmt_BSTBattOvrTempErr_Enum -> CtAp_DCComM.RTE_R_DCChrMgmt_BSTBattOvrTempErr_Enum
    connect CtAp_DCChrMgmt.RTE_P_DCChrMgmt_BSTOtherErr_Enum -> CtAp_DCComM.RTE_R_DCChrMgmt_BSTOtherErr_Enum
    connect CtAp_DCChrMgmt.RTE_P_DCChrMgmt_DCChrgnUDcReq_V -> CtAp_DCComM.RTE_R_DCChrMgmt_DCChrgnUDcReq_V
    connect CtAp_DCChrMgmt.RTE_P_DCChrMgmt_DcChrgnMod_Enum -> CtAp_DCComM.RTE_R_DCChrMgmt_DcChrgnMod_Enum
    connect CtAp_DCChrMgmt.RTE_P_DCChrMgmt_BSTRchTarTotUDc_Enum -> CtAp_DCComM.RTE_R_DCChrMgmt_BSTRchTarTotUDc_Enum
    connect CtAp_ChrMgmt.RTE_P_ChrMgmt_VCUCalcdPODIDc_A -> CtAp_DCComM.RTE_R_ChrMgmt_VCUCalcdPODIDc_A
    connect CtAp_DCChrMgmt.RTE_P_DCChrMgmt_BROPrepFinshd_Enum -> CtAp_DCComM.RTE_R_DCChrMgmt_BROPrepFinshd_Enum
    connect CtAp_DCChrMgmt.RTE_P_DCChrMgmt_BSMChrgAllwbl_Flg -> CtAp_DCComM.RTE_R_DCChrMgmt_BSMChrgAllwbl_Flg
    connect CtAp_DCChrMgmt.RTE_P_DCChrMgmt_BSMChrgnIDcErrSts_Enum -> CtAp_DCComM.RTE_R_DCChrMgmt_BSMChrgnIDcErrSts_Enum
    delegate CtAp_DCComM.CCS_OutputVoltage <-> outer port CCS_OutputVoltage
    connect CtAp_DCChrMgmt.RTE_P_DCChrMgmt_BEMRxCCSTmt_Bus -> CtAp_DCComM.RTE_R_DCChrMgmt_BEMRxCCSTmt_Bus
    connect CtAp_DCChrMgmt.RTE_P_DCChrMgmt_BEMRxCMLTmt_Bus -> CtAp_DCComM.RTE_R_DCChrMgmt_BEMRxCMLTmt_Bus
    connect CtAp_DCChrMgmt.RTE_P_DCChrMgmt_BEMRxCRMTmt_Bus -> CtAp_DCComM.RTE_R_DCChrMgmt_BEMRxCRMTmt_Bus
    connect CtAp_DCChrMgmt.RTE_P_DCChrMgmt_BEMRxCROTmt_Bus -> CtAp_DCComM.RTE_R_DCChrMgmt_BEMRxCROTmt_Bus
    connect CtAp_DCChrMgmt.RTE_P_DCChrMgmt_BEMRxCSDTmt_Bus -> CtAp_DCComM.RTE_R_DCChrMgmt_BEMRxCSDTmt_Bus
    connect CtAp_DCChrMgmt.RTE_P_DCChrMgmt_BEMRxCSTTmt_Bus -> CtAp_DCComM.RTE_R_DCChrMgmt_BEMRxCSTTmt_Bus
    connect CtAp_DCChrMgmt.RTE_P_DCChrMgmt_BSTHvRlyErrSts_Enum -> CtAp_DCComM.RTE_R_DCChrMgmt_BSTHvRlyErrSts_Enum
    delegate CtAp_DCComM.CHM_ProtocolVersion <-> outer port CHM_ProtocolVersion
    delegate CtAp_DCComM.CML_OutputCurrentMin <-> outer port CML_OutputCurrentMin
    delegate CtAp_DCComM.CML_OutputVoltageMin <-> outer port CML_OutputVoltageMin
    delegate CtAp_DCComM.CML_OutpuVoltageMax <-> outer port CML_OutpuVoltageMax
    delegate CtAp_DCComM.CSD_ChargerNo <-> outer port CSD_ChargerNo
    connect CtAp_DCChrMgmt.RTE_P_DCChrMgmt_BSMCellUDcErrSts_Enum -> CtAp_DCComM.RTE_R_DCChrMgmt_BSMCellUDcErrSts_Enum
    connect CtAp_DCChrMgmt.RTE_P_DCChrMgmt_BSMOutpCnctErrSts_Enum -> CtAp_DCComM.RTE_R_DCChrMgmt_BSMOutpCnctErrSts_Enum
    connect CtAp_DCChrMgmt.RTE_P_DCChrMgmt_BSTRchTarCellUDc_Enum -> CtAp_DCComM.RTE_R_DCChrMgmt_BSTRchTarCellUDc_Enum
    connect CtAp_DCChrMgmt.RTE_P_DCChrMgmt_TxSts_Flg -> CtAp_DCComM.RTE_R_DCChrMgmt_TxSts_Flg
    connect CtAp_DCChrMgmt.RTE_P_DCChrMgmt_BSMSOCErrSts_Enum -> CtAp_DCComM.RTE_R_DCChrMgmt_BSMSOCErrSts_Enum
    connect CtAp_DCChrMgmt.RTE_P_DCChrMgmt_BSTOutpCnctOvrTemp_Enum -> CtAp_DCComM.RTE_R_DCChrMgmt_BSTOutpCnctOvrTemp_Enum
    connect CtAp_DCChrMgmt.RTE_P_DCChrMgmt_BSTRchTarSOC_Enum -> CtAp_DCComM.RTE_R_DCChrMgmt_BSTRchTarSOC_Enum
    delegate CtAp_DCComM.BST_AbortErrorVoltage <-> outer port BST_AbortErrorVoltage
    connect CtAp_DCComM.RTE_P_ComM_CMLMinOutpIDc_A -> CtAp_DCChrMgmt.RTE_R_ComM_CMLMinOutpIDc_A
    connect CtAp_DCComM.RTE_P_ComM_CRMRecgRes_Enum -> CtAp_DCChrMgmt.RTE_R_ComM_CRMRecgRes_Enum
    connect CtAp_DCComM.RTE_P_ComM_CMLMaxOutpUDc_V -> CtAp_DCChrMgmt.RTE_R_ComM_CMLMaxOutpUDc_V
    connect CtAp_DCComM.RTE_P_ComM_CMLMinOutpUDc_V -> CtAp_DCChrMgmt.RTE_R_ComM_CMLMinOutpUDc_V
    connect CtAp_DCComM.RTE_P_ComM_RxSts_Flg -> CtAp_DCChrMgmt.RTE_R_ComM_RxSts_Flg
    connect CtAp_DCComM.RTE_P_ComM_CROPrepRdy_Enum -> CtAp_DCChrMgmt.RTE_R_ComM_CROPrepRdy_Enum
    connect CtAp_DCComM.RTE_P_ComM_CMLMaxOutpIDc_A -> CtAp_DCChrMgmt.RTE_R_ComM_CMLMaxOutpIDc_A
    connect YDF_ErrorHandler.PTCAN_BusoffStatus -> CtAp_ComMErr.PTCAN_BusoffStatus
    connect YDF_ErrorHandler.CHCAN_BusoffStatus -> CtAp_ComMErr.CHCAN_BusoffStatus
    connect YDF_ErrorHandler.BSW_FuSaHWErrorStatus -> CtAp_ErrMgmt.BSW_FuSaHWErrorStatus
    connect CtAp_ChassisMgmt.RTE_P_ChassisMgmt_IBSDesIncTq_Nm -> CtAp_TorqPahMgmt.RTE_R_ChassisMgmt_IBSDesIncTq_Nm
    connect CtAp_CANHandler.RTE_P_ComM_MCU01MsgErrInfo_Bus -> CtAp_TorqPahMgmt.RTE_R_ComM_MCU01MsgErrInfo_Bus
    connect CtAp_DCComM.RTE_P_ComM_CMLMaxOutpIDc_A -> CtAp_ChrMgmt.RTE_R_ComM_CMLMaxOutpIDc_A
    connect YDF_ErrorHandler.UDS_PwrCutRequest -> CtAp_HvMgmt.UDS_PwrCutRequest
    connect CtAp_LINHandler.RTE_P_ComM_BSBattSOC_pct -> CtAp_HvMgmt.RTE_R_ComM_BSBattSOC_pct
    connect CtAp_LINHandler.RTE_P_ComM_BSBattSOC_pct -> CtAp_LvMgmt
    connect CtAp_ComMErr.RTE_P_ComM_NodComFailr -> CtAp_LvMgmt.RTE_R_ComM_NodComFailr
    delegate CtAp_CANHandler.CCS_OutputCurrent <-> outer port CCS_OutputCurrent
    connect CtAp_ChassisMgmt.RTE_P_ChassisMgmt_OnePedlCtrlReqStdlSts_Flg -> CtAp_CANHandler.RTE_R_ChassisMgmt_OnePedlCtrlReqStdlSts_Flg
    connect CtAp_VehMot.RTE_P_VehMot_VehStdl_Flg -> CtAp_RngEstimn.RTE_R_VehMot_VehStdl_Flg
    connect YDF_NMHandler.IF_ComM_CGWPNC15 -> CtAp_LvMgmt.RTE_R_ComM_CGWPNC15
    connect YDF_NMHandler.IF_ComM_BMSPNC15 -> CtAp_LvMgmt.RTE_R_ComM_BMSPNC15
    connect YDF_WakeUp_Swc.Ecu_LinWakeStatus -> CtAp_LvMgmt.RTE_R_Ecu_LinWakeStatus
    connect YDF_WakeUp_Swc.Ecu_KeyWakeStatus -> CtAp_LvMgmt.RTE_R_Ecu_KeyWakeStatus
    connect YDF_WakeUp_Swc.Ecu_AccWakeStatus -> CtAp_LvMgmt.RTE_R_Ecu_AccWakeStatus
    connect YDF_WakeUp_Swc.Ecu_CHCANWakeStatus -> CtAp_LvMgmt.RTE_R_Ecu_CHCANWakeStatus
    connect YDF_WakeUp_Swc.Ecu_PTCANWakeStatus -> CtAp_LvMgmt.RTE_R_Ecu_PTCANWakeStatus
    connect YDF_NMHandler.NM_BMSAWB -> CtAp_LvMgmt.RTE_R_ComM_BMSAWB
    connect YDF_NMHandler.NM_CGWAWB -> CtAp_LvMgmt.RTE_R_ComM_CGWAWB
    connect CtAp_LvMgmt.RTE_P_LvMgmt_BSBattUDcNorm_Flg -> CtAp_LINHandler.RTE_R_LvMgmt_BSBattUDcNorm_Flg
    connect CtAp_LINHandler.RTE_P_ComM_BSBatVltHlResInfo -> CtAp_CANHandler.RTE_R_ComM_BSBatVltHlResInfo
    connect CtAp_VehMot.RTE_P_VehMot_Acclr2Tq_Nm -> CtAp_ChassisMgmt.RTE_R_VehMot_Acclr2Tq_Nm
    connect CtAp_LINHandler.RTE_P_ComM_BSBattSOC_pct -> CtAp_CANHandler.RTE_R_ComM_BSBattSOC_pct
    connect YDF_NVMgmt.RTE_RP_ModMgmtInfo -> CtAp_ModMgmt.RTE_RP_ModMgmtInfo
    connect YDF_NVMgmt.RTE_RP_ChrgEgyCalInfo -> CtAp_ChrMgmt.RTE_RP_ChrgEgyCalInfo
    connect YDF_NVMgmt.RTE_RP_ChrgStatInfo -> CtAp_ChrMgmt.RTE_RP_ChrgStatInfo
    delegate CtAp_DCComM.CML_OutputCurrentMax <-> outer port CML_OutputCurrentMax
    delegate CtAp_DCComM.BCL_CurrentRequire <-> outer port BCL_CurrentRequire
    connect CtAp_TorqPahMgmt.RTE_P_TorqPahMgmt_WhlActTq_Nm -> CtAp_VehMot.RTE_R_TorqPahMgmt_WhlActTq_Nm
    connect CtAp_ChassisMgmt.RTE_P_ChassisMgmt_VehStbCtrlTqAvl_Flg -> CtAp_CANHandler.RTE_R_ChassisMgmt_VehStbCtrlTqAvl_Flg
    connect CtAp_CANHandler.RTE_P_ComM_IBSSts04MsgErrInfo_Bus -> CtAp_ChassisMgmt.RTE_R_ComM_IBSSts04MsgErrInfo_Bus
    connect YDF_ErrorHandler.UDS_PwrCutRequest -> CtAp_ChrMgmt.UDS_PwrCutRequest
    connect CtAp_ChassisMgmt.RTE_P_ChassisMgmt_IBSIntvTqActv -> CtAp_CANHandler.RTE_R_ChassisMgmt_IBSIntvTqActv
    connect CtAp_LvMgmt.RTE_P_LvMgmt_BSBattUDcNorm_Flg -> CtAp_ComMErr.RTE_R_LvMgmt_BSBattUDcNorm_Flg
    delegate CtAp_DCComM.BCL_VolltageRequire <-> outer port BCL_VolltageRequire
    delegate CtAp_DCComM.BEM_ChargeAbortTimeout <-> outer port BEM_ChargeAbortTimeout
    delegate CtAp_DCComM.BEM_ChargeFinishTimeout <-> outer port BEM_ChargeFinishTimeout
    delegate CtAp_DCComM.BEM_ChargerIdTimeout0 <-> outer port BEM_ChargerIdTimeout0
    delegate CtAp_DCComM.BEM_ChargerIdTimeout1 <-> outer port BEM_ChargerIdTimeout1
    delegate CtAp_DCComM.BEM_ChargeStateTimeout <-> outer port BEM_ChargeStateTimeout
    delegate CtAp_DCComM.BEM_ChargeStatisticsTimeout <-> outer port BEM_ChargeStatisticsTimeout
    delegate CtAp_DCComM.BEM_TimesyncOrPowerTimeout <-> outer port BEM_TimesyncOrPowerTimeout
    delegate CtAp_DCComM.BHM_AllowChargeVoltageMax <-> outer port BHM_AllowChargeVoltageMax
    delegate CtAp_DCComM.BRO_BMSChargeReady <-> outer port BRO_BMSChargeReady
    delegate CtAp_DCComM.BSM_BatteryCurrentState <-> outer port BSM_BatteryCurrentState
    delegate CtAp_DCComM.BSM_BatteryOutpuConnectorState <-> outer port BSM_BatteryOutpuConnectorState
    delegate CtAp_DCComM.BSM_BatteryTempState <-> outer port BSM_BatteryTempState
    delegate CtAp_DCComM.BSM_BatteryVoltageState <-> outer port BSM_BatteryVoltageState
    delegate CtAp_DCComM.BSM_ChargeEnable <-> outer port BSM_ChargeEnable
    delegate CtAp_DCComM.BSM_InsulationState <-> outer port BSM_InsulationState
    delegate CtAp_DCComM.BSM_SOC <-> outer port BSM_SOC
    delegate CtAp_DCComM.BST_AbortAchiveSingleVolt <-> outer port BST_AbortAchiveSingleVolt
    delegate CtAp_DCComM.BST_AbortAchiveSOC <-> outer port BST_AbortAchiveSOC
    delegate CtAp_DCComM.BST_AbortAchiveTotalVolt <-> outer port BST_AbortAchiveTotalVolt
    delegate CtAp_DCComM.BST_Abortdet2Voltexception <-> outer port BST_Abortdet2Voltexception
    delegate CtAp_DCComM.BST_AbortErrorCurrent <-> outer port BST_AbortErrorCurrent
    delegate CtAp_DCComM.BST_AbortFaultBatteryTemp <-> outer port BST_AbortFaultBatteryTemp
    delegate CtAp_DCComM.BST_AbortFaultBMSTemp <-> outer port BST_AbortFaultBMSTemp
    delegate CtAp_DCComM.BST_AbortFaultConnector <-> outer port BST_AbortFaultConnector
    delegate CtAp_DCComM.BST_AbortFaultConnectorTemp <-> outer port BST_AbortFaultConnectorTemp
    delegate CtAp_DCComM.BST_AbortFaultInsulation <-> outer port BST_AbortFaultInsulation
    delegate CtAp_DCComM.BST_AbortFaultOther <-> outer port BST_AbortFaultOther
    delegate CtAp_DCComM.BST_AbortHVrelayfault <-> outer port BST_AbortHVrelayfault
    delegate CtAp_DCComM.BST_Abortmanoperate <-> outer port BST_Abortmanoperate
    delegate CtAp_DCComM.BCL_ChargeMode <-> outer port BCL_ChargeMode
    connect CtAp_ComMErr.RTE_P_ComM_CANBusOffInfo_Bus -> CtAp_LvMgmt.RTE_R_ComM_CANBusOffInfo_Bus
    connect CtAp_ComMErr.RTE_P_ComM_NodComFailr -> CtAp_VehMot.RTE_R_ComM_NodComFailr
    connect CtAp_CANHandler.RTE_P_ComM_CGWVehStatusInfo -> CtAp_DiagnosisApp.RTE_R_ComM_CGWVehStatusInfo
    connect CtAp_CANHandler.RTE_P_ComM_IVIOdometerInfo -> CtAp_DiagnosisApp.RTE_R_ComM_IVIOdometerInfo
    connect CtAp_CANHandler.RTE_P_ComM_SGWTimeDayInfo -> CtAp_DiagnosisApp.RTE_R_ComM_SGWTimeDayInfo
    connect CtAp_CANHandler.RTE_P_ComM_SGWTimeHourInfo -> CtAp_DiagnosisApp.RTE_R_ComM_SGWTimeHourInfo
    connect CtAp_CANHandler.RTE_P_ComM_SGWTimeMinuteInfo -> CtAp_DiagnosisApp.RTE_R_ComM_SGWTimeMinuteInfo
    connect CtAp_CANHandler.RTE_P_ComM_SGWTimeMonthInfo -> CtAp_DiagnosisApp.RTE_R_ComM_SGWTimeMonthInfo
    connect CtAp_CANHandler.RTE_P_ComM_SGWTimeSecondInfo -> CtAp_DiagnosisApp.RTE_R_ComM_SGWTimeSecondInfo
    connect CtAp_CANHandler.RTE_P_ComM_SGWTimeYearInfo -> CtAp_DiagnosisApp.RTE_R_ComM_SGWTimeYearInfo
    connect CtAp_DiagnosisApp.RTE_P_DiagApp_SpdLmtInfo -> CtAp_TorqPahMgmt.RTE_R_DiagApp_SpdLmtInfo
    connect CtAp_DiagnosisApp.RTE_P_DiagApp_TireRadiusInfo -> CtAp_VehMot.RTE_R_DiagApp_TireRadiusInfo
    connect CtAp_EgyMgmt.RTE_P_EgyMgmt_MCUPwrCnsCalcn_Kw -> CtAp_DiagnosisApp.RTE_R_EgyMgmt_MCUPwrCnsCalcn_Kw
    connect CtAp_EgyMgmt.RTE_P_EgyMgmt_V2LPwrCnsCalcn_Kw -> CtAp_DiagnosisApp.RTE_R_EgyMgmt_V2LPwrCnsCalcn_Kw
    connect CtAp_ErrMgmt.RTE_P_ErrMgmt_DlyHvDwn_Flg -> CtAp_DiagnosisApp.RTE_R_ErrMgmt_DlyHvDwn_Flg
    connect CtAp_ErrMgmt.RTE_P_ErrMgmt_HvNormDwn_Flg -> CtAp_DiagnosisApp.RTE_R_ErrMgmt_HvNormDwn_Flg
    connect CtAp_VehMot.RTE_P_VotMot_TireRadiusReadInfo -> CtAp_DiagnosisApp.RTE_R_VotMot_TireRadiusReadInfo
    connect CtAp_ChassisMgmt.RTE_P_ChassisMgmt_AccrPedlURaw1HiDTC_Bus -> YDF_ErrorHandler.RTE_R_ChassisMgmt_AccrPedlURaw1HiDTC_Bus
    connect CtAp_ChassisMgmt.RTE_P_ChassisMgmt_AccrPedlURaw1LoDTC_Bus -> YDF_ErrorHandler.RTE_R_ChassisMgmt_AccrPedlURaw1LoDTC_Bus
    connect CtAp_ChassisMgmt.RTE_P_ChassisMgmt_AccrPedlURaw2HiDTC_Bus -> YDF_ErrorHandler.RTE_R_ChassisMgmt_AccrPedlURaw2HiDTC_Bus
    connect CtAp_ChassisMgmt.RTE_P_ChassisMgmt_AccrPedlURaw2LoDTC_Bus -> YDF_ErrorHandler.RTE_R_ChassisMgmt_AccrPedlURaw2LoDTC_Bus
    connect CtAp_ChassisMgmt.RTE_P_ChassisMgmt_AccrPedlURawDifDTC_Bus -> YDF_ErrorHandler.RTE_R_ChassisMgmt_AccrPedlURawDifDTC_Bus
    connect CtAp_ChassisMgmt.RTE_P_ChassisMgmt_IBSApsCtrlDesTqOverFltDTCInfo_Bus -> YDF_ErrorHandler.RTE_R_ChassisMgmt_IBSApsCtrlDesTqOverFltDTCInfo_Bus
    connect CtAp_ChassisMgmt.RTE_P_ChassisMgmt_IBSRbsDesTqOverFltDTCInfo_Bus -> YDF_ErrorHandler.RTE_R_ChassisMgmt_IBSRbsDesTqOverFltDTCInfo_Bus
    connect CtAp_ChassisMgmt.RTE_P_ChassisMgmt_IBSVlcCtrlDesTqOverFltDTCInfo_Bus -> YDF_ErrorHandler.RTE_R_ChassisMgmt_IBSVlcCtrlDesTqOverFltDTCInfo_Bus
    connect CtAp_ChrMgmt.RTE_P_ChrMgmt_AcPreheatUDcCtrlErrDTC_Bus -> YDF_ErrorHandler.RTE_R_ChrMgmt_AcPreheatUDcCtrlErrDTC_Bus
    connect CtAp_ChrMgmt.RTE_P_ChrMgmt_ChrgStsJmpDTC_Bus -> YDF_ErrorHandler.RTE_R_ChrMgmt_ChrgStsJmpDTC_Bus
    connect CtAp_ChrMgmt.RTE_P_ChrMgmt_DcPreheatUDcCtrlErrDTC_Bus -> YDF_ErrorHandler.RTE_R_ChrMgmt_DcPreheatUDcCtrlErrDTC_Bus
    connect CtAp_ChrMgmt.RTE_P_ChrMgmt_PreheatIRChkErrDTC_Bus -> YDF_ErrorHandler.RTE_R_ChrMgmt_PreheatIRChkErrDTC_Bus
    connect CtAp_ComMErr.RTE_P_ComM_ComDTCFailr -> YDF_ErrorHandler.RTE_R_ComM_ComDTCFailr
    connect CtAp_DCChrMgmt.RTE_P_DCChrMgmt_BEMRxCCSTmtDTC_Bus -> YDF_ErrorHandler.RTE_R_DCChrMgmt_BEMRxCCSTmtDTC_Bus
    connect CtAp_DCChrMgmt.RTE_P_DCChrMgmt_BEMRxCMLTmtDTC_Bus -> YDF_ErrorHandler.RTE_R_DCChrMgmt_BEMRxCMLTmtDTC_Bus
    connect CtAp_DCChrMgmt.RTE_P_DCChrMgmt_BEMRxCRMPrepdTmtDTC_Bus -> YDF_ErrorHandler.RTE_R_DCChrMgmt_BEMRxCRMPrepdTmtDTC_Bus
    connect CtAp_DCChrMgmt.RTE_P_DCChrMgmt_BEMRxCRMTmtDTC_Bus -> YDF_ErrorHandler.RTE_R_DCChrMgmt_BEMRxCRMTmtDTC_Bus
    connect CtAp_DCChrMgmt.RTE_P_DCChrMgmt_BEMRxCROPrepdTmtDTC_Bus -> YDF_ErrorHandler.RTE_R_DCChrMgmt_BEMRxCROPrepdTmtDTC_Bus
    connect CtAp_DCChrMgmt.RTE_P_DCChrMgmt_BEMRxCROTmtDTC_Bus -> YDF_ErrorHandler.RTE_R_DCChrMgmt_BEMRxCROTmtDTC_Bus
    connect CtAp_DCChrMgmt.RTE_P_DCChrMgmt_BEMRxCSDTmtDTC_Bus -> YDF_ErrorHandler.RTE_R_DCChrMgmt_BEMRxCSDTmtDTC_Bus
    connect CtAp_DCChrMgmt.RTE_P_DCChrMgmt_BEMRxCSTTmtDTC_Bus -> YDF_ErrorHandler.RTE_R_DCChrMgmt_BEMRxCSTTmtDTC_Bus
    connect CtAp_DCChrMgmt.RTE_P_DCChrMgmt_DcPortTempErrLvl1DTC_Bus -> YDF_ErrorHandler.RTE_R_DCChrMgmt_DcPortTempErrLvl1DTC_Bus
    connect CtAp_DCChrMgmt.RTE_P_DCChrMgmt_DcPortTempSnsrErrDTC_Bus -> YDF_ErrorHandler.RTE_R_DCChrMgmt_DcPortTempSnsrErrDTC_Bus
    connect CtAp_DCChrMgmt.RTE_P_DCChrMgmt_DcPortTempErrLvl2DTC_Bus -> YDF_ErrorHandler.RTE_R_DCChrMgmt_DcPortTempErrLvl2DTC_Bus
    connect CtAp_DCChrMgmt.RTE_P_DCChrMgmt_IRMeasDiErrDTC_Bus -> YDF_ErrorHandler.RTE_R_DCChrMgmt_IRMeasDiErrDTC_Bus
    connect CtAp_DCChrMgmt.RTE_P_DCChrMgmt_IRMeasEnaErrDTC_Bus -> YDF_ErrorHandler.RTE_R_DCChrMgmt_IRMeasEnaErrDTC_Bus
    connect CtAp_ErrMgmt.RTE_P_ErrMgmt_VCUHVILDTC_Bus -> YDF_ErrorHandler.RTE_R_ErrMgmt_VCUHVILDTC_Bus
    connect CtAp_FctSftyMon.RTE_P_FctSftyMon_AccrPedlTqOverFltDTCInfo_Bus -> YDF_ErrorHandler.RTE_R_FctSftyMon_AccrPedlTqOverFltDTCInfo_Bus
    connect CtAp_FctSftyMon.RTE_P_FctSftyMon_CrpCtrlTqOverFltDTCInfo_Bus -> YDF_ErrorHandler.RTE_R_FctSftyMon_CrpCtrlTqOverFltDTCInfo_Bus
    connect CtAp_FctSftyMon.RTE_P_FctSftyMon_DesVehDecelSpdOverFltDTCInfo_Bus -> YDF_ErrorHandler.RTE_R_FctSftyMon_DesVehDecelSpdOverFltDTCInfo_Bus
    connect CtAp_HvMgmt.RTE_P_HvMgmt_BMSClsDTC_Bus -> YDF_ErrorHandler.RTE_R_HvMgmt_BMSRlyClsDTC_Bus
    connect CtAp_HvMgmt.RTE_P_HvMgmt_BMSOpenDTC_Bus -> YDF_ErrorHandler.RTE_R_HvMgmt_BMSRlyOpenDTC_Bus
    connect CtAp_HvMgmt.RTE_P_HvMgmt_DCDCEnaFltDTC_Bus -> YDF_ErrorHandler.RTE_R_HvMgmt_DCDCEnaFltDTC_Bus
    connect CtAp_HvMgmt.RTE_P_HvMgmt_DCDCStopFltDTC_Bus -> YDF_ErrorHandler.RTE_R_HvMgmt_DCDCStopFltDTC_Bus
    connect CtAp_HvMgmt.RTE_P_HvMgmt_DCFCRlyClsDTC_Bus -> YDF_ErrorHandler.RTE_R_HvMgmt_DCFCRlyClsDTC_Bus
    connect CtAp_HvMgmt.RTE_P_HvMgmt_MCUClsFltDTC_Bus -> YDF_ErrorHandler.RTE_R_HvMgmt_MCUClsFltDTC_Bus
    connect CtAp_HvMgmt.RTE_P_HvMgmt_MCUEnaFltDTC_Bus -> YDF_ErrorHandler.RTE_R_HvMgmt_MCUEnaFltDTC_Bus
    connect CtAp_HvMgmt.RTE_P_HvMgmt_MCURdyFltDTC_Bus -> YDF_ErrorHandler.RTE_R_HvMgmt_MCURdyFltDTC_Bus
    connect CtAp_HvMgmt.RTE_P_HvMgmt_PreheatPosRlyClsDTC_Bus -> YDF_ErrorHandler.RTE_R_HvMgmt_PreheatPosRlyClsDTC_Bus
    connect CtAp_HvMgmt.RTE_P_HvMgmt_PreheatPosRlyOpenDTC_Bus -> YDF_ErrorHandler.RTE_R_HvMgmt_PreheatPosRlyOpenDTC_Bus
    connect CtAp_HvMgmt.RTE_P_HvMgmt_TCUEnaFltDTC_Bus -> YDF_ErrorHandler.RTE_R_HvMgmt_TCUEnaFltDTC_Bus
    connect CtAp_HvMgmt.RTE_P_HvMgmt_TCUStopFltDTC_Bus -> YDF_ErrorHandler.RTE_R_HvMgmt_TCUStopFltDTC_Bus
    connect CtAp_LINHandler.RTE_P_ComM_LinMsgErrInfo_Bus -> YDF_ErrorHandler.RTE_R_ComM_LinMsgErrInfo_Bus
    connect CtAp_LvMgmt.RTE_P_LvMgmt_BSBattIDcHiDTC_Bus -> YDF_ErrorHandler.RTE_R_LvMgmt_BSBattIDcHiDTC_Bus
    connect CtAp_LvMgmt.RTE_P_LvMgmt_BSBattUDcHiDTC_Bus -> YDF_ErrorHandler.RTE_R_LvMgmt_BSBattUDcHiDTC_Bus
    connect CtAp_LvMgmt.RTE_P_LvMgmt_BSBattUDcLoDTC_Bus -> YDF_ErrorHandler.RTE_R_LvMgmt_BSBattUDcLoDTC_Bus
    connect CtAp_LvMgmt.RTE_P_LvMgmt_ECUsDiagDTC_Bus -> YDF_ErrorHandler.RTE_R_LvMgmt_ECUsDiagDTC_Bus
    connect CtAp_LvMgmt.RTE_P_LvMgmt_KL15eOffDTC_Bus -> YDF_ErrorHandler.RTE_R_LvMgmt_KL15eOffDTC_Bus
    connect CtAp_LvMgmt.RTE_P_LvMgmt_KL15eOnDTC_Bus -> YDF_ErrorHandler.RTE_R_LvMgmt_KL15eOnDTC_Bus
    connect CtAp_LvMgmt.RTE_P_LvMgmt_LvSysLoUdcDTC_Bus -> YDF_ErrorHandler.RTE_R_LvMgmt_LvSysLoUdcDTC_Bus
    connect CtAp_LvMgmt.RTE_P_LvMgmt_LvSysOvrUdcDTC_Bus -> YDF_ErrorHandler.RTE_R_LvMgmt_LvSysOvrUdcDTC_Bus
    connect CtAp_OBCMgmt.RTE_P_OBCMgmt_CPStsJmpErrDTC_Bus -> YDF_ErrorHandler.RTE_R_OBCMgmt_CPStsJmpErrDTC_Bus
    connect CtAp_OBCMgmt.RTE_P_OBCMgmt_ElectcLockOpenErrDTC_Bus -> YDF_ErrorHandler.RTE_R_OBCMgmt_ElectcLockOpenErrDTC_Bus
    connect CtAp_OBCMgmt.RTE_P_OBCMgmt_ElectcLockClsErrDTC_Bus -> YDF_ErrorHandler.RTE_R_OBCMgmt_ElectcLockClsErrDTC_Bus
    connect CtAp_OBCMgmt.RTE_P_OBCMgmt_OBCChrgStsErrDTC_Bus -> YDF_ErrorHandler.RTE_R_OBCMgmt_OBCChrgStsErrDTC_Bus
    connect CtAp_OBCMgmt.RTE_P_OBCMgmt_OBCDchaStsErrDTC_Bus -> YDF_ErrorHandler.RTE_R_OBCMgmt_OBCDchaStsErrDTC_Bus
    connect CtAp_OBCMgmt.RTE_P_OBCMgmt_OBCDiErrDTC_Bus -> YDF_ErrorHandler.RTE_R_OBCMgmt_OBCDiErrDTC_Bus
    connect CtAp_OBCMgmt.RTE_P_OBCMgmt_OBCInpUDcLoErrDTC_Bus -> YDF_ErrorHandler.RTE_R_OBCMgmt_OBCInpUDcLoErrDTC_Bus
    connect CtAp_OBCMgmt.RTE_P_OBCMgmt_OBCPreheatStsErrDTC_Bus -> YDF_ErrorHandler.RTE_R_OBCMgmt_OBCPreheatStsErrDTC_Bus
    connect CtAp_OBCMgmt.RTE_P_OBCMgmt_S2SwtClsErrDTC_Bus -> YDF_ErrorHandler.RTE_R_OBCMgmt_S2SwtClsErrDTC_Bus
    connect CtAp_OBCMgmt.RTE_P_OBCMgmt_S2SwtOpenErrDTC_Bus -> YDF_ErrorHandler.RTE_R_OBCMgmt_S2SwtOpenErrDTC_Bus
    connect CtAp_ChassisMgmt.RTE_P_ChassisMgmt_RgnTqCap_Nm -> CtAp_DiagnosisApp.RTE_R_ChassisMgmt_RgnTqCap_Nm
    connect CtAp_ChassisMgmt.RTE_P_ChassisMgmt_AccrPedlPosn_pct -> CtAp_DiagnosisApp.RTE_R_ChassisMgmt_AccrPedlPosn_pct
    connect CtAp_ChrMgmt.RTE_P_ChrMgmt_ChrgSts_Enum -> CtAp_DiagnosisApp.RTE_R_ChrMgmt_ChrgSts_Enum
    connect CtAp_CANHandler.RTE_P_ComM_BMSBattDchaIDc_A -> CtAp_DiagnosisApp.RTE_R_ComM_BMSBattDchaIDc_A
    connect CtAp_CANHandler.RTE_P_ComM_BMSBattDispSOC_pct -> CtAp_DiagnosisApp.RTE_R_ComM_BMSBattDispSOC_pct
    connect CtAp_CANHandler.RTE_P_ComM_BMSBattFbIDc_A -> CtAp_DiagnosisApp.RTE_R_ComM_BMSBattFbIDc_A
    connect CtAp_CANHandler.RTE_P_ComM_BMSBattPckUDc_V -> CtAp_DiagnosisApp.RTE_R_ComM_BMSBattPckUDc_V
    connect CtAp_CANHandler.RTE_P_ComM_BMSNegRlySts_Enum -> CtAp_DiagnosisApp.RTE_R_ComM_BMSNegRlySts_Enum
    connect CtAp_CANHandler.RTE_P_ComM_BMSPosRlySts_Enum -> CtAp_DiagnosisApp.RTE_R_ComM_BMSPosRlySts_Enum
    connect CtAp_CANHandler.RTE_P_ComM_BMSWrkMod_Enum -> CtAp_DiagnosisApp.RTE_R_ComM_BMSWrkMod_Enum
    connect CtAp_LINHandler.RTE_P_ComM_BSBatVltHlResInfo -> CtAp_DiagnosisApp.RTE_R_ComM_BSBatVltHlResInfo
    connect CtAp_CANHandler.RTE_P_ComM_DCDCWrkMod_Enum -> CtAp_DiagnosisApp.RTE_R_ComM_DCDCWrkMod_Enum
    connect CtAp_CANHandler.RTE_P_ComM_DcInletATemp_C -> CtAp_DiagnosisApp.RTE_R_ComM_DcInletATemp_C
    connect CtAp_CANHandler.RTE_P_ComM_DcInletBTemp_C -> CtAp_DiagnosisApp.RTE_R_ComM_DcInletBTemp_C
    connect CtAp_CANHandler.RTE_P_ComM_ElectcLockSts_Enum -> CtAp_DiagnosisApp.RTE_R_ComM_ElectcLockSts_Enum
    connect CtAp_CANHandler.RTE_P_ComM_IBSVehSpd_kph -> CtAp_DiagnosisApp.RTE_R_ComM_IBSVehSpd_kph
    connect CtAp_CANHandler.RTE_P_ComM_MCUWrkMod_Enum -> CtAp_DiagnosisApp.RTE_R_ComM_MCUWrkMod_Enum
    connect CtAp_CANHandler.RTE_P_ComM_OBCCCSts_Enum -> CtAp_DiagnosisApp.RTE_R_ComM_OBCCCSts_Enum
    connect CtAp_CANHandler.RTE_P_ComM_OBCInpUAc_V -> CtAp_DiagnosisApp.RTE_R_ComM_OBCInpUAc_V
    connect CtAp_CANHandler.RTE_P_ComM_OBCOutpIDc_A -> CtAp_DiagnosisApp.RTE_R_ComM_OBCOutpIDc_A
    connect CtAp_CANHandler.RTE_P_ComM_OBCOutpUDc_V -> CtAp_DiagnosisApp.RTE_R_ComM_OBCOutpUDc_V
    connect CtAp_CANHandler.RTE_P_ComM_S2SwtSts_Enum -> CtAp_DiagnosisApp.RTE_R_ComM_S2SwtSts_Enum
    connect CtAp_EgyMgmt.RTE_P_EgyMgmt_ACSysPwrCnsCalcn_Kw -> CtAp_DiagnosisApp.RTE_R_EgyMgmt_ACSysPwrCnsCalcn_Kw
    connect CtAp_EgyMgmt.RTE_P_EgyMgmt_DCDCPwrCnsCalcn_Kw -> CtAp_DiagnosisApp.RTE_R_EgyMgmt_DCDCPwrCnsCalcn_Kw
    connect CtAp_EgyMgmt.RTE_P_EgyMgmt_DCDCPwrLmt_Kw -> CtAp_DiagnosisApp.RTE_R_EgyMgmt_DCDCPwrLmt_Kw
    connect CtAp_EgyMgmt.RTE_P_EgyMgmt_MCUDrvPwrLmt_Kw -> CtAp_DiagnosisApp.RTE_R_EgyMgmt_MCUDrvPwrLmt_Kw
    connect CtAp_EgyMgmt.RTE_P_EgyMgmt_MCUFbPwrLmt_Kw -> CtAp_DiagnosisApp.RTE_R_EgyMgmt_MCUFbPwrLmt_Kw
    connect CtAp_EgyMgmt.RTE_P_EgyMgmt_PackPTCPwrCnsCalcn_Kw -> CtAp_DiagnosisApp.RTE_R_EgyMgmt_PackPTCPwrCnsCalcn_Kw
    connect CtAp_EgyMgmt.RTE_P_EgyMgmt_TCUPwrAllwd_W -> CtAp_DiagnosisApp.RTE_R_EgyMgmt_TCUPwrAllwd_W
    connect CtAp_ErrMgmt.RTE_P_ErrMgmt_AcPause_Flg -> CtAp_DiagnosisApp.RTE_R_ErrMgmt_AcPause_Flg
    connect CtAp_ErrMgmt.RTE_P_ErrMgmt_AcStop_Flg -> CtAp_DiagnosisApp.RTE_R_ErrMgmt_AcStop_Flg
    connect CtAp_ErrMgmt.RTE_P_ErrMgmt_DcPause_Flg -> CtAp_DiagnosisApp.RTE_R_ErrMgmt_DcPause_Flg
    connect CtAp_ErrMgmt.RTE_P_ErrMgmt_DcStop_Flg -> CtAp_DiagnosisApp.RTE_R_ErrMgmt_DcStop_Flg
    connect CtAp_ErrMgmt.RTE_P_ErrMgmt_DlyGrdtZeroTq_Flg -> CtAp_DiagnosisApp.RTE_R_ErrMgmt_DlyGrdtZeroTq_Flg
    connect CtAp_ErrMgmt.RTE_P_ErrMgmt_EmgyHvDwn_Flg -> CtAp_DiagnosisApp.RTE_R_ErrMgmt_EmgyHvDwn_Flg
    connect CtAp_ErrMgmt.RTE_P_ErrMgmt_Fobd2Hv_Flg -> CtAp_DiagnosisApp.RTE_R_ErrMgmt_Fobd2Hv_Flg
    connect CtAp_ErrMgmt.RTE_P_ErrMgmt_FobdEgyRcov_Flg -> CtAp_DiagnosisApp.RTE_R_ErrMgmt_FobdEgyRcov_Flg
    connect CtAp_ErrMgmt.RTE_P_ErrMgmt_GrdtZeroTq_Flg -> CtAp_DiagnosisApp.RTE_R_ErrMgmt_GrdtZeroTq_Flg
    connect CtAp_ErrMgmt.RTE_P_ErrMgmt_HvDwn_Flg -> CtAp_DiagnosisApp.RTE_R_ErrMgmt_HvDwn_Flg
    connect CtAp_ErrMgmt.RTE_P_ErrMgmt_ImdtZeroTq_Flg -> CtAp_DiagnosisApp.RTE_R_ErrMgmt_ImdtZeroTq_Flg
    connect CtAp_ErrMgmt.RTE_P_ErrMgmt_V2LStop_Flg -> CtAp_DiagnosisApp.RTE_R_ErrMgmt_V2LStop_Flg
    connect CtAp_ErrMgmt.RTE_P_ErrMgmt_VehErrLvl_Enum -> CtAp_DiagnosisApp.RTE_R_ErrMgmt_VehErrLvl_Enum
    connect CtAp_ErrMgmt.RTE_P_ErrMgmt_VehSpdLimErrLv5_Flg -> CtAp_DiagnosisApp.RTE_R_ErrMgmt_VehSpdLimErrLv5_Flg
    connect CtAp_ErrMgmt.RTE_P_ErrMgmt_VehSpdLimErrLv6_Flg -> CtAp_DiagnosisApp.RTE_R_ErrMgmt_VehSpdLimErrLv6_Flg
    connect CtAp_HvMgmt.RTE_P_HvMgmt_ReqModBMS_Enum -> CtAp_DiagnosisApp.RTE_R_HvMgmt_ReqModBMS_Enum
    connect CtAp_HWHandler.RTE_P_IOAbs_AccrPedlMaiRaw_mV -> CtAp_DiagnosisApp.RTE_R_IOAbs_AccrPedlMaiRaw_mV
    connect CtAp_HWHandler.RTE_P_IOAbs_AccrPedlRdnRaw_mV -> CtAp_DiagnosisApp.RTE_R_IOAbs_AccrPedlRdnRaw_mV
    connect CtAp_HWHandler.RTE_P_IOAbs_BSBattUDc_V -> CtAp_DiagnosisApp.RTE_R_IOAbs_BSBattUDc_V
    connect CtAp_HWHandler.RTE_P_IOAbs_HVILPwmFrq_Hz -> CtAp_DiagnosisApp.RTE_R_IOAbs_HVILPwmFrq_Hz
    connect CtAp_ModMgmt.RTE_P_ModMgmt_ActDrvMod_Enum -> CtAp_DiagnosisApp.RTE_R_ModMgmt_ActDrvMod_Enum
    connect CtAp_ModMgmt.RTE_P_ModMgmt_HvSts_Enum -> CtAp_DiagnosisApp.RTE_R_ModMgmt_HvSts_Enum
    connect CtAp_OBCMgmt.RTE_P_OBCMgmt_ElectcLockCtrlCmd_Enum -> CtAp_DiagnosisApp.RTE_R_OBCMgmt_ElectcLockCtrlCmd_Enum
    connect CtAp_OBCMgmt.RTE_P_OBCMgmt_ReqOBCIDc_A -> CtAp_DiagnosisApp.RTE_R_OBCMgmt_ReqOBCIDc_A
    connect CtAp_OBCMgmt.RTE_P_OBCMgmt_S2SwtCtrlCmd_Enum -> CtAp_DiagnosisApp.RTE_R_OBCMgmt_S2SwtCtrlCmd_Enum
    connect CtAp_TorqPahMgmt.RTE_P_TorqPahMgmt_DesMotTq_Nm -> CtAp_DiagnosisApp.RTE_R_TorqPahMgmt_DesMotTq_Nm
    connect CtAp_TorqPahMgmt.RTE_P_TorqPahMgmt_EmacQstyMaxTq_Nm -> CtAp_DiagnosisApp.RTE_R_TorqPahMgmt_EmacQstyMaxTq_Nm
    connect CtAp_TorqPahMgmt.RTE_P_TorqPahMgmt_EmacQstyMinTq_Nm -> CtAp_DiagnosisApp.RTE_R_TorqPahMgmt_EmacQstyMinTq_Nm
    connect CtAp_TorqPahMgmt.RTE_P_TorqPahMgmt_SpdLmtReadInfo -> CtAp_DiagnosisApp.RTE_R_TorqPahMgmt_SpdLmtReadInfo
    connect CtAp_VehMot.RTE_P_VehMot_VehSpd_kph -> CtAp_DiagnosisApp.RTE_R_VehMot_VehSpd_kph
    connect CtAp_DiagnosisApp.RTE_P_DiagApp_SpdLmtUpdateInfo -> CtAp_TorqPahMgmt.RTE_R_DiagApp_SpdLmtUpdateInfo
    connect CtAp_DiagnosisApp.RTE_P_DiagApp_TireRadiusUpdateInfo -> CtAp_VehMot.RTE_R_DiagApp_TireRadiusUpdateInfo
    connect CtAp_CANHandler.RTE_P_ComM_SGWRemHvCtrlReq_Enum -> CtAp_LvMgmt.RTE_R_ComM_SGWRemHvCtrlReq_Enum
    connect CtAp_ChrMgmt.RTE_P_ChrMgmt_ChrgSts_Enum -> CtAp_LvMgmt.RTE_R_ChrMgmt_ChrgSts_Enum
    connect CtAp_ChrMgmt.RTE_P_ChrMgmt_CC2UDcDTC_Bus -> YDF_ErrorHandler.RTE_R_ChrMgmt_CC2UDcDTC_Bus
    connect YDF_NMHandler.IF_ComM_CGWPNC17 -> YDF_RVCUHandler.IF_ComM_CGWPNC17
    connect YDF_WakeUp_Swc.BSW_ECUMState -> YDF_RVCUHandler.BSW_ECUMState
    connect YDF_NMHandler.IF_ComM_VCUPNC3 -> YDF_RVCUHandler.IF_ComM_VCUPNC3
    connect YDF_ErrorHandler.BSW_NVMFailErrorStatus -> YDF_RVCUHandler.BSW_NVMFailErrorStatus
    connect YDF_NMHandler.IF_ComM_CGWPNC14 -> YDF_RVCUHandler.IF_ComM_CGWPNC14
    connect YDF_NMHandler.IF_ComM_VCUPNC17 -> YDF_RVCUHandler.IF_ComM_VCUPNC17
    connect YDF_NMHandler.IF_ComM_CGWPNC3 -> YDF_RVCUHandler.IF_ComM_CGWPNC3
    connect YDF_ErrorHandler.UDS_PwrCutRequest -> YDF_RVCUHandler.UDS_PwrCutRequest
    connect YDF_NMHandler.IF_ComM_CGWPNC0 -> YDF_RVCUHandler.IF_ComM_CGWPNC0
    connect YDF_NMHandler.IF_ComM_VCUPNC14 -> YDF_RVCUHandler.IF_ComM_VCUPNC14
    connect YDF_ErrorHandler.DCCAN_BusoffStatus -> YDF_RVCUHandler.DCCAN_BusoffStatus
    connect YDF_ErrorHandler.BSW_FuSaHWErrorStatus -> YDF_RVCUHandler.BSW_FuSaHWErrorStatus
    connect YDF_ErrorHandler.CHCAN_BusoffStatus -> YDF_RVCUHandler.CHCAN_BusoffStatus
    connect YDF_ErrorHandler.PTCAN_BusoffStatus -> YDF_RVCUHandler.PTCAN_BusoffStatus
    connect CtAp_ComMErr.RTE_P_ComM_CANBusOffInfo_Bus -> YDF_ErrorHandler.RTE_R_ComM_CANBusOffInfo_Bus
    delegate YDF_DiagHandler.CGW_VIN15 <-> outer port CGW_VIN15
    delegate YDF_DiagHandler.CGW_VIN4 <-> outer port CGW_VIN4
    delegate YDF_DiagHandler.CGW_VIN7 <-> outer port CGW_VIN7
    delegate YDF_DiagHandler.CGW_VIN9 <-> outer port CGW_VIN9
    delegate YDF_DiagHandler.CGW_VIN6 <-> outer port CGW_VIN6
    delegate YDF_DiagHandler.CGW_VIN10 <-> outer port CGW_VIN10
    delegate YDF_DiagHandler.CGW_VIN16 <-> outer port CGW_VIN16
    connect CtAp_LvMgmt.RTE_P_LvMgmt_AppNMReqInfo -> YDF_NMHandler.IF_LvMgmt_AppNMReqInfo
    delegate YDF_DiagHandler.CGW_VIN13 <-> outer port CGW_VIN13
    delegate YDF_DiagHandler.CGW_VIN3 <-> outer port CGW_VIN3
    delegate YDF_DiagHandler.CGW_VIN5 <-> outer port CGW_VIN5
    delegate YDF_DiagHandler.CGW_VIN2 <-> outer port CGW_VIN2
    delegate YDF_DiagHandler.CGW_VIN12 <-> outer port CGW_VIN12
    delegate YDF_DiagHandler.CGW_VIN11 <-> outer port CGW_VIN11
    delegate YDF_DiagHandler.CGW_VIN0 <-> outer port CGW_VIN0
    delegate YDF_DiagHandler.CGW_VIN8 <-> outer port CGW_VIN8
    delegate YDF_DiagHandler.CGW_VIN14 <-> outer port CGW_VIN14
    connect YDF_NMHandler.IF_ComM_CGWPNC1 -> YDF_RVCUHandler.IF_ComM_CGWPNC1
    connect YDF_NMHandler.IF_ComM_VCUPNC1 -> YDF_RVCUHandler.IF_ComM_VCUPNC1
    delegate YDF_DiagHandler.CGW_VIN1 <-> outer port CGW_VIN1
    delegate YDF_DiagHandler.CGW_VERSION1 <-> outer port CGW_VERSION1
    delegate YDF_DiagHandler.CGW_VERSION2 <-> outer port CGW_VERSION2
    connect CtAp_ChassisMgmt.RTE_P_ChassisMgmt_AccrPedlKdStsInfo -> CtAp_TorqPahMgmt.RTE_R_ChassisMgmt_AccrPedlKdStsInfo
    connect YDF_NMHandler.RTE_R_ComM_CGWPNC{4..6} -> CtAp_CANHandler.RTE_R_ComM_CGWPNC{4..6}
    connect YDF_NMHandler.RTE_R_ComM_VCUPNC4 -> CtAp_CANHandler.RTE_R_ComM_VCUPNC4
    connect CtAp_DiagnosisApp.RTE_P_DiagApp_DisableDCMReqInfo -> CtAp_CANHandler.RTE_R_DiagApp_DisableDCMReqInfo
    connect CtAp_DiagnosisApp.RTE_P_DiagApp_DisableDCMReqInfo -> CtAp_ChassisMgmt.RTE_R_DiagApp_DisableDCMReqInfo
    connect CtAp_HWHandler.RTE_P_IOAbs_AccrPedl1SplyVoltInfo -> CtAp_ChassisMgmt.RTE_R_IOAbs_AccrPedl1SplyVoltInfo
    connect CtAp_HWHandler.RTE_P_IOAbs_AccrPedl2SplyVoltInfo -> CtAp_ChassisMgmt.RTE_R_IOAbs_AccrPedl2SplyVoltInfo
    connect CtAp_CANHandler.RTE_P_ComM_IBSCddActvInfo -> CtAp_ChassisMgmt.RTE_R_ComM_IBSCddActvInfo
    connect CtAp_DiagnosisApp.RTE_P_DiagApp_DisableDCMReqInfo -> CtAp_ChrMgmt.RTE_R_DiagApp_DisableDCMReqInfo
    connect CtAp_DiagnosisApp.RTE_P_DiagApp_DisableDCMReqInfo -> CtAp_DCChrMgmt.RTE_R_DiagApp_DisableDCMReqInfo
    connect CtAp_ModMgmt.RTE_P_ModMgmt_HvSts_Enum -> CtAp_EgyMgmt.RTE_R_ModMgmt_HvSts_Enum
    connect CtAp_DiagnosisApp.RTE_P_DiagApp_DisableDCMReqInfo -> CtAp_ErrMgmt.RTE_R_DiagApp_DisableDCMReqInfo
    connect CtAp_DiagnosisApp.RTE_P_DiagApp_DisableDCMReqInfo -> CtAp_FctSftyMon.RTE_R_DiagApp_DisableDCMReqInfo
    connect CtAp_LINHandler.RTE_P_ComM_BSNodComFailrInfo -> CtAp_HvMgmt.RTE_R_ComM_BSNodComFailrInfo
    connect CtAp_DiagnosisApp.RTE_P_DiagApp_DisableDCMReqInfo -> CtAp_HvMgmt.RTE_R_DiagApp_DisableDCMReqInfo
    connect CtAp_ErrMgmt.RTE_P_ErrMgmt_DCDCFailLamp_Flg -> CtAp_LINHandler.RTE_R_ErrMgmt_DCDCFailLamp_Flg
    connect CtAp_ErrMgmt.RTE_P_ErrMgmt_DrvMotTempOvrLamp_Bus -> CtAp_LINHandler.RTE_R_ErrMgmt_DrvMotTempOvrLamp_Bus
    connect CtAp_ErrMgmt.RTE_P_ErrMgmt_HvBattFailLamp -> CtAp_LINHandler.RTE_R_ErrMgmt_HvBattFailLamp
    connect CtAp_LvMgmt.RTE_P_LvMgmt_IndicatorLightStsInfo -> CtAp_LINHandler.RTE_R_LvMgmt_IndicatorLightStsInfo
    connect CtAp_LINHandler.RTE_P_ComM_BSBattSOHInfo -> CtAp_LvMgmt.RTE_R_ComM_BSBattSOHInfo
    connect CtAp_LINHandler.RTE_P_ComM_BSNodComFailrInfo -> CtAp_LvMgmt.RTE_R_ComM_BSNodComFailrInfo
    connect CtAp_ChassisMgmt.RTE_P_ChassisMgmt_AccrPedlKdStsInfo -> CtAp_CANHandler.RTE_R_ChassisMgmt_AccrPedlKdStsInfo
    connect CtAp_ChassisMgmt.RTE_P_ChassisMgmt_AccrPedlRawPosnInfo -> CtAp_CANHandler.RTE_R_ChassisMgmt_AccrPedlRawPosnInfo
    connect CtAp_ChassisMgmt.RTE_P_ChassisMgmt_VirtAccrPedlPosnInfo -> CtAp_CANHandler.RTE_R_ChassisMgmt_VirtAccrPedlPosnInfo
    connect CtAp_ChassisMgmt.RTE_P_ChassisMgmt_VirtAccrPedlVldInfo -> CtAp_CANHandler.RTE_R_ChassisMgmt_VirtAccrPedlVldInfo
    connect CtAp_LvMgmt.RTE_P_LvMgmt_ReachLimStdInfo -> CtAp_CANHandler.RTE_R_LvMgmt_ReachLimStdInfo
    connect CtAp_LvMgmt.RTE_P_LvMgmt_VCUlimLvlInfo -> CtAp_CANHandler.RTE_R_LvMgmt_VCUlimLvlInfo
    connect CtAp_DCComM.RTE_P_ComM_CCSOutpIDc_A -> CtAp_ChrMgmt.RTE_R_ComM_CCSOutpIDc_A
    connect CtAp_DCComM.RTE_P_ComM_CCSOutpUDc_V -> CtAp_ChrMgmt.RTE_R_ComM_CCSOutpUDc_V
    connect CtAp_CANHandler.RTE_P_ComM_BCM05MsgErrInfo_Bus -> CtAp_ComMErr.RTE_R_ComM_BCM05MsgErrInfo_Bus
    connect CtAp_CANHandler.RTE_P_ComM_DCMFRMsgErrInfo_Bus -> CtAp_ComMErr.RTE_R_ComM_DCMFRMsgErrInfo_Bus
    connect CtAp_CANHandler.RTE_P_ComM_DCMRLMsgErrInfo_Bus -> CtAp_ComMErr.RTE_R_ComM_DCMRLMsgErrInfo_Bus
    connect CtAp_CANHandler.RTE_P_ComM_DCMRRMsgErrInfo_Bus -> CtAp_ComMErr.RTE_R_ComM_DCMRRMsgErrInfo_Bus
    delegate CtAp_DCComM.CCS_OutputCurrent <-> outer port CCS_OutputCurrent
    connect CtAp_CANHandler.RTE_P_ComM_BrkFldWarnStsInfo -> CtAp_LINHandler.RTE_R_ComM_BrkFldWarnStsInfo
    connect CtAp_CANHandler.RTE_P_ComM_CGWVehStatusInfo -> CtAp_LINHandler.RTE_R_ComM_CGWVehStatusInfo
    connect CtAp_CANHandler.RTE_P_ComM_DoorFLStsInfo -> CtAp_LINHandler.RTE_R_ComM_DoorFLStsInfo
    connect CtAp_CANHandler.RTE_P_ComM_DoorFRStsInfo -> CtAp_LINHandler.RTE_R_ComM_DoorFRStsInfo
    connect CtAp_CANHandler.RTE_P_ComM_DoorRLStsInfo -> CtAp_LINHandler.RTE_R_ComM_DoorRLStsInfo
    connect CtAp_CANHandler.RTE_P_ComM_DoorRRStsInfo -> CtAp_LINHandler.RTE_R_ComM_DoorRRStsInfo
    connect CtAp_CANHandler.RTE_P_ComM_EBDFltStsInfo -> CtAp_LINHandler.RTE_R_ComM_EBDFltStsInfo
    connect CtAp_CANHandler.RTE_P_ComM_FLSeatBltRmnReqInfo -> CtAp_LINHandler.RTE_R_ComM_FLSeatBltRmnReqInfo
    connect CtAp_CANHandler.RTE_P_ComM_FRSeatBltRmnReqInfo -> CtAp_LINHandler.RTE_R_ComM_FRSeatBltRmnReqInfo
    connect CtAp_CANHandler.RTE_P_ComM_IBSSysStsInfo -> CtAp_LINHandler.RTE_R_ComM_IBSSysStsInfo
    connect CtAp_ComMErr.RTE_P_ComM_NodComFailr -> CtAp_LINHandler.RTE_R_ComM_NodComFailr
    connect CtAp_CANHandler.RTE_P_ComM_PassAirbStsInfo -> CtAp_LINHandler.RTE_R_ComM_PassAirbStsInfo
    connect CtAp_CANHandler.RTE_P_ComM_PassWarnLampStsInfo -> CtAp_LINHandler.RTE_R_ComM_PassWarnLampStsInfo
    connect CtAp_CANHandler.RTE_P_ComM_RLSeatBltRmnReqInfo -> CtAp_LINHandler.RTE_R_ComM_RLSeatBltRmnReqInfo
    connect CtAp_CANHandler.RTE_P_ComM_RollrBenchModInfo -> CtAp_LINHandler.RTE_R_ComM_RollrBenchModInfo
    connect CtAp_CANHandler.RTE_P_ComM_RRSeatBltRmnReqInfo -> CtAp_LINHandler.RTE_R_ComM_RRSeatBltRmnReqInfo
    connect CtAp_CANHandler.RTE_P_ComM_IVILVLimPopInfo -> CtAp_LvMgmt.RTE_R_ComM_IVILVLimPopInfo
    connect CtAp_CANHandler.RTE_P_ComM_OBCLostSpcInfo -> CtAp_LvMgmt.RTE_R_ComM_OBCLostSpcInfo
    connect CtAp_CANHandler.RTE_P_ComM_PEPSPwrMod_Enum -> CtAp_LvMgmt.RTE_R_ComM_PEPSPwrMod_Enum
    connect CtAp_DiagnosisApp.RTE_P_DiagApp_DisableDCMReqInfo -> CtAp_LvMgmt.RTE_R_DiagApp_DisableDCMReqInfo
    connect CtAp_DiagnosisApp.RTE_P_DiagApp_StayInRunReqInfo -> CtAp_LvMgmt.RTE_R_DiagApp_StayInRunReqInfo
    connect CtAp_DiagnosisApp.RTE_P_DiagApp_DisableDCMReqInfo -> CtAp_ModMgmt.RTE_R_DiagApp_DisableDCMReqInfo
    connect CtAp_DiagnosisApp.RTE_P_DiagApp_DisableDCMReqInfo -> CtAp_OBCMgmt.RTE_R_DiagApp_DisableDCMReqInfo
    connect CtAp_DiagnosisApp.RTE_P_DiagApp_ClearRangeEstNVMReqInfo -> CtAp_RngEstimn.RTE_R_DiagApp_ClearRangeEstNVMReqInfo
    connect CtAp_ChassisMgmt.RTE_P_ChassisMgmt_AccrPedlRawPosnInfo -> CtAp_VehMot.RTE_R_ChassisMgmt_AccrPedlRawPosnInfo
    connect YDF_NMHandler.IF_ComM_VCUPNC0 -> CtAp_CANHandler.RTE_R_ComM_VCUPNC0
    connect YDF_NMHandler.IF_ComM_VCUPNC4 -> YDF_RVCUHandler.IF_ComM_VCUPNC0
    connect CtAp_ChassisMgmt.RTE_P_ChassisMgmt_AccrPedlSplyVolt1HiDTCInfo -> YDF_ErrorHandler.RTE_R_ChassisMgmt_AccrPedlSplyVolt1HiDTCInfo
    connect CtAp_ChassisMgmt.RTE_P_ChassisMgmt_AccrPedlSplyVolt1LoDTCInfo -> YDF_ErrorHandler.RTE_R_ChassisMgmt_AccrPedlSplyVolt1LoDTCInfo
    connect CtAp_ChassisMgmt.RTE_P_ChassisMgmt_AccrPedlSplyVolt2HiDTCInfo -> YDF_ErrorHandler.RTE_R_ChassisMgmt_AccrPedlSplyVolt2HiDTCInfo
    connect CtAp_ChassisMgmt.RTE_P_ChassisMgmt_AccrPedlSplyVolt2LoDTCInfo -> YDF_ErrorHandler.RTE_R_ChassisMgmt_AccrPedlSplyVolt2LoDTCInfo
    connect CtAp_EgyMgmt.RTE_P_EgyMgmt_V2LDisChgPwrLmtInfo -> CtAp_CANHandler.RTE_R_EgyMgmt_V2LDisChgPwrLmtInfo
    connect CtAp_EgyMgmt.RTE_P_EgyMgmt_V2LDisChgPwrLmtInfo -> CtAp_DiagnosisApp.RTE_R_EgyMgmt_V2LDisChgPwrLmtInfo
    connect CtAp_RngEstimn.RTE_P_RngEst_ClearNVMSucessInfo -> CtAp_DiagnosisApp.RTE_R_RngEst_ClearNVMSucessInfo
    connect CtAp_LvMgmt.RTE_P_LvMgmt_StayInRun_Flg -> YDF_WakeUp_Swc.RTE_P_LvMgmt_StayInRun_Flg
    connect YDF_NMHandler.RTE_P_ComM_NMStatusInfo -> CtAp_LvMgmt.RTE_R_ComM_NMStatusInfo
    connect CtAp_CANHandler.RTE_P_ComM_DrvrWarnLampStsInfo -> CtAp_LINHandler.RTE_R_ComM_DrvrWarnLampStsInfo
    connect CtAp_ErrMgmt.RTE_P_ErrMgmt_HvBattTempOvrLamp_Bus -> CtAp_LINHandler.RTE_R_ErrMgmt_HvBattTempOvrLamp_Bus
    connect YDF_NMHandler.IF_ComM_VCUPNC5 -> CtAp_CANHandler.RTE_R_ComM_VCUPNC5
    connect YDF_NMHandler.IF_ComM_VCUPNC6 -> CtAp_CANHandler.RTE_R_ComM_VCUPNC6
    connect CtAp_LvMgmt.RTE_P_LvMgmt_KL15CtrlReq_Flg -> CtAp_CANHandler.RTE_R_LvMgmt_KL15CtrlReq_Flg
    connect YDF_NMHandler.IF_ComM_CGWPNC{4..6} -> CtAp_CANHandler.RTE_R_ComM_CGWPNC{4..6}
    connect CtAp_DiagnosisApp.RTE_P_DiagApp_DisableDCMReqInfo -> CtAp_ComMErr.RTE_R_DiagApp_DisableDCMReqInfo
    connect CtAp_CANHandler.RTE_P_ComM_BMSChrgReqSts_Enum -> CtAp_OBCMgmt.RTE_R_ComM_BMSChrgReqSts_Enum
    connect CtAp_ComMErr.RTE_P_ComM_NodComFailr -> CtAp_DiagnosisApp.RTE_R_ComM_NodComFailr
    connect CtAp_CANHandler.RTE_P_ComM_MotActTq_Nm -> CtAp_ChassisMgmt.RTE_R_ComM_MotActTq_Nm
    connect CtAp_VehMot.RTE_P_VehMot_VehDragTq_Nm -> CtAp_ChassisMgmt.RTE_R_VehMot_VehDragTq_Nm
    connect CtAp_ChrMgmt.RTE_P_ChrMgmt_PosRlyReqSts_Enum -> CtAp_HvMgmt.RTE_R_ChrMgmt_PosRlyReqSts_Enum
    connect CtAp_LvMgmt.RTE_P_LvMgmt_AppNMReqInfo -> CtAp_HvMgmt.RTE_R_LvMgmt_AppNMReqInfo
    connect CtAp_DiagnosisApp.RTE_P_DiagApp_DisableDCMReqInfo -> CtAp_LINHandler.RTE_R_DiagApp_DisableDCMReqInfo
    connect CtAp_ChassisMgmt.RTE_P_ChassisMgmt_DrvCoorrDesTq_Nm -> CtAp_TorqPahMgmt.RTE_R_ChassisMgmt_DrvCoorDesTq_Nm
    connect CtAp_ChassisMgmt.RTE_P_ChassisMgmt_DrvAsscCtrlOvrdSts_Flg_1 -> CtAp_CANHandler.RTE_R_ChassisMgmt_DrvAsscCtrlOvrdSts_Flg
    connect CtAp_ChrMgmt.RTE_P_ChrMgmt_PosRlyReqSts_Enum -> CtAp_CANHandler.RTE_R_ChrMgmt_PosRlyReqSts_Enum
    connect CtAp_CANHandler.RTE_P_ComM_IBSTcsFltSts_Flg -> CtAp_TorqPahMgmt.RTE_R_ComM_IBSTcsFltSts_Flg
    connect YDF_NVMgmt.RTE_RP_ChassisMgmtInfo -> CtAp_ChassisMgmt.RTE_RP_ChassisMgmtInfo
    connect CtAp_DCChrMgmt.RTE_P_DCChrMgmt_DCFCClsReq_Flg -> CtAp_CANHandler.RTE_R_DCChrMgmt_DCFCClsReq_Flg
    connect CtAp_HvMgmt.RTE_P_HvMgmt_MCUWrkModActSts_Enum -> CtAp_TorqPahMgmt.RTE_R_HvMgmt_MCUWrkModActSts_Enum
    connect CtAp_ChrMgmt.RTE_P_ChrMgmt_PckPTCAllwbl_Flg -> CtAp_EgyMgmt.RTE_R_ChrMgmt_PckPTCAllwbl_Flg
    connect CtAp_CANHandler.RTE_P_ComM_OBCChrgOutpPwrAvl_Kw -> CtAp_EgyMgmt.RTE_R_ComM_OBCChrgOutpPwrAvl_Kw
    connect CtAp_CANHandler.RTE_P_ComM_BMSChrgReqSts_Enum -> CtAp_EgyMgmt.RTE_R_ComM_BMSChrgReqSts_Enum
    connect CtAp_FctSftyMon.RTE_P_FctSftyMon_DesVehDecelSpdOverFltInfo_Bus -> CtAp_ErrMgmt.RTE_R_FctSftyMon_DesVehDecelSpdOverFltInfo_Bus
    connect CtAp_ChrMgmt.RTE_P_ChrMgmt_PosRlyReqSts_Enum -> CtAp_DiagnosisApp.RTE_R_ChrMgmt_PosRlyReqSts_Enum
    connect CtAp_LvMgmt.RTE_P_LvMgmt_AppNMReqInfo -> CtAp_CANHandler.RTE_R_LvMgmt_AppNMReqInfo
    connect CtAp_CANHandler.RTE_P_ComM_ACUYawRate -> CtAp_ChassisMgmt.RTE_R_ComM_ACUYawRate
    connect YDF_CanHandler.IF_ComM_TriggerASWMsgReqInfo -> CtAp_CANHandler.RTE_R_ComM_TriggerASWMsgReqInfo
    connect CtAp_ChassisMgmt.RTE_P_ChassisMgmt_AccrPedlRawPosnInfo -> CtAp_DiagnosisApp.RTE_R_ChassisMgmt_AccrPedlRawPosnInfo
    connect CtAp_CANHandler.RTE_P_ComM_OBCChrgSts_Enum -> CtAp_DiagnosisApp.RTE_R_ComM_OBCChrgSts_Enum
    connect CtAp_CANHandler.RTE_P_ComM_OBCCPPwmDuty_pct -> CtAp_ChrMgmt.RTE_R_ComM_OBCCPPwmDuty_pct
    connect CtAp_HvMgmt.RTE_P_HvMgmt_BMSNegRlyActSts_Enum -> CtAp_ChrMgmt.RTE_R_HvMgmt_BMSNegRlyActSts_Enum
    connect CtAp_DCComM.RTE_P_ComM_RxSts_Flg -> CtAp_ChrMgmt.RTE_R_ComM_RxSts_Flg
    delegate CtAp_LINHandler.FRC_Vl_OV <-> outer port FRC_Vl_OV
    delegate CtAp_LINHandler.FRC_Vl_UV <-> outer port FRC_Vl_UV
    delegate CtAp_LINHandler.FRC_ComFtonNet <-> outer port FRC_ComFtonNet
    connect CtAp_ChassisMgmt.RTE_P_ChassisMgmt_CrpCtrlDesTq_Nm -> CtAp_CANHandler.RTE_R_ChassisMgmt_CrpCtrlDesTq_Nm
    connect CtAp_LINHandler.RTE_P_ComM_BSBatCrnt -> CtAp_CANHandler.RTE_R_ComM_BSBatCrnt
    connect CtAp_FctSftyMon.RTE_P_FctSftyMon_ActGear_Enum -> CtAp_CANHandler.RTE_R_FctSftyMon_ActGear_Enum
    connect CtAp_FctSftyMon.RTE_P_FctSftyMon_EPBReq -> CtAp_CANHandler.RTE_R_FctSftyMon_EPBReq
    connect CtAp_GearMgmt.RTE_P_GearMgmt_InvldGearSel_Enum -> CtAp_CANHandler.RTE_R_GearMgmt_InvldGearSel_Enum
    connect CtAp_GearMgmt.RTE_P_GearMgmt_TarGear_Enum -> CtAp_CANHandler.RTE_R_GearMgmt_TarGear_Enum
    connect CtAp_LvMgmt.RTE_P_LvMgmt_IndicatorLightStsInfo -> CtAp_CANHandler.RTE_R_LvMgmt_IndicatorLightStsInfo
    connect CtAp_TorqPahMgmt.RTE_P_TorqPahMgmt_MaxVehSpdLmtTq_Nm -> CtAp_CANHandler.RTE_R_TorqPahMgmt_MaxVehSpdLmtTq_Nm
    connect CtAp_TorqPahMgmt.RTE_P_TorqPahMgmt_MotDampLmtTq -> CtAp_CANHandler.RTE_R_TorqPahMgmt_MotDampLmtTq
    connect CtAp_CANHandler.RTE_P_ComM_ADCUAccMod_Enum -> CtAp_ChassisMgmt.RTE_R_ComM_ADCUAccMod_Enum
    connect CtAp_CANHandler.RTE_P_ComM_ADCUPrkMod -> CtAp_ChassisMgmt.RTE_R_ComM_ADCUPrkMod
    connect CtAp_CANHandler.RTE_P_ComM_IBSDtcFltSts -> CtAp_ChassisMgmt.RTE_R_ComM_IBSDtcFltSts
    connect CtAp_FctSftyMon.RTE_P_FctSftyMon_ActGear_Enum -> CtAp_ChassisMgmt.RTE_R_FctSftyMon_ActGear_Enum
    connect CtAp_CANHandler.RTE_P_ComM_BMSBattAllowChrgIDc_A -> CtAp_ChrMgmt.RTE_R_ComM_BMSBattAllowChrgIDc_A
    connect CtAp_CANHandler.RTE_P_ComM_BMSPTCRlyStsInfo -> CtAp_ChrMgmt.RTE_R_ComM_BMSPTCRlyStsInfo
    connect CtAp_DCChrMgmt.RTE_P_DCChrMgmt_BSTTxReqSts -> CtAp_ChrMgmt.RTE_R_DCChrMgmt_BSTTxReqSts
    connect CtAp_FctSftyMon.RTE_P_FctSftyMon_ActGear_Enum -> CtAp_ChrMgmt.RTE_R_FctSftyMon_ActGear_Enum
    connect CtAp_OBCMgmt.RTE_P_OBCMgmt_OBCEnaCmd_Enum -> CtAp_ChrMgmt.RTE_R_OBCMgmt_OBCEnaCmd_Enum
    connect CtAp_FctSftyMon.RTE_P_FctSftyMon_ActGear_Enum -> CtAp_DiagnosisApp.RTE_R_FctSftyMon_ActGear_Enum
    connect CtAp_FctSftyMon.RTE_P_FctSftyMon_ActGear_Enum -> CtAp_EgyMgmt.RTE_R_FctSftyMon_ActGear_Enum
    connect CtAp_ChassisMgmt.RTE_R_ChassisMgmt_BrkSts_Enum -> CtAp_FctSftyMon.RTE_R_ChassisMgmt_BrkSts_Enum
    connect CtAp_CANHandler.RTE_P_ComM_EPBWrkSts_Enum -> CtAp_FctSftyMon.RTE_R_ComM_EPBWrkSts_Enum
    connect CtAp_CANHandler.RTE_P_ComM_GearRNDBtn_Enum -> CtAp_FctSftyMon.RTE_R_ComM_GearRNDBtn_Enum
    connect CtAp_CANHandler.RTE_P_ComM_GearRNDBtnFltSts_Flg -> CtAp_FctSftyMon.RTE_R_ComM_GearRNDBtnFltSts_Flg
    connect CtAp_CANHandler.RTE_P_ComM_IBSEPBControllerSts -> CtAp_FctSftyMon.RTE_R_ComM_IBSEPBControllerSts
    connect CtAp_CANHandler.RTE_P_ComM_IBSSts02MsgErrInfo_Bus -> CtAp_FctSftyMon.RTE_R_ComM_IBSSts02MsgErrInfo_Bus
    connect CtAp_CANHandler.RTE_P_ComM_IBSSts05MsgErrInfo_Bus -> CtAp_FctSftyMon.RTE_R_ComM_IBSSts05MsgErrInfo_Bus
    connect CtAp_CANHandler.RTE_P_ComM_IBSSUBEPBControllerSts -> CtAp_FctSftyMon.RTE_R_ComM_IBSSUBEPBControllerSts
    connect CtAp_CANHandler.RTE_P_ComM_IBSSUBEPBWrkSts -> CtAp_FctSftyMon.RTE_R_ComM_IBSSUBEPBWrkSts
    connect CtAp_CANHandler.RTE_P_ComM_IBSTarGearReq_Enum -> CtAp_FctSftyMon.RTE_R_ComM_IBSTarGearReq_Enum
    connect CtAp_CANHandler.RTE_P_ComM_IBSTqMsgErrInfo_Bus -> CtAp_FctSftyMon.RTE_R_ComM_IBSTqMsgErrInfo_Bus
    connect CtAp_CANHandler.RTE_P_ComM_IVI01MsgErrInfo_Bus -> CtAp_FctSftyMon.RTE_R_ComM_IVI01MsgErrInfo_Bus
    connect CtAp_CANHandler.RTE_P_ComM_IVIGearReq_Enum -> CtAp_FctSftyMon.RTE_R_ComM_IVIGearReq_Enum
    connect CtAp_CANHandler.RTE_P_ComM_PRNDMsgErrInfo_Bus -> CtAp_FctSftyMon.RTE_R_ComM_PRNDMsgErrInfo_Bus
    connect CtAp_GearMgmt.RTE_P_GearMgmt_ADASReqVld -> CtAp_FctSftyMon.RTE_R_GearMgmt_ADASReqVld
    connect CtAp_GearMgmt.RTE_P_GearMgmt_GearCalEPBPrk -> CtAp_FctSftyMon.RTE_R_GearMgmt_GearCalEPBPrk
    connect CtAp_GearMgmt.RTE_P_GearMgmt_GearCalEPBRels -> CtAp_FctSftyMon.RTE_R_GearMgmt_GearCalEPBRels
    connect CtAp_GearMgmt.RTE_P_GearMgmt_UnCfmdActGear_Enum -> CtAp_FctSftyMon.RTE_R_GearMgmt_UnCfmdActGear_Enum
    connect CtAp_VehMot.RTE_P_VehMot_VehSpdABS_kph -> CtAp_FctSftyMon.RTE_R_VehMot_VehSpdABS_kph
    connect CtAp_VehMot.RTE_P_VehMot_VehSpdVld_Flg -> CtAp_FctSftyMon.RTE_R_VehMot_VehSpdVld_Flg
    connect CtAp_ChassisMgmt.RTE_P_ChassisMgmt_AccrPedlRawPosnInfo -> CtAp_GearMgmt.RTE_R_ChassisMgmt_AccrPedlRawPosnInfo
    connect CtAp_ChassisMgmt.RTE_R_ChassisMgmt_BrkSts_Enum -> CtAp_GearMgmt.RTE_R_ChassisMgmt_BrkSts_Enum
    connect CtAp_ChrMgmt.RTE_P_ChrMgmt_ChrgSts_Enum -> CtAp_GearMgmt.RTE_R_ChrMgmt_ChrgSts_Enum
    connect CtAp_CANHandler.RTE_P_ComM_ADCUAccMod_Enum -> CtAp_GearMgmt.RTE_R_ComM_ADCUAccMod_Enum
    connect CtAp_CANHandler.RTE_P_ComM_ADCUAEBSt -> CtAp_GearMgmt.RTE_R_ComM_ADCUAEBSt
    connect CtAp_CANHandler.RTE_P_ComM_ADCUDAMod -> CtAp_GearMgmt.RTE_R_ComM_ADCUDAMod
    connect CtAp_CANHandler.RTE_P_ComM_ADCUPrkMod -> CtAp_GearMgmt.RTE_R_ComM_ADCUPrkMod
    connect CtAp_CANHandler.RTE_P_ComM_ADCURemPrkMod -> CtAp_GearMgmt.RTE_R_ComM_ADCURemPrkMod
    connect CtAp_CANHandler.RTE_P_ComM_BCMImmoSts_Flg -> CtAp_GearMgmt.RTE_R_ComM_BCMImmoSts_Flg
    connect CtAp_CANHandler.RTE_P_ComM_GearPBtn_Enum -> CtAp_GearMgmt.RTE_R_ComM_GearPBtn_Enum
    connect CtAp_CANHandler.RTE_P_ComM_GearPBtnFltSts_Flg -> CtAp_GearMgmt.RTE_R_ComM_GearPBtnFltSts_Flg
    connect CtAp_CANHandler.RTE_P_ComM_GearRNDBtn_Enum -> CtAp_GearMgmt.RTE_R_ComM_GearRNDBtn_Enum
    connect CtAp_CANHandler.RTE_P_ComM_GearRNDBtnFltSts_Flg -> CtAp_GearMgmt.RTE_R_ComM_GearRNDBtnFltSts_Flg
    connect CtAp_CANHandler.RTE_P_ComM_IBSTarGearReq_Enum -> CtAp_GearMgmt.RTE_R_ComM_IBSTarGearReq_Enum
    connect CtAp_CANHandler.RTE_P_ComM_IVI01MsgErrInfo_Bus -> CtAp_GearMgmt.RTE_R_ComM_IVI01MsgErrInfo_Bus
    connect CtAp_CANHandler.RTE_P_ComM_IVIGearReq_Enum -> CtAp_GearMgmt.RTE_R_ComM_IVIGearReq_Enum
    connect CtAp_ComMErr.RTE_P_ComM_NodComFailr -> CtAp_GearMgmt.RTE_R_ComM_NodComFailr
    connect CtAp_CANHandler.RTE_P_ComM_PEPSPwrMod_Enum -> CtAp_GearMgmt.RTE_R_ComM_PEPSPwrMod_Enum
    connect CtAp_CANHandler.RTE_P_ComM_PRNDMsgErrInfo_Bus -> CtAp_GearMgmt.RTE_R_ComM_PRNDMsgErrInfo_Bus
    connect CtAp_FctSftyMon.RTE_P_FctSftyMon_ActGear_Enum -> CtAp_GearMgmt.RTE_R_FctSftyMon_ActGear_Enum
    connect CtAp_FctSftyMon.RTE_P_FctSftyMon_EPBPrkReqFail -> CtAp_GearMgmt.RTE_R_FctSftyMon_EPBPrkReqFail
    connect CtAp_FctSftyMon.RTE_P_FctSftyMon_EPBRelsReqFail -> CtAp_GearMgmt.RTE_R_FctSftyMon_EPBRelsReqFail
    connect CtAp_FctSftyMon.RTE_P_FctSftyMon_EPBReqCmpl -> CtAp_GearMgmt.RTE_R_FctSftyMon_EPBReqCmpl
    connect CtAp_FctSftyMon.RTE_P_FctSftyMon_EPBWrkSts -> CtAp_GearMgmt.RTE_R_FctSftyMon_EPBWrkSts
    connect CtAp_FctSftyMon.RTE_P_FctSftyMon_WakeUpFinish -> CtAp_GearMgmt.RTE_R_FctSftyMon_WakeUpFinish
    connect CtAp_ModMgmt.RTE_P_ModMgmt_HvSts_Enum -> CtAp_GearMgmt.RTE_R_ModMgmt_HvSts_Enum
    connect CtAp_VehMot.RTE_P_VehMot_VehDrvDir_Enum -> CtAp_GearMgmt.RTE_R_VehMot_VehDrvDir_Enum
    connect CtAp_VehMot.RTE_P_VehMot_VehSpdABS_kph -> CtAp_GearMgmt.RTE_R_VehMot_VehSpdABS_kph
    connect CtAp_VehMot.RTE_P_VehMot_VehSpdVld_Flg -> CtAp_GearMgmt.RTE_R_VehMot_VehSpdVld_Flg
    connect CtAp_VehMot.RTE_P_VehMot_VehStdl_Flg -> CtAp_GearMgmt.RTE_R_VehMot_VehStdl_Flg
    connect CtAp_ChrMgmt.RTE_P_ChrMgmt_PreheatReqHvOff -> CtAp_HvMgmt.RTE_R_ChrMgmt_PreheatReqHvOff
    connect CtAp_CANHandler.RTE_P_ComM_SGWSysRdyReq -> CtAp_HvMgmt.RTE_R_ComM_SGWSysRdyReq
    connect CtAp_FctSftyMon.RTE_P_FctSftyMon_ActGear_Enum -> CtAp_HvMgmt.RTE_R_FctSftyMon_ActGear_Enum
    connect CtAp_CANHandler.RTE_P_ComM_IVIVrState -> CtAp_LINHandler.RTE_R_ComM_IVIVrState
    connect YDF_NVMgmt.RTE_RP_GearMgmtInfo -> CtAp_FctSftyMon.RTE_RP_GearMgmtInfo
    connect CtAp_LINHandler.RTE_P_ComM_BSComFtonNet -> CtAp_LvMgmt.RTE_R_ComM_BSComFtonNet
    connect CtAp_FctSftyMon.RTE_P_FctSftyMon_ActGear_Enum -> CtAp_ModMgmt.RTE_R_FctSftyMon_ActGear_Enum
    connect CtAp_LvMgmt.RTE_P_LvMgmt_WakeUpReq_Flg -> CtAp_ModMgmt.RTE_R_LvMgmt_WakeUpReq_Flg
    connect CtAp_CANHandler.RTE_P_ComM_DCMAmbTemp -> CtAp_RngEstimn.RTE_R_ComM_DCMAmbTemp
    connect CtAp_CANHandler.RTE_P_ComM_DCMAmbTempVld -> CtAp_RngEstimn.RTE_R_ComM_DCMAmbTempVld
    connect CtAp_CANHandler.RTE_P_ComM_IBSReqIncTqSts_Flg -> CtAp_TorqPahMgmt.RTE_R_ComM_IBSReqIncTqSts_Flg
    connect CtAp_CANHandler.RTE_P_ComM_IBSReqRednTqSts_Flg -> CtAp_TorqPahMgmt.RTE_R_ComM_IBSReqRednTqSts_Flg
    connect CtAp_ErrMgmt.RTE_P_ErrMgmt_FobdEgyRcov_Flg -> CtAp_TorqPahMgmt.RTE_R_ErrMgmt_FobdEgyRcov_Flg
    connect CtAp_ErrMgmt.RTE_P_ErrMgmt_ImdtZeroTq_Flg -> CtAp_TorqPahMgmt.RTE_R_ErrMgmt_ImdtZeroTq_Flg
    connect CtAp_FctSftyMon.RTE_P_FctSftyMon_ActGear_Enum -> CtAp_TorqPahMgmt.RTE_R_FctSftyMon_ActGear_Enum
    connect CtAp_FctSftyMon.RTE_P_FctSftyMon_TarGearPInhbTq -> CtAp_TorqPahMgmt.RTE_R_FctSftyMon_TarGearPInhbTq
    connect CtAp_ChassisMgmt.RTE_P_ChassisMgmt_CrpCtrlSts -> CtAp_VehMot.RTE_R_ChassisMgmt_CrpCtrlSts
    connect CtAp_ChassisMgmt.RTE_P_ChassisMgmt_DrvDmdHiPrio_Flg -> CtAp_VehMot.RTE_R_ChassisMgmt_DrvDmdHiPrio_Flg
    connect CtAp_CANHandler.RTE_P_ComM_IBSPlgrPrs_Bar -> CtAp_VehMot.RTE_R_ComM_IBSPlgrPrs_Bar
    connect CtAp_CANHandler.RTE_P_ComM_MotActTqVld_Flg -> CtAp_VehMot.RTE_R_ComM_MotActTqVld_Flg
    connect CtAp_FctSftyMon.RTE_P_FctSftyMon_ActGear_Enum -> CtAp_VehMot.RTE_R_FctSftyMon_ActGear_Enum
    connect CtAp_VehMot.RTE_P_VehMot_VehSpdVld_Flg -> CtAp_VehMot.RTE_R_VehMot_VehSpdVld_Flg
    connect CtAp_CANHandler.RTE_P_ComM_ADCUAEB01MsgErrInfo_Bus -> CtAp_ComMErr.RTE_R_ComM_ADCUAEB01MsgErrInfo_Bus
    connect CtAp_CANHandler.RTE_P_ComM_ADCUAPS01MsgErrInfo_Bus -> CtAp_ComMErr.RTE_R_ComM_ADCUAPS01MsgErrInfo_Bus
    connect CtAp_CANHandler.RTE_P_ComM_ADCUDAMsgErrInfo_Bus -> CtAp_ComMErr.RTE_R_ComM_ADCUDAMsgErrInfo_Bus
    connect CtAp_CANHandler.RTE_P_ComM_IBSAPSMsgErrInfo_Bus -> CtAp_ComMErr.RTE_R_ComM_IBSAPSMsgErrInfo_Bus
    connect CtAp_CANHandler.RTE_P_ComM_SGW16MsgErrInfo_Bus -> CtAp_ComMErr.RTE_R_ComM_SGW16MsgErrInfo_Bus
    connect CtAp_CANHandler.RTE_P_ComM_SGW17MsgErrInfo_Bus -> CtAp_ComMErr.RTE_R_ComM_SGW17MsgErrInfo_Bus
    connect CtAp_FctSftyMon.RTE_P_FctSftyMon_ActGearCfmFail_Bus -> YDF_ErrorHandler.RTE_R_FctSftyMon_ActGearCfmFail_Bus
    connect CtAp_CANHandler.RTE_P_ComM_ACUInfoUpdate -> CtAp_ErrMgmt.RTE_R_ComM_ACUInfoUpdate
    connect CtAp_CANHandler.RTE_P_ComM_BMSSts01Update -> CtAp_ErrMgmt.RTE_R_ComM_BMSSts01Update
    connect CtAp_CANHandler.RTE_P_ComM_MCUFailCodeUpdate -> CtAp_ErrMgmt.RTE_R_ComM_MCUFailCodeUpdate
    connect CtAp_CANHandler.RTE_P_ComM_PODDCDC02Update -> CtAp_ErrMgmt.RTE_R_ComM_PODDCDC02Update
    connect CtAp_CANHandler.RTE_P_ComM_PODOBCSts03Update -> CtAp_ErrMgmt.RTE_R_ComM_PODOBCSts03Update
    connect CtAp_CANHandler.RTE_P_ComM_TCU01Update -> CtAp_ErrMgmt.RTE_R_ComM_TCU01Update
    delegate CtAp_CANHandler.SG_SGW_PT_01_SigGroup <-> outer port SG_SGW_PT_01_SigGroup
    delegate CtAp_CANHandler.SG_POD_DCDC_02_SigGroup <-> outer port SG_POD_DCDC_02_SigGroup
    delegate CtAp_CANHandler.SG_SGW_Time_SigGroup <-> outer port SG_SGW_Time_SigGroup
    delegate CtAp_CANHandler.SG_CGW_01_SigGroup <-> outer port SG_CGW_01_SigGroup
    delegate CtAp_CANHandler.SG_IBS_VCU_MotorControl_SigGroup_CAN <-> outer port SG_IBS_VCU_MotorControl_SigGroup
    delegate CtAp_CANHandler.SG_SGW_04_SigGroup <-> outer port SG_SGW_04_SigGroup
    delegate CtAp_CANHandler.SG_PRND_SigGroup <-> outer port SG_PRND_SigGroup
    delegate CtAp_CANHandler.SG_DCM_FR_SigGroup <-> outer port SG_DCM_FR_SigGroup
    delegate CtAp_CANHandler.SG_CGW_VIN3VER_SigGroup <-> outer port SG_CGW_VIN3VER_SigGroup
    delegate CtAp_CANHandler.SG_BMS_ErrorInfo_SigGroup <-> outer port SG_BMS_ErrorInfo_SigGroup
    delegate CtAp_CANHandler.SG_CGW_VIN2_SigGroup <-> outer port SG_CGW_VIN2_SigGroup
    delegate CtAp_CANHandler.SG_BMS_status_02_SigGroup <-> outer port SG_BMS_status_02_SigGroup
    delegate CtAp_CANHandler.SG_SGW_17_SigGroup <-> outer port SG_SGW_17_SigGroup
    delegate CtAp_CANHandler.SG_BMS_PRO_SigGroup <-> outer port SG_BMS_PRO_SigGroup
    delegate CtAp_CANHandler.SG_ACU_01_SigGroup <-> outer port SG_ACU_01_SigGroup
    delegate CtAp_CANHandler.SG_ADCU_DA_SigGroup <-> outer port SG_ADCU_DA_SigGroup
    delegate CtAp_CANHandler.SG_POD_Status_02_SigGroup <-> outer port SG_POD_Status_02_SigGroup
    delegate CtAp_CANHandler.SG_CGW_VIN1_SigGroup <-> outer port SG_CGW_VIN1_SigGroup
    delegate CtAp_CANHandler.SG_IVI_01_SigGroup <-> outer port SG_IVI_01_SigGroup
    delegate CtAp_CANHandler.SG_MCU_02_SigGroup <-> outer port SG_MCU_02_SigGroup
    delegate CtAp_CANHandler.SG_MCU_Temperature_02_SigGroup <-> outer port SG_MCU_Temperature_02_SigGroup
    delegate CtAp_CANHandler.SG_BMS_Charge_01_SigGroup <-> outer port SG_BMS_Charge_01_SigGroup
    delegate CtAp_CANHandler.SG_CGW_02_SigGroup <-> outer port SG_CGW_02_SigGroup
    delegate CtAp_CANHandler.SG_POD_OBC_STATUS_02_SigGroup <-> outer port SG_POD_OBC_STATUS_02_SigGroup
    delegate CtAp_CANHandler.SG_BMS_TCU_SigGroup <-> outer port SG_BMS_TCU_SigGroup
    delegate CtAp_CANHandler.SG_ADCU_APS_02_SigGroup <-> outer port SG_ADCU_APS_02_SigGroup
    delegate CtAp_CANHandler.SG_MCU_FailureCode_SigGroup <-> outer port SG_MCU_FailureCode_SigGroup
    delegate CtAp_CANHandler.SG_IVI_OdometerInfor_SigGroup <-> outer port SG_IVI_OdometerInfor_SigGroup
    delegate CtAp_CANHandler.SG_DCM_RL_SigGroup <-> outer port SG_DCM_RL_SigGroup
    delegate CtAp_CANHandler.SG_MCU_Temperature_01_SigGroup <-> outer port SG_MCU_Temperature_01_SigGroup
    delegate CtAp_CANHandler.SG_POD_DCDC_01_SigGroup <-> outer port SG_POD_DCDC_01_SigGroup
    delegate CtAp_CANHandler.SG_BMS_BatInfor_02_SigGroup <-> outer port SG_BMS_BatInfor_02_SigGroup
    delegate CtAp_CANHandler.SG_BMS_status_03_SigGroup <-> outer port SG_BMS_status_03_SigGroup
    delegate CtAp_CANHandler.SG_DCM_FR_02_SigGroup <-> outer port SG_DCM_FR_02_SigGroup
    delegate CtAp_CANHandler.SG_IBS_Torque_SigGroup <-> outer port SG_IBS_Torque_SigGroup
    delegate CtAp_CANHandler.SG_POD_OBC_CHRGSTATION_SigGroup <-> outer port SG_POD_OBC_CHRGSTATION_SigGroup
    delegate CtAp_CANHandler.SG_POD_OBC_STATUS_03_SigGroup <-> outer port SG_POD_OBC_STATUS_03_SigGroup
    delegate CtAp_CANHandler.SG_POD_OBC_STATUS_04_SigGroup <-> outer port SG_POD_OBC_STATUS_04_SigGroup
    delegate CtAp_CANHandler.SG_ACU_02_SigGroup <-> outer port SG_ACU_02_SigGroup
    delegate CtAp_CANHandler.SG_POD_Status_01_SigGroup <-> outer port SG_POD_Status_01_SigGroup
    delegate CtAp_CANHandler.SG_BMS_VersionInfor_SigGroup <-> outer port SG_BMS_VersionInfor_SigGroup
    delegate CtAp_CANHandler.SG_BMS_BatInfor_01_SigGroup <-> outer port SG_BMS_BatInfor_01_SigGroup
    delegate CtAp_CANHandler.SG_MCU_DeratingStatus_SigGroup <-> outer port SG_MCU_DeratingStatus_SigGroup
    delegate CtAp_CANHandler.SG_SGW_VCU_01_SigGroup <-> outer port SG_SGW_VCU_01_SigGroup
    delegate CtAp_CANHandler.SG_SGW_IBS_01_SigGroup <-> outer port SG_SGW_IBS_01_SigGroup
    delegate CtAp_CANHandler.SG_DCM_RR_SigGroup <-> outer port SG_DCM_RR_SigGroup
    delegate CtAp_CANHandler.SG_BMS_DIRelayState_SigGroup <-> outer port SG_BMS_DIRelayState_SigGroup
    delegate CtAp_CANHandler.SG_TCU_02_SigGroup <-> outer port SG_TCU_02_SigGroup
    delegate CtAp_CANHandler.SG_SGW_16_SigGroup <-> outer port SG_SGW_16_SigGroup
    delegate CtAp_CANHandler.SG_APTC_TCU_SigGroup <-> outer port SG_APTC_TCU_SigGroup
    delegate CtAp_CANHandler.SG_TCU_01_SigGroup <-> outer port SG_TCU_01_SigGroup
    delegate CtAp_CANHandler.SG_BMS_BatInfor_03_SigGroup <-> outer port SG_BMS_BatInfor_03_SigGroup
    delegate CtAp_CANHandler.SG_BMS_Charge_03_SigGroup <-> outer port SG_BMS_Charge_03_SigGroup
    delegate CtAp_CANHandler.SG_BMS_Charge_02_SigGroup <-> outer port SG_BMS_Charge_02_SigGroup
    delegate CtAp_CANHandler.SG_EVCOM_State_01_SigGroup <-> outer port SG_EVCOM_State_01_SigGroup
    delegate CtAp_CANHandler.SG_VCU_HMIsignals_02_SigGroup <-> outer port SG_VCU_HMIsignals_02_SigGroup
    delegate CtAp_CANHandler.SG_VCU_TCU_SigGroup <-> outer port SG_VCU_TCU_SigGroup
    delegate CtAp_CANHandler.SG_VCU_IBS_01_SigGroup <-> outer port SG_VCU_IBS_01_SigGroup
    delegate CtAp_CANHandler.SG_VCU_03_SigGroup <-> outer port SG_VCU_03_SigGroup
    delegate CtAp_CANHandler.SG_VCU_BMS_SigGroup <-> outer port SG_VCU_BMS_SigGroup
    delegate CtAp_CANHandler.SG_VCU_05_SigGroup <-> outer port SG_VCU_05_SigGroup
    delegate CtAp_CANHandler.SG_VCU_Chassis_01_SigGroup <-> outer port SG_VCU_Chassis_01_SigGroup
    delegate CtAp_CANHandler.SG_VCU_MCU_02_SigGroup <-> outer port SG_VCU_MCU_02_SigGroup
    delegate CtAp_CANHandler.SG_VCU_SynReq_01_SigGroup <-> outer port SG_VCU_SynReq_01_SigGroup
    delegate CtAp_CANHandler.SG_VCU_MCU_05_SigGroup <-> outer port SG_VCU_MCU_05_SigGroup
    delegate CtAp_CANHandler.SG_VCU_POD_SigGroup <-> outer port SG_VCU_POD_SigGroup
    delegate CtAp_CANHandler.SG_VCU_06_SigGroup <-> outer port SG_VCU_06_SigGroup
    delegate CtAp_CANHandler.SG_VCU_02_SigGroup <-> outer port SG_VCU_02_SigGroup
    delegate CtAp_CANHandler.SG_VCU_04_SigGroup <-> outer port SG_VCU_04_SigGroup
    delegate CtAp_CANHandler.SG_VCU_PlugInChrgInfo_SigGroup <-> outer port SG_VCU_PlugInChrgInfo_SigGroup
    delegate CtAp_CANHandler.SG_VCU_DCDC_SigGroup <-> outer port SG_VCU_DCDC_SigGroup
    delegate CtAp_CANHandler.SG_VCU_AccPedal_SigGroup <-> outer port SG_VCU_AccPedal_SigGroup
    delegate CtAp_DiagnosisApp.SG_IBS_VCU_MotorControl_SigGroup <-> outer port SG_IBS_VCU_MotorControl_SigGroup
    delegate CtAp_DCComM.SG_BMS_BatInfor_01_SigGroup <-> outer port SG_BMS_BatInfor_01_SigGroup
    delegate CtAp_DCComM.SG_BMS_BatInfor_02_SigGroup <-> outer port SG_BMS_BatInfor_02_SigGroup
    delegate CtAp_DCComM.SG_BMS_Charge_03_SigGroup <-> outer port SG_BMS_Charge_03_SigGroup
    delegate CtAp_DCComM.SG_BMS_PRO_SigGroup <-> outer port SG_BMS_PRO_SigGroup
    delegate CtAp_DCComM.SG_BMS_status_03_SigGroup <-> outer port SG_BMS_status_03_SigGroup
    delegate CtAp_DCComM.SG_BMS_TCU_SigGroup <-> outer port SG_BMS_TCU_SigGroup
    delegate CtAp_DCComM.SG_BMS_VersionInfor_SigGroup <-> outer port SG_BMS_VersionInfor_SigGroup
    delegate CtAp_DCComM.SG_POD_Status_01_SigGroup <-> outer port SG_POD_Status_01_SigGroup
    delegate CtAp_CANHandler.SG_VCU_HMIsignals_01_SigGroup <-> outer port SG_VCU_HMIsignals_01_SigGroup
    delegate CtAp_CANHandler.SG_MCU_01_SigGroup_2 <-> outer port SG_MCU_01_SigGroup
    delegate CtAp_DCComM.SG_BMS_Charge_01_SigGroup <-> outer port SG_BMS_Charge_01_SigGroup
    delegate CtAp_CANHandler.SG_VCU_MCU_03_SigGroup_1 <-> outer port SG_VCU_MCU_03_SigGroup
    connect CtAp_LINHandler.RTE_P_ComM_BSBatCrnt -> CtAp_DiagnosisApp.RTE_R_ComM_BSBatCrnt
    connect CtAp_LINHandler.RTE_P_ComM_BSBattSOC_pct -> CtAp_DiagnosisApp.RTE_R_ComM_BSBattSOC_pct
    connect CtAp_LINHandler.RTE_P_ComM_BSBattSOHInfo -> CtAp_DiagnosisApp.RTE_R_ComM_BSBattSOHInfo
    connect CtAp_VehMot.RTE_P_VehMot_VehSpdABS_kph -> CtAp_DiagnosisApp.RTE_R_VehMot_VehSpdABS_kph
    connect CtAp_LINHandler.RTE_P_ComM_FRCMsgErrDTC_Bus -> YDF_ErrorHandler.RTE_R_ComM_FRCMsgErrDTC_Bus
    connect CtAp_LINHandler.RTE_P_ComM_FRCRespErrDTC_Bus -> YDF_ErrorHandler.RTE_R_ComM_FRCRespErrDTC_Bus
    connect CtAp_LINHandler.RTE_P_ComM_FRCSplyUDcHiDTC_Bus -> YDF_ErrorHandler.RTE_R_ComM_FRCSplyUDcHiDTC_Bus
    connect CtAp_LINHandler.RTE_P_ComM_FRCSplyUDcLoDTC_Bus -> YDF_ErrorHandler.RTE_R_ComM_FRCSplyUDcLoDTC_Bus
    connect CtAp_LvMgmt.RTE_P_LvMgmt_BSBattChrgIDcHiDTC_Bus -> YDF_ErrorHandler.RTE_R_LvMgmt_BSBattChrgIDcHiDTC_Bus
    connect CtAp_LvMgmt.RTE_P_LvMgmt_BSBattSOCLoDTC_Bus -> YDF_ErrorHandler.RTE_R_LvMgmt_BSBattSOCLoDTC_Bus
    connect CtAp_LvMgmt.RTE_P_LvMgmt_BSBattTempHiDTC_Bus -> YDF_ErrorHandler.RTE_R_LvMgmt_BSBattTempHiDTC_Bus
    connect CtAp_LvMgmt.RTE_P_LvMgmt_BSBattTempLoDTC_Bus -> YDF_ErrorHandler.RTE_R_LvMgmt_BSBattTempLoDTC_Bus
    connect CtAp_LvMgmt.RTE_P_LvMgmt_BSRespErrDTC_Bus -> YDF_ErrorHandler.RTE_R_LvMgmt_BSRespErrDTC_Bus
    connect CtAp_ChassisMgmt.RTE_P_ChassisMgmt_AccrPedlPosn_pct -> CtAp_FctSftyMon.RTE_R_ChassisMgmt_AccrPedlPosn_pct
    connect CtAp_RngEstimn.RTE_P_RngEstimn_MilgLowRmn -> CtAp_CANHandler.RTE_R_RngEstimn_MilgLowRmn
    delegate CtAp_CANHandler.SG_SGW_FVSynchronization_01_SigGrou <-> outer port SG_SGW_FVSynchronization_01_SigGrou_1
    delegate YDF_MileageCalculation.SG_CGW_01_SigGroup_MilCal <-> outer port SG_CGW_01_SigGroup
    connect YDF_ErrorHandler.DCCAN_BusoffStatus -> CtAp_ComMErr.RTE_R_DCCAN_BusoffStatus_BusoffStatus
    connect CtAp_CANHandler.RTE_P_MilCal_VCU_VehicleSpeedValid -> YDF_MileageCalculation
    connect CtAp_CANHandler.RTE_P_MilCal_VCU_VehicleSpeed -> YDF_MileageCalculation
    delegate CtAp_CANHandler.SG_ACU_info_SigGroup <-> outer port SG_ACU_info_SigGroup_1
    delegate CtAp_CANHandler.SG_ADCU_ACC_02_SigGroup <-> outer port SG_ADCU_ACC_02_SigGroup_1
    delegate CtAp_CANHandler.SG_ADCU_APS_01_SigGroup <-> outer port SG_ADCU_APS_01_SigGroup_1
    delegate CtAp_CANHandler.SG_BCM_05_SigGroup <-> outer port SG_BCM_05_SigGroup_1
    delegate CtAp_CANHandler.SG_BCM_06_SigGroup <-> outer port SG_BCM_06_SigGroup_1
    delegate CtAp_CANHandler.SG_ADCU_AEB_01_SigGroup <-> outer port SG_ADCU_AEB_01_SigGroup
    delegate CtAp_CANHandler.SG_BMS_CellTemp_SigGroup <-> outer port SG_BMS_CellTemp_SigGroup_1
    delegate CtAp_DCComM.SG_BMS_CellTemp_SigGroup <-> outer port SG_BMS_CellTemp_SigGroup_1
    delegate CtAp_CANHandler.SG_BMS_CellVoltage_SigGroup <-> outer port SG_BMS_CellVoltage_SigGroup_1
    delegate CtAp_DCComM.SG_BMS_CellVoltage_SigGroup <-> outer port SG_BMS_CellVoltage_SigGroup_1
    delegate CtAp_CANHandler.SG_BMS_status_01_SigGroup <-> outer port SG_BMS_status_01_SigGroup_1
    delegate CtAp_CANHandler.SG_DCM_FL_02_SigGroup <-> outer port SG_DCM_FL_02_SigGroup_1
    delegate CtAp_CANHandler.SG_IBS_APS_SigGroup <-> outer port SG_IBS_APS_SigGroup_1
    delegate CtAp_CANHandler.SG_IBS_Status_{02..06}_SigGroup <-> outer port SG_IBS_Status_{02..06}_SigGroup_1
    delegate CtAp_CANHandler.SG_IBS_WheelSpeed_01_SigGroup <-> outer port SG_IBS_WheelSpeed_01_SigGroup_1
    delegate CtAp_CANHandler.SG_IBS_WheelSpeed_02_SigGroup <-> outer port SG_IBS_WheelSpeed_02_SigGroup_1
    delegate CtAp_CANHandler.SG_SGW_01_SigGroup <-> outer port SG_SGW_01_SigGroup_1
    delegate CtAp_CANHandler.SG_BMS_status_04_SigGroup <-> outer port SG_BMS_status_04_SigGroup
    delegate CtAp_CANHandler.SG_IBS_Status_01_SigGroup <-> outer port SG_IBS_Status_01_SigGroup
    delegate CtAp_CANHandler.SG_IBS_ACC_SigGroup <-> outer port SG_IBS_ACC_SigGroup_1
    delegate CtAp_LINHandler.VCU_BS_IndicatorLightSts_LIN00 <-> outer port VCU_BS_IndicatorLightSts_LIN00
    delegate CtAp_LINHandler.VCU_IBS_EBDFault_LIN00 <-> outer port VCU_IBS_EBDFault_LIN00
    delegate CtAp_LINHandler.VCU_IBS_RollerbenchMode_LIN00 <-> outer port VCU_IBS_RollerbenchMode_LIN00
    delegate CtAp_LINHandler.VCU_BCM_FLSeatBeltRemindReq_LIN00 <-> outer port VCU_BCM_FLSeatBeltRemindReq_LIN00
    delegate CtAp_LINHandler.VCU_DCM_RR_DoorRRSts_LIN00 <-> outer port VCU_DCM_RR_DoorRRSts_LIN00
    delegate CtAp_LINHandler.VCU_DCM_FL_DoorFLSts_LIN00 <-> outer port VCU_DCM_FL_DoorFLSts_LIN00
    delegate CtAp_LINHandler.VCU_BCM_RLSeatBeltRemindReq_LIN00 <-> outer port VCU_BCM_RLSeatBeltRemindReq_LIN00
    delegate CtAp_LINHandler.VCU_Batt_U0_Max_LIN00 <-> outer port VCU_Batt_U0_Max_LIN00
    delegate CtAp_LINHandler.VCU_BattNomC20_LIN00 <-> outer port VCU_BattNomC20_LIN00
    delegate CtAp_LINHandler.VCU_ACU_DriverWarningLampSts_LIN00 <-> outer port VCU_ACU_DriverWarningLampSts_LIN00
    delegate CtAp_LINHandler.VCU_ACU_PassengerWarningLampSts_LIN00 <-> outer port VCU_ACU_PassengerWarningLampSts_LIN00
    delegate CtAp_LINHandler.VCU_ACU_PassengerAirbagSts_LIN00 <-> outer port VCU_ACU_PassengerAirbagSts_LIN00
    delegate CtAp_LINHandler.VCU_DCDCFail_LIN_LIN00 <-> outer port VCU_DCDCFail_LIN_LIN00
    delegate CtAp_LINHandler.VCU_Batt_U0_Min_LIN00 <-> outer port VCU_Batt_U0_Min_LIN00
    delegate CtAp_LINHandler.VCU_HVBatCriFail_LIN_LIN00 <-> outer port VCU_HVBatCriFail_LIN_LIN00
    delegate CtAp_LINHandler.VCU_IBSClrDiagInf_LIN00 <-> outer port VCU_IBSClrDiagInf_LIN00
    delegate CtAp_LINHandler.VCU_DCM_FR_DoorFRSts_LIN00 <-> outer port VCU_DCM_FR_DoorFRSts_LIN00
    delegate CtAp_LINHandler.VCU_BCM_FRSeatBeltRemindReq_LIN00 <-> outer port VCU_BCM_FRSeatBeltRemindReq_LIN00
    delegate CtAp_LINHandler.VCU_BattType_LIN00 <-> outer port VCU_BattType_LIN00
    delegate CtAp_LINHandler.VCU_HVBatOvrTemp_LIN_LIN00 <-> outer port VCU_HVBatOvrTemp_LIN_LIN00
    delegate CtAp_LINHandler.VCU_DCM_RL_DoorRLSts_LIN00 <-> outer port VCU_DCM_RL_DoorRLSts_LIN00
    delegate CtAp_LINHandler.VCU_IBS_BrakeFluidWarning_LIN00 <-> outer port VCU_IBS_BrakeFluidWarning_LIN00
    delegate CtAp_LINHandler.VCU_CGW_VehicleState_LIN00 <-> outer port VCU_CGW_VehicleState_LIN00
    delegate CtAp_LINHandler.VCU_IBS_SystemStatus_LIN00 <-> outer port VCU_IBS_SystemStatus_LIN00
    delegate CtAp_LINHandler.VCU_HstTempDataRqTrg_LIN00 <-> outer port VCU_HstTempDataRqTrg_LIN00
    delegate CtAp_LINHandler.VCU_BCM_RRSeatBeltRemindReq_LIN00 <-> outer port VCU_BCM_RRSeatBeltRemindReq_LIN00
    delegate CtAp_LINHandler.VCU_IVI_VrState_LIN00 <-> outer port VCU_IVI_VrState_LIN00
    delegate CtAp_LINHandler.VCU_ACU_WarningLampSts_LIN00 <-> outer port VCU_ACU_WarningLampSts_LIN00
    delegate CtAp_LINHandler.VCU_DriveMotOvrTemp_LIN_LIN00 <-> outer port VCU_DriveMotOvrTemp_LIN_LIN00
    delegate YDF_ErrorHandler.VCU_DTC_Num <-> outer port SG_VCU_DiagInfor_SigGroup
    connect CtAp_CANHandler.RTE_P_ComM_IBSPlgrPrs_mm -> CtAp_ChassisMgmt.RTE_R_ComM_IBSPlgrPrs_mm
    connect CtAp_CANHandler.RTE_P_ComM_BMSBattMaxChrgnUDc_V -> CtAp_ChrMgmt.RTE_R_ComM_BMSBattMaxChrgnUDc_V
    connect CtAp_VehMot.RTE_P_VehMot_SlopGrd_pct -> CtAp_FctSftyMon.RTE_R_VehMot_SlopGrd_pct
    connect CtAp_CANHandler.RTE_P_ComM_IBSTqMsgErrInfo_Bus -> CtAp_GearMgmt.RTE_R_ComM_IBSTqMsgErrInfo_Bus
    connect CtAp_ChassisMgmt.RTE_P_ChassisMgmt_BrkRgnActv_Flg -> CtAp_TorqPahMgmt.RTE_R_ChassisMgmt_BrkRgnActv_Flg
    connect CtAp_ChassisMgmt.RTE_P_ChassisMgmt_IBSApsReqTqActv_Flg -> CtAp_TorqPahMgmt.RTE_R_ChassisMgmt_IBSApsReqTqActv_Flg
    connect CtAp_ChassisMgmt.RTE_P_ChassisMgmt_IBSVlcReqTqActv_Flg -> CtAp_TorqPahMgmt.RTE_R_ChassisMgmt_IBSVlcReqTqActv_Flg
    connect YDF_SecOC.RTE_P_SecOC_BCM_Immo_State_YDF -> CtAp_CANHandler.RTE_R_SecOC_BCM_Immo_State_YDF
    connect YDF_SecOC.RTE_P_SecOC_BCM_Authentication_YDF -> CtAp_CANHandler.RTE_R_SecOC_BCM_Authentication_YDF
    delegate CtAp_LINHandler.VCU_IVI_BulbCheckStsLIN01 <-> outer port VCU_IVI_BulbCheckStsLIN01
    delegate CtAp_LINHandler.Resp_Error_LIN01 <-> outer port Resp_Error_LIN01
    delegate CtAp_LINHandler.SOH_LIN01 <-> outer port SOH_LIN01
    delegate CtAp_LINHandler.I_BATT_LIN01 <-> outer port I_BATT_LIN01
    delegate CtAp_LINHandler.U_BATT_LIN01 <-> outer port U_BATT_LIN01
    delegate CtAp_LINHandler.IBATT_QUIESCENT_LIN01 <-> outer port IBATT_QUIESCENT_LIN01
    delegate CtAp_LINHandler.I_RANGE_LIN01 <-> outer port I_RANGE_LIN01
    delegate CtAp_LINHandler.SOC_LIN01 <-> outer port SOC_LIN01
    delegate CtAp_LINHandler.T_BATT_LIN01 <-> outer port T_BATT_LIN01
    delegate CtAp_LINHandler.ChargeCurrWU_Ena_LIN01 <-> outer port ChargeCurrWU_Ena_LIN01
    delegate CtAp_LINHandler.SOCWU_Ena_LIN01 <-> outer port SOCWU_Ena_LIN01
    delegate CtAp_LINHandler.DisChargeCurrWU_Treshold_LIN01 <-> outer port DisChargeCurrWU_Treshold_LIN01
    delegate CtAp_LINHandler.SOCWU_Treshold_LIN01 <-> outer port SOCWU_Treshold_LIN01
    delegate CtAp_LINHandler.DisChargeCurrWU_Ena_LIN01 <-> outer port DisChargeCurrWU_Ena_LIN01
    delegate CtAp_LINHandler.ChargeCurrWU_Treshold_LIN01 <-> outer port ChargeCurrWU_Treshold_LIN01
    connect CtAp_LINHandler.RTE_P_ComM_BSHCrnt -> CtAp_CANHandler.RTE_R_ComM_BSHCrnt
    connect CtAp_LINHandler.RTE_P_ComM_BSQuiescentCurrent -> CtAp_CANHandler.RTE_R_ComM_BSQuiescentCurrent
    connect CtAp_CANHandler.RTE_P_ComM_BMSNegRlySts_Enum -> CtAp_DCChrMgmt.RTE_R_ComM_BMSNegRlySts_Enum
    connect CtAp_CANHandler.RTE_P_ComM_BMSPosRlySts_Enum -> CtAp_DCChrMgmt.RTE_R_ComM_BMSPosRlySts_Enum
    connect CtAp_DCChrMgmt.RTE_P_DCChrMgmt_MaxChrgIDc_A -> CtAp_EgyMgmt.RTE_R_DCChrMgmt_MaxChrgIDc_A
    connect CtAp_DCChrMgmt.RTE_P_DCChrMgmt_MaxChrgUDc_V -> CtAp_EgyMgmt.RTE_R_DCChrMgmt_MaxChrgUDc_V
    connect CtAp_TorqPahMgmt.RTE_P_TorqPahMgmt_TqLmtFltLampRq -> CtAp_ErrMgmt.RTE_R_TorqPahMgmt_TqLmtFltLampRq
    connect CtAp_VehMot.RTE_P_VehMot_VehSpdVld_Flg -> CtAp_HvMgmt.RTE_R_VehMot_VehSpdVld_Flg
    connect CtAp_CANHandler.RTE_P_ComM_IVIBuldChkStsInfo -> CtAp_LINHandler.RTE_R_ComM_IVIBuldChkStsInfo
    connect CtAp_LINHandler.RTE_P_ComM_BS01_IsUpdated -> CtAp_LvMgmt.RTE_R_ComM_BS01_IsUpdated
    connect CtAp_LINHandler.RTE_P_ComM_BSBattIDcInfo -> CtAp_LvMgmt.RTE_R_ComM_BSBattIDcInfo
    connect CtAp_LINHandler.RTE_P_ComM_BSBattTempInfo -> CtAp_LvMgmt.RTE_R_ComM_BSBattTempInfo
    connect CtAp_LINHandler.RTE_P_ComM_BSBatVltHlResInfo -> CtAp_LvMgmt.RTE_R_ComM_BSBatVltHlResInfo
    connect CtAp_CANHandler.RTE_P_ComM_ACU02MsgErrInfo_Bus -> CtAp_VehMot.RTE_R_ComM_ACU02MsgErrInfo_Bus
    delegate CtAp_LINHandler.SOF_V2_LIN01 <-> outer port SOF_V2_LIN01
    delegate CtAp_LINHandler.SOF_V1_LIN01 <-> outer port SOF_V1_LIN01
    connect CtAp_LINHandler.RTE_P_ComM_BSBattTempInfo -> CtAp_DiagnosisApp.RTE_R_ComM_BSBattTempInfo
    connect CtAp_LINHandler.RTE_P_ComM_BSHCrnt -> CtAp_DiagnosisApp.RTE_R_ComM_BSHCrnt
    connect CtAp_LINHandler.RTE_P_ComM_BSSOFV1Info -> CtAp_DiagnosisApp.RTE_R_ComM_BSSOFV1Info
    connect CtAp_LINHandler.RTE_P_ComM_BSSOFV2Info -> CtAp_DiagnosisApp.RTE_R_ComM_BSSOFV2Info
    delegate CtAp_CANHandler.SG_IVI_03_SigGroup <-> outer port SG_IVI_03_SigGroup
    delegate CtAp_CANHandler.SG_VCU_HMIsignals_03_SigGroup_1 <-> outer port SG_VCU_HMIsignals_03_SigGroup
    connect YDF_WakeUp_Swc.RTE_P_Ecu_SelfWakeStatus_SelfWake -> CtAp_LvMgmt.RTE_R_Ecu_SelfWakeStatus_SelfWake
    delegate CtAp_DCComM.BST_AbortChargparameter <-> outer port BST_AbortChargparameter
    connect CtAp_VehMot.RTE_P_VehMot_VehSpdVld_Flg -> CtAp_ChrMgmt.RTE_R_VehMot_VehSpdVld_Flg
    connect CtAp_ModMgmt.RTE_P_ModMgmt_ActDrvMod_Enum -> CtAp_FctSftyMon.RTE_R_ModMgmt_ActDrvMod_Enum
    connect CtAp_ChrMgmt.RTE_P_ChrMgmt_ChrgSts_Enum -> CtAp_RngEstimn.RTE_R_ChrMgmt_ChrgSts_Enum
    connect CtAp_CANHandler.RTE_P_ComM_DCMFRAmbTempInfo -> CtAp_RngEstimn.RTE_R_ComM_DCMFRAmbTempInfo
    connect CtAp_CANHandler.RTE_P_ComM_ACUCrashOutpSts_Enum -> CtAp_DiagnosisApp.RTE_R_ComM_ACUCrashOutpSts_Enum
    connect CtAp_CANHandler.RTE_P_ComM_BMSErrLvl_Enum -> CtAp_DiagnosisApp.RTE_R_ComM_BMSErrLvl_Enum
    connect CtAp_CANHandler.RTE_P_ComM_BMSHVILSts_Flg -> CtAp_DiagnosisApp.RTE_R_ComM_BMSHVILSts_Flg
    connect CtAp_CANHandler.RTE_P_ComM_BMSInslaErrLvl_Enum -> CtAp_DiagnosisApp.RTE_R_ComM_BMSInslaErrLvl_Enum
    connect CtAp_CANHandler.RTE_P_ComM_DCDCErrLvl_Enum -> CtAp_DiagnosisApp.RTE_R_ComM_DCDCErrLvl_Enum
    connect CtAp_CANHandler.RTE_P_ComM_MCUErrLvl_Enum -> CtAp_DiagnosisApp.RTE_R_ComM_MCUErrLvl_Enum
    connect CtAp_CANHandler.RTE_P_ComM_OBCErrLvl_Enum -> CtAp_DiagnosisApp.RTE_R_ComM_OBCErrLvl_Enum
    connect CtAp_CANHandler.RTE_P_ComM_TCUErrLvl_Enum -> CtAp_DiagnosisApp.RTE_R_ComM_TCUErrLvl_Enum
    connect CtAp_ErrMgmt.RTE_P_ErrMgmt_VCUHVILErr_Flg -> CtAp_DiagnosisApp.RTE_R_ErrMgmt_VCUHVILErr_Flg
    connect CtAp_RngEstimn.RTE_RP_RngEstimnFormual2 -> YDF_NVMgmt.RTE_RP_RngEstimnFormual2
    connect CtAp_CANHandler.RTE_P_ComM_EPSSteerGearAg -> CtAp_ChassisMgmt.RTE_R_ComM_EPSSteerGearAg
    connect CtAp_CANHandler.RTE_P_ComM_EPSSteerGearAgVld -> CtAp_ChassisMgmt.RTE_R_ComM_EPSSteerGearAgVld
    connect CtAp_CANHandler.RTE_P_ComM_MotActSpd_rpm -> CtAp_ChassisMgmt.RTE_R_ComM_MotActSpd_rpm
    connect CtAp_CANHandler.RTE_P_ComM_WarnLampStsInfo -> CtAp_LINHandler.RTE_R_ComM_WarnLampStsInfo
    delegate CtAp_CANHandler.SG_EPS_CONV_SigGroup <-> outer port SG_EPS_CONV_SigGroup
    delegate CtAp_DiagnosisApp.SOC_LIN01 <-> outer port SOC_LIN01
    connect CtAp_VehMot.RTE_P_VehMot_VehSpd_kph -> YDF_MileageCalculation.RTE_R_MilCal_VehMot_VehSpd_kph
    connect CtAp_VehMot.RTE_P_VehMot_VehSpdVld_Flg -> YDF_MileageCalculation.RTE_R_MilCal_VehMot_VehSpdVld_Flg
